CM_ "AUTOGENERATED FILE, DO NOT EDIT";

CM_ "hyundai_reversed_ccnc_canfd.dbc starts here";
VERSION ""

NS_ :

BS_:

BU_: XXX CAMERA FRONT_RADAR ADRV APRK

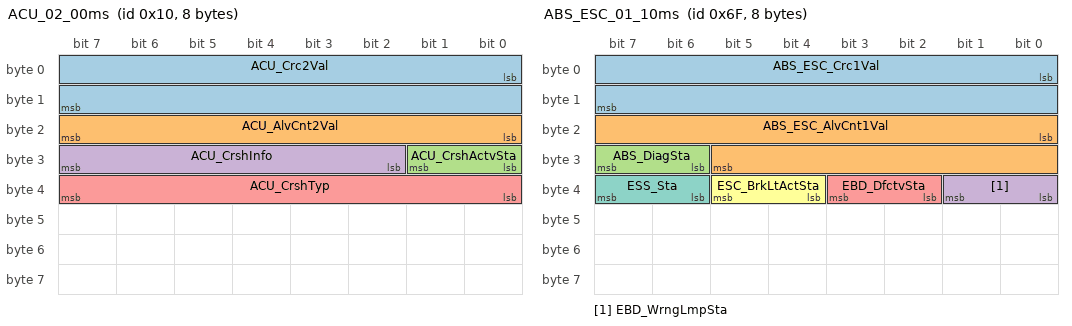
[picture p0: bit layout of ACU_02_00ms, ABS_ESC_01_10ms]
BO_ 16 ACU_02_00ms: 8 XXX
 SG_ ACU_Crc2Val : 0|16@1+ (1,0) [0|65535] "" XXX
 SG_ ACU_AlvCnt2Val : 16|8@1+ (1,0) [0|255] "" XXX
 SG_ ACU_CrshActvSta : 24|2@1+ (1,0) [0|3] "" XXX
 SG_ ACU_CrshInfo : 26|6@1+ (1,0) [0|63] "" XXX
 SG_ ACU_CrshTyp : 32|8@1+ (1,0) [0|255] "" XXX

BO_ 53 VCU_01_10ms: 32 XXX
 SG_ VCU_Crc1Val : 0|16@1+ (1,0) [0|65535] "" XXX
 SG_ VCU_AlvCnt1Val : 16|8@1+ (1,0) [0|255] "" XXX
 SG_ VCU_RdySta : 24|2@1+ (1,0) [0|3] "" XXX
 SG_ VCU_StartKeyHoldSta : 26|2@1+ (1,0) [0|3] "" XXX
 SG_ VCU_EvDrvRdySta : 28|2@1+ (1,0) [0|3] "" XXX
 SG_ VCU_MotPwrEnReq : 30|2@1+ (1,0) [0|3] "" XXX
 SG_ VCU_GearPosSta : 32|4@1+ (1,0) [0|15] "" XXX
 SG_ VCU_LdcInhReq : 36|2@1+ (1,0) [0|3] "" XXX
 SG_ VCU_MainRlyOffReq : 38|2@1+ (1,0) [0|3] "" XXX
 SG_ VCU_AccPedDepVal : 40|8@1+ (1,0) [0|255] "" XXX
 SG_ VCU_FatcOperPermSta : 48|2@1+ (1,0) [0|3] "" XXX
 SG_ VCU_DrvCycSta : 50|2@1+ (1,0) [0|3] "" XXX
 SG_ VCU_CltActOpSta : 52|4@1+ (1,0) [0|15] "" XXX
 SG_ VCU_WhlSpdSnsrAlvReq : 56|2@1+ (1,0) [0|3] "" XXX
 SG_ VCU_DrvModOpSta : 58|6@1+ (1,0) [0|63] "" XXX
 SG_ VCU_FatcPwrUseVal : 64|8@1+ (1,0) [0|255] "" XXX
 SG_ VCU_WhlDemTqVal : 72|16@1+ (1,0) [0|65535] "" XXX
 SG_ VCU_McuAntiJerkInhFrntSta : 88|2@1+ (1,0) [0|3] "" XXX
 SG_ VCU_McuAntiJerkInhRearSta : 90|2@1+ (1,0) [0|3] "" XXX
 SG_ VCU_McuPwrLatchHoldReq : 92|2@1+ (1,0) [0|3] "" XXX
 SG_ VCU_ScuParkReq : 94|2@1+ (1,0) [0|3] "" XXX
 SG_ VCU_MotTqCmdFrntVal : 96|14@1+ (1,0) [0|16383] "" XXX
 SG_ VCU_ScuKeepWakeReq : 110|2@1+ (1,0) [0|3] "" XXX
 SG_ VCU_MotTqCmdRearVal : 112|14@1+ (1,0) [0|16383] "" XXX
 SG_ VCU_FmcuZeroTqOfsReq : 126|2@1+ (1,0) [0|3] "" XXX
 SG_ VCU_EcmSeqSta : 128|8@1+ (1,0) [0|255] "" XXX
 SG_ VCU_EcmDiagSta : 136|8@1+ (1,0) [0|255] "" XXX
 SG_ VCU_CltActDiagSta : 144|8@1+ (1,0) [0|255] "" XXX
 SG_ VCU_CltActDrvCrntVal : 152|12@1+ (1,0) [0|4095] "" XXX
 SG_ VCU_CltActPosStrokeVal : 164|12@1+ (1,0) [0|4095] "" XXX
 SG_ VCU_MainBattTypeSta : 176|2@1+ (1,0) [0|3] "" XXX
 SG_ VCU_MainBattTypeLrnSta : 178|2@1+ (1,0) [0|3] "" XXX
 SG_ VCU_WarmupCycSta : 180|2@1+ (1,0) [0|3] "" XXX
 SG_ VCU_FatcPermPwrVal : 182|10@1+ (1,0) [0|1023] "" XXX
 SG_ VCU_GearPosStaDisp : 192|3@1+ (1,0) [0|7] "" XXX
 SG_ VCU_VgsVirSoundBackFireIndex : 218|6@1+ (1,0) [0|63] "" XXX
 SG_ VCU_VgsVirEngSpdRpmVal : 224|16@1+ (1,0) [0|65535] "" XXX
 SG_ VCU_VgsVirSoundVolume : 240|8@1+ (1,0) [0|255] "" XXX
 SG_ VCU_VgsVirGearStep : 248|8@1+ (1,0) [0|255] "" XXX

BO_ 64 TCU_01_10ms: 32 XXX
 SG_ TCU_Crc1Val : 0|16@1+ (1,0) [0|65535] "" XXX
 SG_ TCU_AlvCnt1Val : 16|8@1+ (1,0) [0|255] "" XXX
 SG_ TCU_GearSlctDis : 32|3@1+ (1,0) [0|7] "" XXX
 SG_ TCU_Typ : 36|4@1+ (1,0) [0|15] "" XXX
 SG_ TCU_TqRdctnVal : 40|16@1+ (1,0) [0|65535] "" XXX
 SG_ TCU_GearStepTyp : 56|4@1+ (1,0) [0|15] "" XXX
 SG_ TCU_GearShftSta : 60|2@1+ (1,0) [0|3] "" XXX
 SG_ TCU_TqCnvrtrSta : 62|2@1+ (1,0) [0|3] "" XXX
 SG_ TCU_CurrGearSta : 64|4@1+ (1,0) [0|15] "" XXX
 SG_ TCU_TrgtGearSta : 68|4@1+ (1,0) [0|15] "" XXX
 SG_ TCU_CluTrgtGearSta : 72|4@1+ (1,0) [0|15] "" XXX
 SG_ TCH_EngTrgtGearSta : 76|4@1+ (1,0) [0|15] "" XXX
 SG_ TCU_EngTqLimVal : 80|16@1+ (1,0) [0|65535] "" XXX
 SG_ TCU_VehSpdKphVal : 96|8@1+ (1,0) [0|255] "" XXX
 SG_ TCU_DcmlVehSpdKphVal : 104|8@1+ (1,0) [0|255] "" XXX
 SG_ TCU_SprkRtrdReq : 112|8@1+ (1,0) [0|255] "" XXX
 SG_ TCU_EngRpmDisSta : 120|2@1+ (1,0) [0|3] "" XXX
 SG_ TCU_GearLmpBlnkngReq : 122|2@1+ (1,0) [0|3] "" XXX
 SG_ TCU_FuelCutInhbtReq : 124|2@1+ (1,0) [0|3] "" XXX
 SG_ TCU_IdleUpReq : 126|2@1+ (1,0) [0|3] "" XXX
 SG_ TCU_EngRpmDis : 128|16@1+ (1,0) [0|65535] "" XXX
 SG_ TCU_SlpVal : 144|6@1+ (1,0) [0|63] "" XXX
 SG_ TCU_EngSpdIncReq : 150|2@1+ (1,0) [0|3] "" XXX
 SG_ TCU_ObdSta : 152|3@1+ (1,0) [0|7] "" XXX
 SG_ TCU_SprtyIndxSta : 155|5@1+ (1,0) [0|31] "" XXX
 SG_ TCU_DrvngModDis : 160|3@1+ (1,0) [0|7] "" XXX
 SG_ TCU_DrvngModReq : 163|3@1+ (1,0) [0|7] "" XXX
 SG_ TCU_SmrtShftSta : 166|2@1+ (1,0) [0|3] "" XXX
 SG_ TCU_LupTrgtEngSpdVal : 168|8@1+ (1,0) [0|255] "" XXX
 SG_ TCU_FrtStcShftSta : 176|2@1+ (1,0) [0|3] "" XXX
 SG_ TCU_IsgInhbtReq : 178|2@1+ (1,0) [0|3] "" XXX
 SG_ TCU_CdaInhbtReq : 180|2@1+ (1,0) [0|3] "" XXX
 SG_ TCU_BrkOnReq : 182|2@1+ (1,0) [0|3] "" XXX
 SG_ TCU_TqGrdntLimVal : 184|8@1+ (1,0) [0|255] "" XXX
 SG_ TCU_NetrlCtrlSta : 192|2@1+ (1,0) [0|3] "" XXX
 SG_ TCU_ShftPtrnSta : 194|4@1+ (1,0) [0|15] "" XXX
 SG_ TCU_VgisInhbtReq : 198|2@1+ (1,0) [0|3] "" XXX
 SG_ TCU_EngTqIncReqVal : 200|12@1+ (1,0) [0|4095] "" XXX
 SG_ TCU_EPBReq : 212|4@1+ (1,0) [0|15] "" XXX

BO_ 69 GEAR: 24 XXX
 SG_ CHECKSUM : 0|16@1+ (1,0) [0|65535] "" XXX
 SG_ COUNTER : 16|8@1+ (1,0) [0|255] "" XXX
 SG_ GEAR : 44|3@1+ (1,0) [0|7] "" XXX

BO_ 74 IMU_01_10ms: 8 XXX
 SG_ IMU_Crc1Val : 0|16@1+ (1,0) [0|65535] "" XXX
 SG_ IMU_AlvCnt1Val : 16|8@1+ (1,0) [0|255] "" XXX
 SG_ IMU_YawSigSta : 24|4@1+ (1,0) [0|15] "" XXX
 SG_ IMU_LatAccelSigSta : 28|4@1+ (1,0) [0|15] "" XXX
 SG_ IMU_LongAccelSigSta : 32|4@1+ (1,0) [0|15] "" XXX
 SG_ IMU_VerAccelSigSta : 36|4@1+ (1,0) [0|15] "" XXX
 SG_ IMU_McuVoltSta : 40|4@1+ (1,0) [0|15] "" XXX
 SG_ IMU_AcuRstSta : 44|4@1+ (1,0) [0|15] "" XXX
 SG_ IMU_SnsrTyp : 48|8@1+ (1,0) [0|255] "" XXX
 SG_ IMU_RollSigSta : 56|8@1+ (1,0) [0|255] "" XXX
 SG_ IMU_YawRtVal : 64|16@1+ (1,0) [0|65535] "" XXX
 SG_ IMU_LatAccelVal : 80|16@1+ (1,0) [0|65535] "" XXX
 SG_ IMU_LongAccelVal : 96|16@1+ (1,0) [0|65535] "" XXX
 SG_ IMU_SnsrTempVal : 112|16@1+ (1,0) [0|65535] "" XXX
 SG_ IMU_SeralNumVal : 128|64@1+ (1,0) [0|1.84467440737096e+19] "" XXX
 SG_ IMU_RollRtVal : 192|16@1+ (1,0) [0|65535] "" XXX
 SG_ IMU_VerAccelVal : 208|8@1+ (1,0) [0|255] "" XXX

BO_ 80 LKAS: 16 XXX
 SG_ CHECKSUM : 0|16@1+ (1,0) [0|65535] "" XXX
 SG_ COUNTER : 16|8@1+ (1,0) [0|255] "" XXX
 SG_ LKA_MODE : 24|3@1+ (1,0) [0|7] "" XXX
 SG_ NEW_SIGNAL_1 : 27|2@1+ (1,0) [0|255] "" XXX
 SG_ LKA_WARNING : 32|1@1+ (1,0) [0|1] "" XXX
 SG_ LKA_ICON : 38|2@1+ (1,0) [0|255] "" XXX
 SG_ FCA_SYSWARN : 40|1@0+ (1,0) [0|1] "" XXX
 SG_ TORQUE_REQUEST : 41|11@1+ (1,-1024) [0|4095] "" XXX
 SG_ STEER_REQ : 52|1@1+ (1,0) [0|1] "" XXX
 SG_ LFA_BUTTON : 56|1@1+ (1,0) [0|255] "" XXX
 SG_ LKA_ASSIST : 62|1@1+ (1,0) [0|1] "" XXX
 SG_ STEER_MODE : 65|3@1+ (1,0) [0|1] "" XXX
 SG_ NEW_SIGNAL_2 : 70|2@0+ (1,0) [0|3] "" XXX
 SG_ HAS_LANE_SAFETY : 80|1@0+ (1,0) [0|1] "" XXX
 SG_ NEW_SIGNAL_3 : 111|8@0+ (1,0) [0|255] "" XXX

BO_ 81 ADRV_0x51: 32 ADRV
 SG_ CHECKSUM : 0|16@1+ (1,0) [0|65535] "" XXX
 SG_ COUNTER : 16|8@1+ (1,0) [0|255] "" XXX

BO_ 96 ESC_01_10ms: 32 XXX
 SG_ ESC_Crc1Val : 0|16@1+ (1,0) [0|65535] "" XXX
 SG_ ESC_AlvCnt1Val : 16|8@1+ (1,0) [0|255] "" XXX
 SG_ TCS_OffLmpSta : 42|2@1+ (1,0) [0|3] "" XXX
 SG_ ESC_OffTempSta : 44|2@1+ (1,0) [0|3] "" XXX
 SG_ ESC_OffSwSta : 46|2@1+ (1,0) [0|3] "" XXX
 SG_ DBC_WrngLmpSta : 48|2@1+ (1,0) [0|3] "" XXX
 SG_ DBC_FuncLmpSta : 50|2@1+ (1,0) [0|3] "" XXX
 SG_ DBC_ClusterDis : 52|2@1+ (1,0) [0|3] "" XXX
 SG_ ESC_SprtLmpSta : 54|2@1+ (1,0) [0|3] "" XXX
 SG_ ESC_BrkCtrlSta : 56|22@1+ (1,0) [0|4194303] "" XXX
 SG_ TCS_PreActvSta : 78|2@1+ (1,0) [0|3] "" XXX
 SG_ DBC_Sta : 80|8@1+ (1,0) [0|255] "" XXX
 SG_ HAC_Sta : 88|6@1+ (1,0) [0|63] "" XXX
 SG_ BJD_Flag : 94|1@1+ (1,0) [0|1] "" XXX
 SG_ TCS_SlwTqFlag : 95|5@1+ (1,0) [0|31] "" XXX
 SG_ TCS_GearShftCharacteristicVal : 100|2@1+ (1,0) [0|3] "" XXX
 SG_ TCS_ManufacturerVal : 102|18@1+ (1,0) [0|262143] "" XXX
 SG_ TCS_SlwTqIntrvntnVal : 120|8@1+ (1,0) [0|255] "" XXX
 SG_ ESC_CylPrsrVal : 128|10@1+ (1,0) [0|65535] "" XXX
 SG_ ESC_CylPrsrSta : 144|2@1+ (1,0) [0|3] "" XXX
 SG_ ESC_CylPrsrDiagSta : 146|2@1+ (1,0) [0|3] "" XXX
 SG_ ESC_CylPrsrFlagSta : 148|1@1+ (1,0) [0|3] "" XXX
 SG_ ESC_VsmActvSta : 152|2@1+ (1,0) [0|3] "" XXX
 SG_ ESC_VsmDfctvSta : 154|2@1+ (1,0) [0|3] "" XXX
 SG_ ESC_VsmCtrlModSta : 156|4@1+ (1,0) [0|15] "" XXX
 SG_ ESC_StrTqReq : 160|16@1+ (1,0) [0|65535] "" XXX
 SG_ ESC_LongAccelOffstCalibPrmtr : 176|15@1+ (1,0) [0|32767] "" XXX
 SG_ ESC_IMURstStaAck : 191|1@1+ (1,0) [0|1] "" XXX
 SG_ AVH_Sta : 192|4@1+ (1,0) [0|15] "" XXX
 SG_ EPB_ActvReq : 196|2@1+ (1,0) [0|3] "" XXX
 SG_ EPB_StaReq : 198|10@1+ (1,0) [0|1023] "" XXX
 SG_ AVH_CluDis : 208|8@1+ (1,0) [0|255] "" XXX
 SG_ AVH_AlrmReq : 216|2@1+ (1,0) [0|3] "" XXX
 SG_ AVH_ActvStaLmpDis : 218|2@1+ (1,0) [0|3] "" XXX
 SG_ AVH_LmpDis : 220|4@1+ (1,0) [0|15] "" XXX
 SG_ AWD_CrdnShftTqLimVal : 224|16@1+ (1,0) [0|65535] "" XXX
 SG_ AWD_CltchDtyLimVal : 240|8@1+ (1,0) [0|255] "" XXX
 SG_ AWD_TransmsnTqLimModSta : 248|2@1+ (1,0) [0|3] "" XXX
 SG_ AWD_RrWhlDtyLimReq : 250|6@1+ (1,0) [0|63] "" XXX

BO_ 101 IEB_01_10ms: 32 XXX
 SG_ IEB_Crc1Val : 0|16@1+ (1,0) [0|65535] "" XXX
 SG_ IEB_AlvCnt1Val : 16|8@1+ (1,0) [0|255] "" XXX
 SG_ IEB_SrvLmpDis : 24|2@1+ (1,0) [0|3] "" XXX
 SG_ IEB_DfctvSta : 26|2@1+ (1,0) [0|3] "" XXX
 SG_ IEB_ActvSta : 28|2@1+ (1,0) [0|3] "" XXX
 SG_ IEB_DiagSta : 30|2@1+ (1,0) [0|3] "" XXX
 SG_ IEB_WrngLmpDis : 32|2@1+ (1,0) [0|3] "" XXX
 SG_ IEB_MILReq : 34|6@1+ (1,0) [0|63] "" XXX
 SG_ IEB_StrkDpthmmVal : 40|16@1- (1,0) [0|65535] "" XXX
 SG_ IEB_BrkActvSta : 56|1@1+ (1,0) [0|1] "" XXX
 SG_ BRAKE_PRESSED : 57|1@1+ (1,0) [0|3] "" XXX
 SG_ IEB_PdlTrvlSnsrFailSta : 58|2@1+ (1,0) [0|3] "" XXX
 SG_ IEB_PdlCalibSta : 60|2@1+ (1,0) [0|3] "" XXX
 SG_ IEB_BzrSta : 62|2@1+ (1,0) [0|3] "" XXX
 SG_ IEB_Sta : 64|2@1+ (1,0) [0|3] "" XXX
 SG_ IEB_SnsrFailSta : 66|2@1+ (1,0) [0|3] "" XXX
 SG_ IEB_RbsWrngLmpSta : 68|2@1+ (1,0) [0|3] "" XXX
 SG_ IEB_VacSysDfctvSta : 70|2@1+ (1,0) [0|3] "" XXX
 SG_ IEB_RegenTqLimitNmVal_Frnt : 72|16@1+ (1,0) [0|65535] "" XXX
 SG_ IEB_EstTtlBrkFrcNmVal : 88|16@1+ (1,0) [0|65535] "" XXX
 SG_ IEB_StrkDpthPcVal : 104|8@1+ (1,0) [0|255] "" XXX
 SG_ IEB_EstDpthPcVal : 112|8@1+ (1,0) [0|255] "" XXX
 SG_ IEB_AbsNGearReq : 120|2@1+ (1,0) [0|3] "" XXX
 SG_ IEB_EstBrkPdlValVldSta : 122|2@1+ (1,0) [0|3] "" XXX
 SG_ IEB_InhbtTrnstnTo4wd_Req : 124|4@1+ (1,0) [0|15] "" XXX
 SG_ IEB_RegenTqLimitNmVal_Rear : 128|24@1+ (1,0) [0|16777215] "" XXX
 SG_ IEB_TCS_Req : 152|2@1+ (1,0) [0|3] "" XXX
 SG_ IEB_RSC_Req : 154|3@1+ (1,0) [0|7] "" XXX
 SG_ TCS_TqFlag_Rear : 157|1@1+ (1,0) [0|1] "" XXX
 SG_ RSC_TqFlag_Frnt : 158|1@1+ (1,0) [0|1] "" XXX
 SG_ RSC_TqFlag_Rear : 159|9@1+ (1,0) [0|511] "" XXX
 SG_ TCS_TqIntrvntnVal_Rear : 168|8@1+ (1,0) [0|255] "" XXX
 SG_ RSC_TqIntrvntnVal_Frnt : 176|8@1+ (1,0) [0|255] "" XXX
 SG_ RSC_TqIntrvntnVal_Rear : 184|40@1+ (1,0) [0|1099511627775] "" XXX
 SG_ IEB_DriftModeSta : 224|2@1+ (1,0) [0|3] "" XXX
 SG_ IEB_DriftModeActSta : 226|6@1+ (1,0) [0|63] "" XXX

BO_ 106 TCU_02_10ms: 8 XXX
 SG_ TCU_Crc3Val : 0|16@1+ (1,0) [0|65535] "" XXX
 SG_ VI_VehImmoReq : 2|24@1+ (1,0) [0|16777215] "" XXX
 SG_ TCU_AlvCnt3Val : 16|8@1+ (1,0) [0|255] "" XXX
 SG_ TCU_WrngMsgSta : 24|13@1+ (1,0) [0|8191] "" XXX
 SG_ VSVI_AlvCntVal : 26|14@1+ (1,0) [0|16383] "" XXX
 SG_ TCU_NCCSetChk : 37|3@1+ (1,0) [0|7] "" XXX
 SG_ TCU_SmartshiftSPTIndex_Long : 40|8@1+ (1,0) [0|255] "" XXX
 SG_ SBW_WrngSndSta : 44|4@1+ (1,0) [0|15] "" XXX
 SG_ TCU_TqCnvrtrSpdVal : 48|16@1+ (1,0) [0|65535] "" XXX
 SG_ ECO_Ig3RlyDrvSta : 52|4@1+ (1,0) [0|15] "" XXX
 SG_ TCU_PrkReleaseReq : 64|2@1+ (1,0) [0|3] "" XXX
 SG_ TCU_InertiaPhaseSta : 66|2@1+ (1,0) [0|3] "" XXX
 SG_ TCU_ActvEcoRdySta : 68|2@1+ (1,0) [0|3] "" XXX
 SG_ TCU_SprtDrvRdySta : 70|4@1+ (1,0) [0|15] "" XXX
 SG_ TCU_RspaSta : 72|4@1+ (1,0) [0|15] "" XXX
 SG_ TCU_CltchDrvngTqVal : 74|10@1+ (1,0) [0|1023] "" XXX
 SG_ TCU_RspaCtrlSta : 76|8@1+ (1,0) [0|255] "" XXX
 SG_ TCU_SbwPrkSta : 84|2@1+ (1,0) [0|3] "" XXX
 SG_ TCU_StallLaunchStat : 86|2@1+ (1,0) [0|3] "" XXX
 SG_ TCU_OilPmpTrgtSpdVal : 88|8@1+ (1,0) [0|255] "" XXX
 SG_ TCU_NPosWshModSta : 91|10@1+ (1,0) [0|1023] "" XXX
 SG_ TCU_GrRatioChngProg : 96|8@1+ (1,0) [0|255] "" XXX
 SG_ TCU_PS_CurveSta : 101|1@1+ (1,0) [0|1] "" XXX
 SG_ TCU_PS_MergeSta : 102|1@1+ (1,0) [0|1] "" XXX
 SG_ TCU_PS_SLimitSta : 103|1@1+ (1,0) [0|1] "" XXX
 SG_ TCU_TgtTurSpd : 104|13@1+ (1,0) [0|8191] "" XXX
 SG_ TCU_PS_DownhillSta : 105|1@1+ (1,0) [0|1] "" XXX
 SG_ TCU_PS_StopsignSta : 106|1@1+ (1,0) [0|1] "" XXX
 SG_ TCU_PS_RoundaboutSta : 107|1@1+ (1,0) [0|1] "" XXX
 SG_ TCU_PS_OthersSta : 108|1@1+ (1,0) [0|1] "" XXX
 SG_ TCU_PS_TestDisplay : 109|4@1+ (1,0) [0|15] "" XXX
 SG_ TCU_PS_Sta : 113|2@1+ (1,0) [0|3] "" XXX
 SG_ TCU_PS_VarIcon : 115|2@1+ (1,0) [0|3] "" XXX
 SG_ TCU_PS_CoastingGuide : 117|3@1+ (1,0) [0|7] "" XXX
 SG_ TCU_NCExitBrk : 119|2@1+ (1,0) [0|3] "" XXX
 SG_ TCU_RevMatchFlag : 121|2@1+ (1,0) [0|3] "" XXX
 SG_ TCU_NCCStat : 123|5@1+ (1,0) [0|31] "" XXX
 SG_ TCU_CVTPumpLoad : 128|8@1+ (1,0) [0|255] "" XXX
 SG_ TCU_EngSpdIncRev : 136|13@1+ (1,0) [0|8191] "" XXX
 SG_ TCU_ShiftTarCls : 149|3@1+ (1,0) [0|7] "" XXX

BO_ 111 ABS_ESC_01_10ms: 8 XXX
 SG_ ABS_ESC_Crc1Val : 0|16@1+ (1,0) [0|65535] "" XXX
 SG_ ABS_ESC_AlvCnt1Val : 16|14@1+ (1,0) [0|16383] "" XXX
 SG_ ABS_DiagSta : 30|2@1+ (1,0) [0|3] "" XXX
 SG_ EBD_WrngLmpSta : 32|2@1+ (1,0) [0|3] "" XXX
 SG_ EBD_DfctvSta : 34|2@1+ (1,0) [0|3] "" XXX
 SG_ ESC_BrkLtActSta : 36|2@1+ (1,0) [0|3] "" XXX
 SG_ ESS_Sta : 38|2@1+ (1,0) [0|3] "" XXX

BO_ 112 GEAR_ALT_2: 32 XXX
 SG_ CHECKSUM : 0|16@1+ (1,0) [0|65535] "" XXX
 SG_ COUNTER : 16|8@1+ (1,0) [0|255] "" XXX
 SG_ GEAR : 60|3@1+ (1,0) [0|7] "" XXX

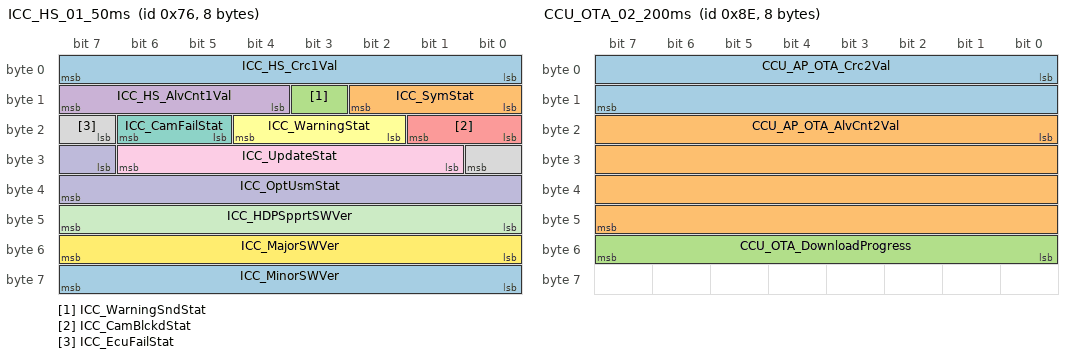
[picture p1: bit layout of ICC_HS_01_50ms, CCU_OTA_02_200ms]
BO_ 118 ICC_HS_01_50ms: 8 XXX
 SG_ ICC_HS_Crc1Val : 0|8@1+ (1,0) [0|255] "" XXX
 SG_ ICC_SymStat : 8|3@1+ (1,0) [0|7] "" XXX
 SG_ ICC_WarningSndStat : 11|1@1+ (1,0) [0|1] "" XXX
 SG_ ICC_HS_AlvCnt1Val : 12|4@1+ (1,0) [0|15] "" XXX
 SG_ ICC_CamBlckdStat : 16|2@1+ (1,0) [0|3] "" XXX
 SG_ ICC_WarningStat : 18|3@1+ (1,0) [0|7] "" XXX
 SG_ ICC_CamFailStat : 21|2@1+ (1,0) [0|3] "" XXX
 SG_ ICC_EcuFailStat : 23|2@1+ (1,0) [0|3] "" XXX
 SG_ ICC_UpdateStat : 25|6@1+ (1,0) [0|63] "" XXX
 SG_ ICC_OptUsmStat : 31|9@1+ (1,0) [0|511] "" XXX
 SG_ ICC_HDPSpprtSWVer : 40|8@1+ (1,0) [0|255] "" XXX
 SG_ ICC_MajorSWVer : 48|8@1+ (1,0) [0|255] "" XXX
 SG_ ICC_MinorSWVer : 56|8@1+ (1,0) [0|255] "" XXX

BO_ 138 CDM_HS_2_01_200ms_CDM_HS: 8 XXX
 SG_ ccIC_HU_Crc1Val : 0|0@1+ (1,0) [0|0] "" XXX
 SG_ RRPSS_Local_AlvCnt1Val : 12|0@1+ (1,0) [0|0] "" XXX
 SG_ ccIC_HU_AlvCnt1Val : 16|0@1+ (1,0) [0|0] "" XXX

BO_ 142 CCU_OTA_02_200ms: 8 XXX
 SG_ CCU_AP_OTA_Crc2Val : 0|16@1+ (1,0) [0|65535] "" XXX
 SG_ CCU_AP_OTA_AlvCnt2Val : 16|32@1+ (1,0) [0|4294967295] "" XXX
 SG_ CCU_OTA_DownloadProgress : 48|8@1+ (1,0) [0|255] "" XXX

BO_ 143 DSAU_04_200ms_DSAU: 8 XXX
 SG_ RRSAU_L_AirSptModeRValueSet : 4|0@1+ (1,0) [0|0] "" XXX
 SG_ RRSAU_L_AirSptStrRValueSet_DASU : 8|0@1+ (1,0) [0|0] "" XXX
 SG_ RRSAU_L_AirSptTimeRValueSet : 12|0@1+ (1,0) [0|0] "" XXX
 SG_ RRSAU_L_BackSoftRValueSet : 32|0@1+ (1,0) [0|0] "" XXX
 SG_ RRSAU_L_ActiveSw_PSS_RR : 35|0@1+ (1,0) [0|0] "" XXX
 SG_ RRSAU_L_MoodTrpyRValueSet : 48|0@1+ (1,0) [0|0] "" XXX
 SG_ RRSAU_L_MoodTrpyCareSta : 50|0@1+ (1,0) [0|0] "" XXX
 SG_ RRSAU_L_MoodTrpyComfSta : 52|0@1+ (1,0) [0|0] "" XXX

BO_ 144 DATC_19_100ms: 8 XXX
 SG_ DATC_Crc19Val : 0|16@1+ (1,0) [0|65535] "" XXX
 SG_ DATC_AlvCnt19Val : 16|8@1+ (1,0) [0|255] "" XXX
 SG_ DATC_ClmtPwrSum_Wh : 24|16@1+ (1,0) [0|65535] "" XXX
 SG_ DATC_BattPwrSum_Wh2 : 40|24@1+ (1,0) [0|16777215] "" XXX
 SG_ DATC_AcnECompCnsmptPwrVal_W : 64|12@1+ (1,0) [0|4095] "" XXX
 SG_ DATC_PtcPwrCnsmptnVal_W : 76|12@1+ (1,0) [0|4095] "" XXX
 SG_ DATC_BattCompPwrCnsmptn_W2 : 88|12@1+ (1,0) [0|4095] "" XXX
 SG_ DATC_ClmtPwrCnsmptn_W : 100|4@1+ (1,0) [0|15] "" XXX

BO_ 154 HU_FPM_E_00_AVN: 8 XXX
 SG_ C_FRU_Random : 0|8@1+ (1,0) [0|255] "" XXX

BO_ 156 HU_FPM_PE_00_AVN: 8 XXX
 SG_ C_FRU_ISKLearnState : 12|2@1+ (1,0) [0|3] "" XXX
 SG_ IAU_ISKLearnState : 14|0@1+ (1,0) [0|0] "" XXX
 SG_ FRU2IAU_H2PV_FPM2IAU : 24|8@1+ (1,0) [0|255] "" XXX

BO_ 160 WHL_01_10ms: 24 XXX
 SG_ WHL_Crc1Val : 0|16@1+ (1,0) [0|65535] "" XXX
 SG_ WHL_AlvCnt1Val : 16|8@1+ (1,0) [0|255] "" XXX
 SG_ WHL_PlsFLVal : 24|8@1+ (1,0) [0|255] "" XXX
 SG_ WHL_PlsFRVal : 32|8@1+ (1,0) [0|255] "" XXX
 SG_ WHL_PlsRLVal : 40|8@1+ (1,0) [0|255] "" XXX
 SG_ WHL_PlsRRVal : 48|8@1+ (1,0) [0|255] "" XXX
 SG_ WHL_DirFLVal : 56|1@0+ (1,0) [0|1] "" XXX
 SG_ MOVING_BACKWARD : 57|1@0+ (1,0) [0|1] "" XXX
 SG_ WHL_DirFRVal : 58|1@0+ (1,0) [0|1] "" XXX
 SG_ MOVING_BACKWARD2 : 59|1@0+ (1,0) [0|1] "" XXX
 SG_ WHL_DirRLVal : 60|2@1+ (1,0) [0|3] "" XXX
 SG_ WHL_DirRRVal : 62|2@1+ (1,0) [0|3] "" XXX
 SG_ WHL_SpdFLVal : 64|16@1+ (0.03125,0) [0|65535] "kph" XXX
 SG_ WHL_SpdFRVal : 80|16@1+ (0.03125,0) [0|65535] "kph" XXX
 SG_ WHL_SpdRLVal : 96|16@1+ (0.03125,0) [0|65535] "kph" XXX
 SG_ WHL_SpdRRVal : 112|16@1+ (0.03125,0) [0|65535] "kph" XXX
 SG_ WHL_SpdCalParmtr : 136|8@1+ (1,0) [0|255] "" XXX

BO_ 165 CC_04_200ms_CC: 8 XXX
 SG_ ccIC_HU_Crc4Val : 0|0@1+ (1,0) [0|0] "" XXX
 SG_ BCM_AlvCnt4Val : 12|4@1+ (1,0) [0|15] "" XXX
 SG_ ccIC_HU_AlvCnt4Val : 16|0@1+ (1,0) [0|0] "" XXX

BO_ 181 EMS_01_10ms: 8 XXX
 SG_ EMS_Crc1Val : 0|16@1+ (1,0) [0|65535] "" XXX
 SG_ EMS_AlvCnt1Val : 16|8@1+ (1,0) [0|255] "" XXX
 SG_ ENG_CrctEngTqVal : 24|16@1+ (1,0) [0|65535] "" XXX
 SG_ ENG_StndTqRatioVal : 40|8@1+ (1,0) [0|255] "" XXX
 SG_ ENG_FrctTqVal : 48|16@1+ (1,0) [0|65535] "" XXX
 SG_ ENG_IndTqVal : 64|16@1+ (1,0) [0|65535] "" XXX
 SG_ ENG_IndTqBVal : 80|16@1+ (1,0) [0|65535] "" XXX
 SG_ ENG_EngSpdErrSta : 96|2@1+ (1,0) [0|3] "" XXX
 SG_ ENG_MafErrSta : 98|2@1+ (1,0) [0|3] "" XXX
 SG_ ENG_EtcLmphModSta : 100|4@1+ (1,0) [0|15] "" XXX
 SG_ ENG_MaxAirconTqVal : 104|8@1+ (1,0) [0|255] "" XXX
 SG_ ENG_AirconPrsrSnsrVal : 112|11@1+ (1,0) [0|2047] "" XXX
 SG_ ENG_IsgSta : 123|3@1+ (1,0) [0|7] "" XXX
 SG_ ENG_OilLvlSta : 126|2@1+ (1,0) [0|3] "" XXX
 SG_ ENG_TrgtIdleRpmVal : 128|8@1+ (1,0) [0|255] "" XXX
 SG_ ENG_GearShftUpDis : 136|2@1+ (1,0) [0|3] "" XXX
 SG_ ENG_GearShftDnDis : 138|2@1+ (1,0) [0|3] "" XXX
 SG_ ENG_DsrGearPosDis : 140|4@1+ (1,0) [0|15] "" XXX
 SG_ ENG_SldFuncSta : 144|2@1+ (1,0) [0|3] "" XXX
 SG_ ENG_SldActnSta : 146|2@1+ (1,0) [0|3] "" XXX
 SG_ ENG_FuelTnkPrsrSta : 148|2@1+ (1,0) [0|3] "" XXX
 SG_ ENG_IsgBzrReq : 150|2@1+ (1,0) [0|3] "" XXX
 SG_ ENG_IsgFuelCnsmptDis : 152|2@1+ (1,0) [0|3] "" XXX
 SG_ ENG_FuelCapOpnSta : 154|2@1+ (1,0) [0|3] "" XXX
 SG_ ENG_EcoDrvActvSta : 156|2@1+ (1,0) [0|3] "" XXX
 SG_ ENG_EngRunSta : 158|2@1+ (1,0) [0|3] "" XXX
 SG_ ENG_Isg2Sta : 160|2@1+ (1,0) [0|3] "" XXX
 SG_ ENG_IgnOnSta : 162|2@1+ (1,0) [0|3] "" XXX
 SG_ ENG_Ack4TcsSta : 164|2@1+ (1,0) [0|3] "" XXX
 SG_ ENG_FuelCutOffSta : 166|2@1+ (1,0) [0|3] "" XXX
 SG_ ENG_CrctTqSta : 168|2@1+ (1,0) [0|3] "" XXX
 SG_ ENG_AirCompRlySta : 170|3@1+ (1,0) [0|7] "" XXX
 SG_ ENG_LnchCntrlSta : 173|3@1+ (1,0) [0|7] "" XXX
 SG_ ENG_EngSpdVal : 176|24@1+ (1,0) [0|16777215] "" XXX
 SG_ ENG_FuelCnsmptVal : 200|16@1+ (1,0) [0|65535] "" XXX
 SG_ ENG_TrgtFuelPmpPrsrVal : 216|8@1+ (1,0) [0|255] "" XXX
 SG_ ENG_VehSpdHiVal : 224|11@1+ (1,0) [0|2047] "" XXX
 SG_ ENG_SldSwSta : 235|2@1+ (1,0) [0|3] "" XXX
 SG_ ENG_SldDrvAlertDisp : 237|10@1+ (1,0) [0|1023] "" XXX
 SG_ ENG_VehSpdLimVal : 247|1@1+ (1,0) [0|1] "" XXX

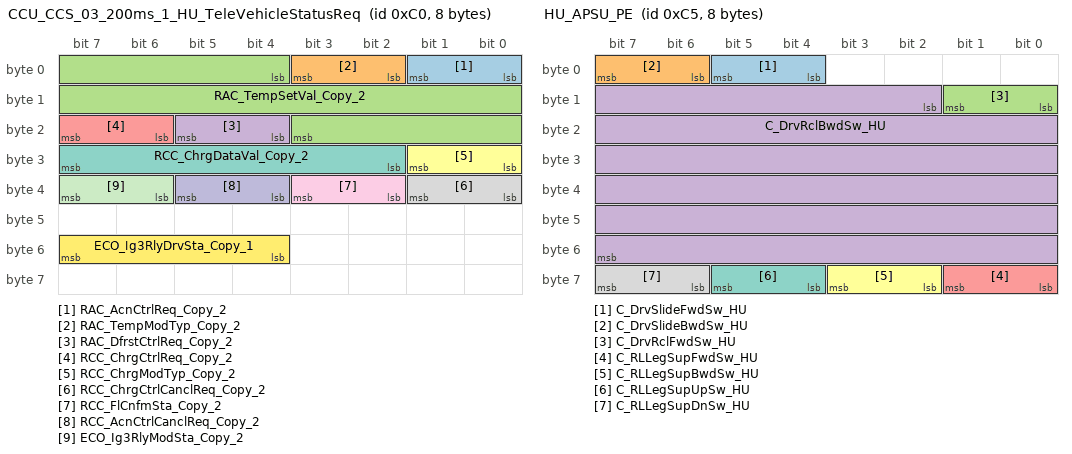
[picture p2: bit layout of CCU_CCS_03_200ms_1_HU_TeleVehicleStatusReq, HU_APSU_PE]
BO_ 192 CCU_CCS_03_200ms_1_HU_TeleVehicleStatusReq: 8 XXX
 SG_ RAC_AcnCtrlReq_Copy_2 : 0|2@1+ (1,0) [0|3] "" XXX
 SG_ RAC_TempModTyp_Copy_2 : 2|2@1+ (1,0) [0|3] "" XXX
 SG_ RAC_TempSetVal_Copy_2 : 4|16@1+ (1,0) [0|65535] "" XXX
 SG_ RAC_DfrstCtrlReq_Copy_2 : 20|2@1+ (1,0) [0|3] "" XXX
 SG_ RCC_ChrgCtrlReq_Copy_2 : 22|2@1+ (1,0) [0|3] "" XXX
 SG_ RCC_ChrgModTyp_Copy_2 : 24|2@1+ (1,0) [0|3] "" XXX
 SG_ RCC_ChrgDataVal_Copy_2 : 26|6@1+ (1,0) [0|63] "" XXX
 SG_ RCC_ChrgCtrlCanclReq_Copy_2 : 32|2@1+ (1,0) [0|3] "" XXX
 SG_ RCC_FlCnfmSta_Copy_2 : 34|2@1+ (1,0) [0|3] "" XXX
 SG_ RCC_AcnCtrlCanclReq_Copy_2 : 36|2@1+ (1,0) [0|3] "" XXX
 SG_ ECO_Ig3RlyModSta_Copy_2 : 38|2@1+ (1,0) [0|3] "" XXX
 SG_ ECO_Ig3RlyDrvSta_Copy_1 : 52|4@1+ (1,0) [0|15] "" XXX

BO_ 197 HU_APSU_PE: 8 XXX
 SG_ C_DrvSlideFwdSw_HU : 4|2@1+ (1,0) [0|3] "" XXX
 SG_ C_DrvSlideBwdSw_HU : 6|2@1+ (1,0) [0|3] "" XXX
 SG_ C_DrvRclFwdSw_HU : 8|2@1+ (1,0) [0|3] "" XXX
 SG_ C_DrvRclBwdSw_HU : 10|46@1+ (1,0) [0|70368744177663] "" XXX
 SG_ C_RLLegSupFwdSw_HU : 56|2@1+ (1,0) [0|3] "" XXX
 SG_ C_RLLegSupBwdSw_HU : 58|2@1+ (1,0) [0|3] "" XXX
 SG_ C_RLLegSupUpSw_HU : 60|2@1+ (1,0) [0|3] "" XXX
 SG_ C_RLLegSupDnSw_HU : 62|2@1+ (1,0) [0|3] "" XXX

BO_ 198 HU_GW_E: 8 XXX
 SG_ HU_StrgWhlHeatingSet_VR : 3|5@1+ (1,0) [0|31] "" XXX
 SG_ AVN_VGS_SET : 8|8@1+ (1,0) [0|255] "" XXX

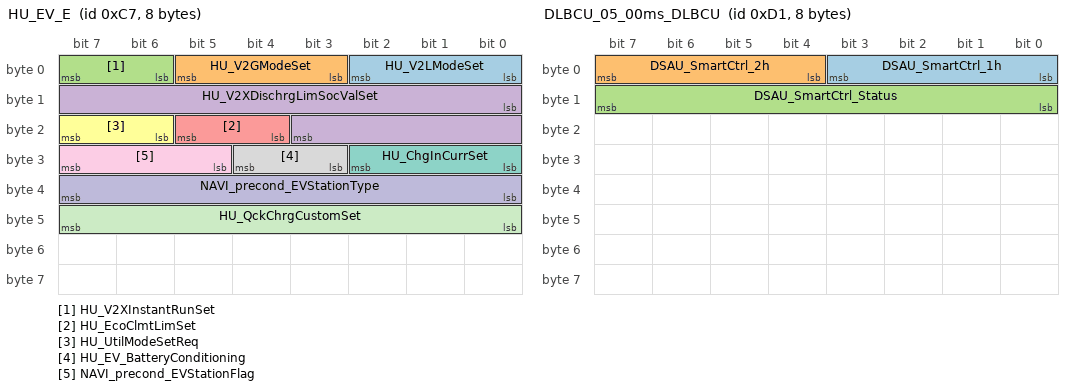
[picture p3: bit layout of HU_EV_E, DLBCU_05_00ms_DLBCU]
BO_ 199 HU_EV_E: 8 XXX
 SG_ HU_V2LModeSet : 0|3@1+ (1,0) [0|7] "" XXX
 SG_ HU_V2GModeSet : 3|3@1+ (1,0) [0|7] "" XXX
 SG_ HU_V2XInstantRunSet : 6|2@1+ (1,0) [0|3] "" XXX
 SG_ HU_V2XDischrgLimSocValSet : 8|12@1+ (1,0) [0|4095] "" XXX
 SG_ HU_EcoClmtLimSet : 20|2@1+ (1,0) [0|3] "" XXX
 SG_ HU_UtilModeSetReq : 22|2@1+ (1,0) [0|3] "" XXX
 SG_ HU_ChgInCurrSet : 24|3@1+ (1,0) [0|7] "" XXX
 SG_ HU_EV_BatteryConditioning : 27|2@1+ (1,0) [0|3] "" XXX
 SG_ NAVI_precond_EVStationFlag : 29|3@1+ (1,0) [0|7] "" XXX
 SG_ NAVI_precond_EVStationType : 32|8@1+ (1,0) [0|255] "" XXX
 SG_ HU_QckChrgCustomSet : 40|8@1+ (1,0) [0|255] "" XXX

BO_ 200 HU_USM_E1: 8 XXX
 SG_ CF_AVN_ADrLNValueSet_2 : 0|3@1+ (1,0) [0|7] "" XXX
 SG_ USM_PwrDrBuzzerNValueSet : 3|4@1+ (1,0) [0|15] "" XXX
 SG_ CF_AVN_FCA_FrOnOffEquipNvalueSet : 7|2@1+ (1,0) [0|3] "" XXX
 SG_ CF_AVN_FCA_WarnTimeNvalueSet : 9|3@1+ (1,0) [0|7] "" XXX
 SG_ CF_AVN_FCA_JC_OnOffEquipNvalueSet : 12|2@1+ (1,0) [0|3] "" XXX
 SG_ CF_AVN_FCA_FrSdOnOffEquipNvalueSet : 14|2@1+ (1,0) [0|3] "" XXX
 SG_ CF_AVN_LKA_OnOffEquip2NvalueSet : 16|2@1+ (1,0) [0|3] "" XXX
 SG_ CF_AVN_BCA_OnOffEquip2NvalueSet : 18|2@1+ (1,0) [0|3] "" XXX
 SG_ CF_AVN_BVM_OnOffEquipNvalueSet : 20|2@1+ (1,0) [0|3] "" XXX
 SG_ CF_AVN_SEA_OnOffEquip3NvalueSet : 22|2@1+ (1,0) [0|3] "" XXX
 SG_ CF_AVN_BodySpprtSet_AST : 24|2@1+ (1,0) [0|3] "" XXX
 SG_ CF_AVN_SEW_OnOffEquip3NvalueSet : 26|2@1+ (1,0) [0|3] "" XXX
 SG_ CF_AVN_HudImsAutoSave : 28|2@1+ (1,0) [0|3] "" XXX
 SG_ CF_AVN_DWLNValueSet : 30|3@1+ (1,0) [0|7] "" XXX
 SG_ CF_AVN_AirSptTimeNValueSet_AST : 33|3@1+ (1,0) [0|7] "" XXX
 SG_ CF_AVN_AirSptStrNValue_AST : 36|2@1+ (1,0) [0|3] "" XXX
 SG_ CF_AVN_SeatDrvModNvalueSet_AST : 38|2@1+ (1,0) [0|3] "" XXX
 SG_ CF_AVN_TPMS_TireReplaceNValueSet : 40|3@1+ (1,0) [0|7] "" XXX
 SG_ CF_AVN_TowModeSet : 43|3@1+ (1,0) [0|7] "" XXX
 SG_ USM_PwrDrCloseByBraekNValueSet : 46|4@1+ (1,0) [0|15] "" XXX
 SG_ CF_AVN_ISLANAOffstNvalueSet : 50|6@1+ (1,0) [0|63] "" XXX
 SG_ USM_DrvGhostDoorReq : 56|2@1+ (1,0) [0|3] "" XXX
 SG_ USM_AstGhostDoorReq : 58|2@1+ (1,0) [0|3] "" XXX
 SG_ USM_RLGhostDoorReq : 60|2@1+ (1,0) [0|3] "" XXX
 SG_ USM_RRGhostDoorReq : 62|2@1+ (1,0) [0|3] "" XXX

BO_ 203 ADAS_CMD_35_10ms: 24 CGW_CCU
 SG_ ADAS_CMD_Crc35Val : 0|16@1+ (1,0) [0|0] "0" FCU_C,GW_RGW,MDPS,SFA
 SG_ ADAS_CMD_AlvCnt35Val : 16|8@1+ (1,0) [0|0] "0" FCU_C,GW_RGW,MDPS,SFA
 SG_ ADAS_ActvACISta : 24|4@1+ (1,0) [0|0] "" GW_RGW,MDPS,SFA
 SG_ ADAS_ActvACILvl2Sta : 28|4@1+ (1,0) [0|0] "" ESC,FCU_C,GW_RGW,MDPS,SFA,VPC_C
 SG_ ADAS_StrAnglReqVal : 32|14@1- (0.1,0) [0|0] "Deg" GW_RGW,MDPS,SFA
 SG_ ADAS_ACIAnglTqRedcGainVal : 48|8@1+ (0.004,0) [0|0] "" GW_RGW,MDPS,SFA
 SG_ FCA_ESA_ActvSta : 56|2@1+ (1,0) [0|0] "" GW_RGW,MDPS,SFA
 SG_ FCA_ESA_TqBstGainVal : 64|8@1+ (0.004,0) [0|0] "" GW_RGW,MDPS,SFA

BO_ 209 DLBCU_05_00ms_DLBCU: 8 XXX
 SG_ DSAU_SmartCtrl_1h : 0|4@1+ (1,0) [0|15] "" XXX
 SG_ DSAU_SmartCtrl_2h : 4|4@1+ (1,0) [0|15] "" XXX
 SG_ DSAU_SmartCtrl_Status : 8|8@1+ (1,0) [0|255] "" XXX

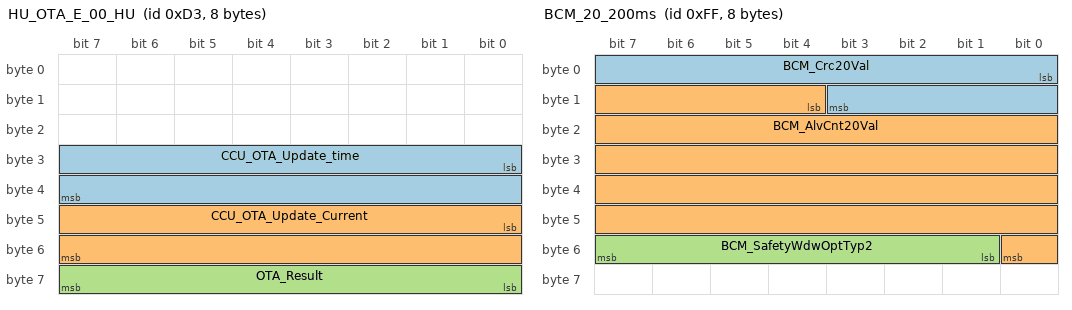
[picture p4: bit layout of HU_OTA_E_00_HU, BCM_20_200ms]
BO_ 211 HU_OTA_E_00_HU: 8 XXX
 SG_ CCU_OTA_Update_time : 24|16@1+ (1,0) [0|65535] "" XXX
 SG_ CCU_OTA_Update_Current : 40|16@1+ (1,0) [0|65535] "" XXX
 SG_ OTA_Result : 56|8@1+ (1,0) [0|255] "" XXX

BO_ 234 MDPS_01_10ms: 24 XXX
 SG_ MDPS_Crc1Val : 0|16@1+ (1,0) [0|65535] "" XXX
 SG_ MDPS_AlvCnt1Val : 16|8@1+ (1,0) [0|255] "" XXX
 SG_ MDPS_WrngLmpSta : 24|3@1+ (1,0) [0|7] "" XXX
 SG_ MDPS_Typ : 27|3@1+ (1,0) [0|7] "" XXX
 SG_ MDPS_EngIdleRpmReq : 30|2@1+ (1,0) [0|3] "" XXX
 SG_ MDPS_VsmPlgInSta : 32|2@1+ (1,0) [0|3] "" XXX
 SG_ MDPS_VsmDfctvSta : 34|2@1+ (1,0) [0|3] "" XXX
 SG_ MDPS_VsmSigErrSta : 36|2@1+ (1,0) [0|3] "" XXX
 SG_ MDPS_PaPlugInSta : 38|2@1+ (1,0) [0|3] "" XXX
 SG_ MDPS_PaModeSta : 40|4@1+ (1,0) [0|15] "" XXX
 SG_ MDPS_PaCanfltSta : 44|2@1+ (1,0) [0|3] "" XXX
 SG_ MDPS_LkaPlgInSta : 46|2@1+ (1,0) [0|3] "" XXX
 SG_ MDPS_LkaToiActvSta : 48|1@0+ (1,0) [0|16777215] "" XXX
 SG_ MDPS_LkaToiUnblSta : 50|2@1+ (1,0) [0|3] "" XXX
 SG_ MDPS_LkaToiFltSta : 52|2@1+ (1,0) [0|3] "" XXX
 SG_ MDPS_LkaFailSta : 54|1@0+ (1,0) [0|1] "" XXX
 SG_ MDPS_CurrModVal : 61|3@1+ (1,0) [0|7] "" XXX
 SG_ MDPS_OutTqVal : 64|12@1+ (0.1,-204.8) [0|65535] "" XXX
 SG_ MDPS_VsmActResp : 76|4@1+ (1,0) [0|15] "" XXX
 SG_ MDPS_StrTqSnsrVal : 80|13@1+ (1,-4095) [0|4095] "" XXX
 SG_ MDPS_PaStrAnglVal : 96|16@1- (-0.1,0) [0|255] "deg" XXX
 SG_ MDPS_LoamModSta : 112|2@1+ (1,0) [0|3] "" XXX
 SG_ MDPS_HDPSpprtSWVer : 114|6@1+ (1,0) [0|63] "" XXX
 SG_ MDPS_ADASAciActvSta : 120|6@1+ (1,0) [0|63] "" XXX
 SG_ MDPS_ADAS_AciFltSig : 126|2@1+ (1,0) [0|3] "" XXX
 SG_ MDPS_EstStrAnglVal : 128|16@1- (-0.1,0) [0|65535] "deg" XXX
 SG_ MDPS_ADASAciActvSta_Lv2 : 144|4@1+ (1,0) [0|15] "" XXX
 SG_ MDPS_ADAS_AciFltSig_Lv2 : 148|4@1+ (1,0) [0|15] "" XXX

BO_ 240 ICC_HS_01_50ms_ICC: 8 XXX
 SG_ HU_DSW_LeftEyeOpenStat : 8|8@1+ (1,0) [0|255] "" XXX
 SG_ HU_DSW_RightEyeOpenStat : 16|28@1+ (1,0) [0|268435455] "" XXX
 SG_ HU_DSW_TalkStat : 44|9@1+ (1,0) [0|511] "" XXX
 SG_ HU_DSW_EyeStat : 53|3@1+ (1,0) [0|7] "" XXX
 SG_ RWS_HDPSpprtSWVer : 91|30@1+ (1,0) [0|1073741823] "" XXX
 SG_ TCU_HDPSpprtSWVer : 121|7@1+ (1,0) [0|127] "" XXX

BO_ 255 BCM_20_200ms: 8 XXX
 SG_ BCM_Crc20Val : 0|12@1+ (1,0) [0|4095] "" XXX
 SG_ BCM_AlvCnt20Val : 12|37@1+ (1,0) [0|137438953471] "" XXX
 SG_ BCM_SafetyWdwOptTyp2 : 49|7@1+ (1,0) [0|127] "" XXX

BO_ 256 EMS_02_10ms: 32 XXX
 SG_ EMS_Crc2Val : 0|16@1+ (1,0) [0|65535] "" XXX
 SG_ EMS_AlvCnt2Val : 16|8@1+ (1,0) [0|255] "" XXX
 SG_ ENG_BrkSwSta : 32|1@1+ (1,0) [0|1] "" XXX
 SG_ ENG_ObdFrzFrmSta : 34|6@1+ (1,0) [0|63] "" XXX
 SG_ ENG_EngClntTempVal : 40|8@1+ (1,0) [0|255] "" XXX
 SG_ ENG_MafCrctVal : 48|8@1+ (1,0) [0|255] "" XXX
 SG_ ENG_BattDscnctSta : 56|2@1+ (1,0) [0|3] "" XXX
 SG_ OBD_MilConfgVal : 58|3@1+ (1,0) [0|7] "" XXX
 SG_ ENG_EngSta : 61|3@1+ (1,0) [0|7] "" XXX
 SG_ ENG_Ack4EngStpSta : 64|2@1+ (1,0) [0|3] "" XXX
 SG_ ENG_OverDrvOffReq : 66|2@1+ (1,0) [0|3] "" XXX
 SG_ ENG_AccActSta : 68|2@1+ (1,0) [0|3] "" XXX
 SG_ ENG_CltchOpSta : 70|2@1+ (1,0) [0|3] "" XXX
 SG_ EMS_BrkReq_Slope : 72|2@1+ (1,0) [0|3] "" XXX
 SG_ ENG_AccDrvAlertDisp : 74|6@1+ (1,0) [0|63] "" XXX
 SG_ ENG_ThrPosVal : 80|8@1+ (1,0) [0|255] "" XXX
 SG_ ENG_AccelPdlVal : 88|16@1+ (1,0) [0|65535] "" XXX
 SG_ ACC_CrsMainSwLmpSta : 104|2@1+ (1,0) [0|3] "" XXX
 SG_ ACC_CrsSetSwLmpSta : 106|4@1+ (1,0) [0|15] "" XXX
 SG_ ENG_SoakTimeErrSta : 110|2@1+ (1,0) [0|3] "" XXX
 SG_ ENG_SoakTimeVal : 112|8@1+ (1,0) [0|255] "" XXX
 SG_ ENG_SprkTimeVal : 120|8@1+ (1,0) [0|255] "" XXX
 SG_ ENG_MinIndTqVal : 128|16@1+ (1,0) [0|65535] "" XXX
 SG_ ENG_TrgtTqVal : 144|16@1+ (1,0) [0|65535] "" XXX
 SG_ ENG_MaxIndTqVal : 160|16@1+ (1,0) [0|65535] "" XXX
 SG_ ENG_AppAccelPdlSta : 176|1@1+ (1,0) [0|1] "" XXX
 SG_ ENG_BrkCtrlReq : 178|2@1+ (1,0) [0|3] "" XXX
 SG_ ACC_DnShftCtrlReq : 180|12@1+ (1,0) [0|4095] "" XXX
 SG_ ENG_DclBrkCntrlReq : 192|12@1+ (1,0) [0|4095] "" XXX
 SG_ ENG_BstPrsrVal : 204|12@1+ (1,0) [0|4095] "" XXX
 SG_ ENG_EngOilTempVal : 216|8@1+ (1,0) [0|255] "" XXX
 SG_ ENG_AmbtTempModelVal : 224|8@1+ (1,0) [0|255] "" XXX
 SG_ ENG_DpfWrngSta : 232|2@1+ (1,0) [0|3] "" XXX
 SG_ ENG_BattWrngLmpSta : 234|2@1+ (1,0) [0|3] "" XXX
 SG_ ENG_OilPrsrWrngLmpSta : 236|2@1+ (1,0) [0|3] "" XXX
 SG_ ENG_IsgInhbtLmpSta : 238|2@1+ (1,0) [0|3] "" XXX

BO_ 261 ACCELERATOR_ALT: 32 XXX
 SG_ CHECKSUM : 0|16@1+ (1,0) [0|65535] "" XXX
 SG_ COUNTER : 16|8@1+ (1,0) [0|255] "" XXX
 SG_ ACCELERATOR_PEDAL : 103|10@1+ (0.25,0) [0|1022] "" XXX

BO_ 266 MCU_01_10ms: 8 XXX
 SG_ MCU_Crc1Val : 0|16@1+ (1,0) [0|65535] "" XXX
 SG_ MCU_AlvCnt1Val : 16|8@1+ (1,0) [0|255] "" XXX
 SG_ MCU_Mg1ActlRotatSpdRpmVal : 24|16@1+ (1,0) [0|65535] "" XXX
 SG_ MCU_Mg1EstTqPcVal : 40|16@1+ (1,0) [0|65535] "" XXX
 SG_ MCU_Mg1InvtCtrlRdySta : 56|2@1+ (1,0) [0|3] "" XXX
 SG_ MCU_Mg1CtrlablSta : 58|2@1+ (1,0) [0|3] "" XXX
 SG_ MCU_Mg1WrngSta : 60|2@1+ (1,0) [0|3] "" XXX
 SG_ MCU_Mg1FltSta : 62|2@1+ (1,0) [0|3] "" XXX
 SG_ MCU_Mg1DeratingFctrPcVal : 64|10@1+ (1,0) [0|1023] "" XXX
 SG_ MCU_Mg1TqUppLimMtrngPcVal : 74|10@1+ (1,0) [0|1023] "" XXX
 SG_ MCU_Mg1TqUppLimGenPcVal : 84|12@1+ (1,0) [0|4095] "" XXX
 SG_ MCU_Mg1InvtTempVal : 96|8@1+ (1,0) [0|255] "" XXX
 SG_ MCU_Mg1TempVal : 104|8@1+ (1,0) [0|255] "" XXX
 SG_ MCU_Mg1IgbtJnctnTempVal : 112|8@1+ (1,0) [0|255] "" XXX
 SG_ MCU_Mg1HtsnkTempVal : 120|8@1+ (1,0) [0|255] "" XXX
 SG_ MCU_Mg1InvtInVoltVal : 128|16@1+ (1,0) [0|65535] "" XXX
 SG_ MCU_Mg1EstTqBfrAjPcVal : 144|16@1+ (1,0) [0|65535] "" XXX
 SG_ MCU_Mg1MainRlyCutOffReq : 160|2@1+ (1,0) [0|3] "" XXX
 SG_ MCU_Mg1MainRlyCutOffDelayReq : 162|2@1+ (1,0) [0|3] "" XXX
 SG_ MCU_Mg1PwmOnSta : 164|2@1+ (1,0) [0|3] "" XXX
 SG_ MCU_Mg1HiVoltIntlkReq : 166|2@1+ (1,0) [0|3] "" XXX
 SG_ MCU_Mg1MilOnReq : 168|2@1+ (1,0) [0|3] "" XXX
 SG_ MCU_Mg1SrvLmpOnReq : 170|2@1+ (1,0) [0|3] "" XXX
 SG_ MCU_Mg1SpdLimSta : 172|2@1+ (1,0) [0|3] "" XXX
 SG_ MCU_Mg1EngSpdLimReq : 174|2@1+ (1,0) [0|3] "" XXX
 SG_ MCU_Mg1AnkJrkActvSta : 176|2@1+ (1,0) [0|3] "" XXX
 SG_ MCU_Mg1ActnTestModSta : 178|2@1+ (1,0) [0|3] "" XXX
 SG_ MCU_Mg1PwmRetryStatus : 180|2@1+ (1,0) [0|3] "" XXX
 SG_ MCU_Mg1TrqCmdStat : 182|2@1+ (1,0) [0|3] "" XXX
 SG_ MCU_Mg1RsvrCalibReq : 184|2@1+ (1,0) [0|3] "" XXX
 SG_ MCU_Mg1RsvrCalibProcSta : 186|2@1+ (1,0) [0|3] "" XXX
 SG_ MCU_Mg1RsvrCalibSta : 188|4@1+ (1,0) [0|15] "" XXX
 SG_ MCU_Mg1EstTqVal : 192|16@1+ (1,0) [0|65535] "" XXX
 SG_ MCU_Mg1RadPwmDtyReq : 208|16@1+ (1,0) [0|65535] "" XXX
 SG_ MCU_Mg1EstTqBfrAjVal : 224|14@1+ (1,0) [0|16383] "" XXX
 SG_ MCU_Mg1TqUppLimMtrngVal : 238|9@1+ (1,0) [0|511] "" XXX
 SG_ MCU_Mg1TqUppLimGenVal : 247|1@1+ (1,0) [0|1] "" XXX

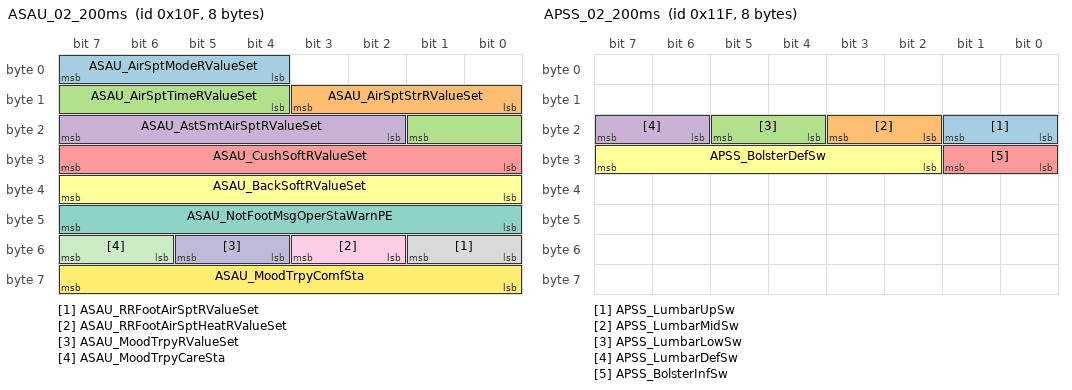
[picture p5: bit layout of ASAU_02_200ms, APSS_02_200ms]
BO_ 271 ASAU_02_200ms: 8 XXX
 SG_ ASAU_AirSptModeRValueSet : 4|4@1+ (1,0) [0|15] "" XXX
 SG_ ASAU_AirSptStrRValueSet : 8|4@1+ (1,0) [0|15] "" XXX
 SG_ ASAU_AirSptTimeRValueSet : 12|6@1+ (1,0) [0|63] "" XXX
 SG_ ASAU_AstSmtAirSptRValueSet : 18|6@1+ (1,0) [0|63] "" XXX
 SG_ ASAU_CushSoftRValueSet : 24|8@1+ (1,0) [0|255] "" XXX
 SG_ ASAU_BackSoftRValueSet : 32|8@1+ (1,0) [0|255] "" XXX
 SG_ ASAU_NotFootMsgOperStaWarnPE : 40|8@1+ (1,0) [0|255] "" XXX
 SG_ ASAU_RRFootAirSptRValueSet : 48|2@1+ (1,0) [0|3] "" XXX
 SG_ ASAU_RRFootAirSptHeatRValueSet : 50|2@1+ (1,0) [0|3] "" XXX
 SG_ ASAU_MoodTrpyRValueSet : 52|2@1+ (1,0) [0|3] "" XXX
 SG_ ASAU_MoodTrpyCareSta : 54|2@1+ (1,0) [0|3] "" XXX
 SG_ ASAU_MoodTrpyComfSta : 56|8@1+ (1,0) [0|255] "" XXX

BO_ 272 ESC_06_200ms: 32 XXX
 SG_ ESC_Crc6Val : 0|16@1+ (1,0) [0|65535] "" XXX
 SG_ ESC_AlvCnt6Val : 16|8@1+ (1,0) [0|255] "" XXX
 SG_ IEB_BrkMod_Sta : 24|3@1+ (1,0) [0|7] "" XXX
 SG_ IEB_BrkMod_Type : 27|2@1+ (1,0) [0|255] "" XXX
 SG_ LKA_WARNING : 32|1@1+ (1,0) [0|1] "" XXX
 SG_ LKA_ICON : 38|2@1+ (1,0) [0|255] "" XXX
 SG_ FCA_SYSWARN : 40|1@0+ (1,0) [0|1] "" XXX
 SG_ TORQUE_REQUEST : 41|11@1+ (1,-1024) [0|4095] "" XXX
 SG_ STEER_REQ : 52|1@1+ (1,0) [0|1] "" XXX
 SG_ LFA_BUTTON : 56|1@1+ (1,0) [0|255] "" XXX
 SG_ LKA_ASSIST : 62|1@1+ (1,0) [0|1] "" XXX
 SG_ STEER_MODE : 65|3@1+ (1,0) [0|1] "" XXX
 SG_ NEW_SIGNAL_2 : 70|2@0+ (1,0) [0|3] "" XXX
 SG_ HAS_LANE_SAFETY : 80|1@0+ (1,0) [0|1] "" XXX
 SG_ NEW_SIGNAL_3 : 111|8@0+ (1,0) [0|255] "" XXX

BO_ 282 FR_CMR_01_10ms: 8 XXX
 SG_ FR_CMR_Crc1Val : 0|16@1+ (1,0) [0|65535] "" XXX
 SG_ FR_CMR_AlvCnt1Val : 16|8@1+ (1,0) [0|255] "" XXX
 SG_ HBA_SysOptSta : 24|2@1+ (1,0) [0|3] "" XXX
 SG_ HBA_SysSta : 26|3@1+ (1,0) [0|7] "" XXX
 SG_ HBA_IndLmpReq : 29|3@1+ (1,0) [0|7] "" XXX
 SG_ FR_CMR_FCA_Plus_Sta : 32|3@1+ (1,0) [0|7] "" XXX
 SG_ FR_CMR_EMTrgtVldSta : 35|4@1+ (1,0) [0|15] "" XXX
 SG_ FCA_Equip_FR_CMR : 39|3@1+ (1,0) [0|7] "" XXX
 SG_ HBA_OptUsmSta : 42|2@1+ (1,0) [0|3] "" XXX
 SG_ FR_CMR_WndshldHtngReqSta : 44|4@1+ (1,0) [0|15] "" XXX
 SG_ DAW_LVDA_PUDis : 48|2@1+ (1,0) [0|3] "" XXX
 SG_ DAW_LVDA_OptUsmSta : 50|2@1+ (1,0) [0|3] "" XXX
 SG_ DAW_OptUsmSta : 52|3@1+ (1,0) [0|7] "" XXX
 SG_ DAW_SysSta : 55|4@1+ (1,0) [0|15] "" XXX
 SG_ DAW_WrnMsgSta : 59|13@1+ (1,0) [0|8191] "" XXX
 SG_ FR_CMR_FCAEquipSta : 72|2@1+ (1,0) [0|3] "" XXX
 SG_ FR_CMR_MDPSCtrlSta : 74|9@1+ (1,0) [0|511] "" XXX
 SG_ PRVECS_CodedSta : 83|2@1+ (1,0) [0|3] "" XXX
 SG_ FR_CMR_SCCEquipSta : 85|11@1+ (1,0) [0|2047] "" XXX
 SG_ FR_CMR_ReqADASMapMsgVal : 96|16@1+ (1,0) [0|65535] "" XXX
 SG_ FR_CMR_SwVer1Val : 112|8@1+ (1,0) [0|255] "" XXX
 SG_ FR_CMR_SwVer2Val : 120|8@1+ (1,0) [0|255] "" XXX

BO_ 287 APSS_02_200ms: 8 XXX
 SG_ APSS_LumbarUpSw : 16|2@1+ (1,0) [0|3] "" XXX
 SG_ APSS_LumbarMidSw : 18|2@1+ (1,0) [0|3] "" XXX
 SG_ APSS_LumbarLowSw : 20|2@1+ (1,0) [0|3] "" XXX
 SG_ APSS_LumbarDefSw : 22|2@1+ (1,0) [0|3] "" XXX
 SG_ APSS_BolsterInfSw : 24|2@1+ (1,0) [0|3] "" XXX
 SG_ APSS_BolsterDefSw : 26|6@1+ (1,0) [0|63] "" XXX

BO_ 288 MCU_02_10ms: 8 XXX
 SG_ MCU_Mg2ActlRotatSpdRpmVal : 24|16@1+ (1,0) [0|65535] "" XXX
 SG_ MCU_Mg2EstTqPcVal : 40|10@1+ (1,0) [0|1023] "" XXX
 SG_ MCU_Mg2FricTqVal : 50|6@1+ (1,0) [0|63] "" XXX
 SG_ MCU_Mg2InvtRdySta : 56|2@1+ (1,0) [0|3] "" XXX
 SG_ MCU_Mg2CtrlablSta : 58|2@1+ (1,0) [0|3] "" XXX
 SG_ MCU_Mg2WrngSta : 60|2@1+ (1,0) [0|3] "" XXX
 SG_ MCU_Mg2FltSta : 62|2@1+ (1,0) [0|3] "" XXX
 SG_ MCU_Mg2DeratingFctrPcVal : 64|10@1+ (1,0) [0|1023] "" XXX
 SG_ MCU_Mg2TqUpLimMPcVal : 74|10@1+ (1,0) [0|1023] "" XXX
 SG_ MCU_Mg2TqUpLimGPcVal : 84|12@1+ (1,0) [0|4095] "" XXX
 SG_ MCU_Mg2InvtTempVal : 96|8@1+ (1,0) [0|255] "" XXX
 SG_ MCU_Mg2TempVal : 104|8@1+ (1,0) [0|255] "" XXX
 SG_ MCU_Mg2IgbtJnctnTempVal : 112|8@1+ (1,0) [0|255] "" XXX
 SG_ MCU_Mg2HtsnkTempVal : 120|8@1+ (1,0) [0|255] "" XXX
 SG_ MCU_Mg2InvtInVoltVal : 128|16@1+ (1,0) [0|65535] "" XXX
 SG_ MCU_Mg2EstTqBfrAjPcVal : 144|16@1+ (1,0) [0|65535] "" XXX
 SG_ MCU_Mg2MainRlyCutOffReq : 160|2@1+ (1,0) [0|3] "" XXX
 SG_ MCU_Mg2MainRlyCutOffDelayReq : 162|2@1+ (1,0) [0|3] "" XXX
 SG_ MCU_Mg2PwmOnSta : 164|2@1+ (1,0) [0|3] "" XXX
 SG_ MCU_Mg2HiVoltIntlkReq : 166|2@1+ (1,0) [0|3] "" XXX
 SG_ MCU_Mg2MilOnReq : 168|2@1+ (1,0) [0|3] "" XXX
 SG_ MCU_Mg2SrvLmpOnReq : 170|2@1+ (1,0) [0|3] "" XXX
 SG_ MCU_Mg2SpdLimSta : 172|2@1+ (1,0) [0|3] "" XXX
 SG_ MCU_Mg2EngSpdLim : 174|2@1+ (1,0) [0|3] "" XXX
 SG_ MCU_Mg2AnkJrkActvSta : 176|2@1+ (1,0) [0|3] "" XXX
 SG_ MCU_Mg2ActnTestModSta : 178|2@1+ (1,0) [0|3] "" XXX
 SG_ MCU_Mg2PwmRetryStatus : 180|2@1+ (1,0) [0|3] "" XXX
 SG_ MCU_Mg2TrqCmdStat : 182|2@1+ (1,0) [0|3] "" XXX
 SG_ MCU_Mg2RsvrCalibReq : 184|2@1+ (1,0) [0|3] "" XXX
 SG_ MCU_Mg2RsvrCalibProcSta : 186|2@1+ (1,0) [0|3] "" XXX
 SG_ MCU_Mg2RsvrCalibSta : 188|4@1+ (1,0) [0|15] "" XXX
 SG_ MCU_Mg2EstTqVal : 192|14@1+ (1,0) [0|16383] "" XXX
 SG_ MCU_Mg2EngOnReq : 206|2@1+ (1,0) [0|3] "" XXX
 SG_ MCU_Mg2RadPwmDtyReq : 208|16@1+ (1,0) [0|65535] "" XXX
 SG_ MCU_Mg2EstBfrAjVal : 224|14@1+ (1,0) [0|16383] "" XXX
 SG_ MCU_Mg2TqUppLimMtrngVal : 238|9@1+ (1,0) [0|511] "" XXX
 SG_ MCU_Mg2TqUppLimGenVal : 247|1@1+ (1,0) [0|1] "" XXX

BO_ 293 SAS_01_10ms: 16 XXX
 SG_ SAS_Crc1Val : 0|16@1+ (1,0) [0|65535] "" XXX
 SG_ SAS_AlvCnt1Val : 16|8@1+ (1,0) [0|255] "" XXX
 SG_ SAS_AnglVal : 24|16@1- (-0.1,0) [0|255] "deg" XXX
 SG_ SAS_SpdVal : 40|8@1+ (4,0) [0|1016] "deg/s" XXX
 SG_ SAS_IntSta : 48|8@1+ (1,0) [0|255] "" XXX

BO_ 298 ADAS_CMD_30_10ms: 16 ADRV
 SG_ ADAS_CMD_Crc30Val : 0|16@1+ (1,0) [0|65535] "" ADRV
 SG_ ADAS_CMD_AlvCnt30Val : 16|8@1+ (1,0) [0|255] "" ADRV
 SG_ LKA_OptUsmSta : 24|3@1+ (1,0) [0|7] "" ADRV
 SG_ LKA_RcgSta : 27|2@1+ (1,0) [0|255] "" ADRV
 SG_ LKA_LHLnWrnSta : 30|2@1+ (1,0) [0|3] "" ADRV
 SG_ LKA_RHLnWrnSta : 32|1@1+ (1,0) [0|1] "" ADRV
 SG_ LKA_HndsoffSnd : 34|4@1+ (1,0) [0|15] "" ADRV
 SG_ LKA_SysIndReq : 38|2@1+ (1,0) [0|255] "" ADRV
 SG_ ADAS_StrTqReqVal : 41|11@1+ (1,-1024) [0|4095] "" ADRV
 SG_ ADAS_ActToiSta : 52|1@1+ (1,0) [0|1] "" ADRV
 SG_ ADAS_ToiFltSta : 54|2@1+ (1,0) [0|3] "" ADRV
 SG_ LFA_BUTTON : 56|1@1+ (1,0) [0|255] "" ADRV
 SG_ LKA_SysWrn : 60|2@1+ (1,0) [0|3] "" ADRV
 SG_ LKA_ASSIST : 62|1@1+ (1,0) [0|1] "" ADRV
 SG_ FCA_LO_WrnSta : 64|1@1+ (1,0) [0|1] "" ADRV
 SG_ STEER_MODE : 65|3@1+ (1,0) [0|1] "" ADRV
 SG_ FCA_LS_WrnSta : 68|2@1+ (1,0) [0|3] "" ADRV
 SG_ NEW_SIGNAL_2 : 70|2@0+ (1,0) [0|3] "" ADRV
 SG_ SCC_TakeoverReq_CLU_AMP_PE_02_Warn_Sound : 72|8@1+ (1,0) [0|255] "" ADRV
 SG_ LKA_UsmMod : 80|1@0+ (1,0) [0|1] "" ADRV
 SG_ ELK_SysFlrSta : 85|5@1+ (1,0) [0|31] "" ADRV
 SG_ ELK_SymbDisp : 90|3@1+ (1,0) [0|7] "" ADRV
 SG_ FCA_ESA_WrnSta : 93|8@1+ (1,0) [0|255] "" ADRV
 SG_ FCA_ESA_CtrlSta : 101|3@1+ (1,0) [0|7] "" ADRV
 SG_ ADAS_Damping_Gain : 104|7@1+ (1,0) [0|127] "" ADRV
 SG_ NEW_SIGNAL_3 : 111|8@0+ (1,0) [0|255] "" ADRV

BO_ 304 SMK_05_200ms_SMK: 16 XXX
 SG_ CHECKSUM : 0|16@1+ (1,0) [0|65535] "" XXX
 SG_ COUNTER : 16|8@1+ (1,0) [0|255] "" XXX
 SG_ SBW_BrkSwSta : 30|2@1+ (1,0) [0|3] "" XXX
 SG_ PARK_BUTTON : 32|2@1+ (1,0) [0|3] "" XXX
 SG_ KNOB_POSITION : 40|3@1+ (1,0) [0|3] "" XXX
 SG_ GEAR : 64|3@1+ (1,0) [0|7] "" XXX

BO_ 319 FPM_01_00ms: 8 XXX
 SG_ FPM_Random : 16|8@1+ (1,0) [0|255] "" XXX

BO_ 325 DATC_01_20ms: 8 XXX
 SG_ DATC_Crc1Val : 0|16@1+ (1,0) [0|65535] "" XXX
 SG_ DATC_AlvCnt1Val : 16|11@1+ (1,0) [0|2047] "" XXX
 SG_ DATC_ManufacturerTyp : 27|5@1+ (1,0) [0|31] "" XXX
 SG_ DATC_AcnCompTyp : 32|8@1+ (1,0) [0|255] "" XXX
 SG_ DATC_AcnReq : 40|2@1+ (1,0) [0|3] "" XXX
 SG_ DATC_BlwSta : 42|2@1+ (1,0) [0|3] "" XXX
 SG_ DATC_BlwMaxSta : 44|8@1+ (1,0) [0|255] "" XXX
 SG_ DATC_SrvLmpReq : 52|12@1+ (1,0) [0|4095] "" XXX
 SG_ DATC_AcnECompOpSta : 64|2@1+ (1,0) [0|3] "" XXX
 SG_ DATC_AcnCompFltSta : 66|8@1+ (1,0) [0|255] "" XXX
 SG_ DATC_HVCompIntlkSta : 74|2@1+ (1,0) [0|3] "" XXX
 SG_ DATC_HVIntDischrgLkReq : 76|2@1+ (1,0) [0|3] "" XXX
 SG_ DATC_AcnECompMaxReqPwrVal : 78|24@1+ (1,0) [0|16777215] "" XXX
 SG_ DATC_BattChlrVlvSta : 102|2@1+ (1,0) [0|3] "" XXX
 SG_ DATC_AcnECompSpdVal : 104|16@1+ (1,0) [0|65535] "" XXX
 SG_ DATC_AcnCompSlpModCodVal : 120|8@1+ (1,0) [0|255] "" XXX
 SG_ DATC_AcnCompWaitCodVal : 128|16@1+ (1,0) [0|65535] "" XXX
 SG_ DATC_PeEwpRPMReq : 144|16@1+ (1,0) [0|65535] "" XXX
 SG_ DATC_RadFanReq_Duty : 160|8@1+ (1,0) [0|255] "" XXX
 SG_ DATC_OutTempSnsrVal : 168|14@1+ (1,0) [0|16383] "" XXX
 SG_ DATC_BattChlrVlv_FltCode : 182|2@1+ (1,0) [0|3] "" XXX
 SG_ DATC_BattEvapVlvSta : 184|2@1+ (1,0) [0|3] "" XXX
 SG_ DATC_BattEvapVlv_FltCode : 186|14@1+ (1,0) [0|16383] "" XXX
 SG_ DATC_BattEwpOpReq : 200|18@1+ (1,0) [0|262143] "" XXX
 SG_ DATC_BlwrLvl : 218|4@1+ (1,0) [0|15] "" XXX
 SG_ DATC_AAFOpenReq : 222|2@1+ (1,0) [0|3] "" XXX

BO_ 335 FPM_02_00ms: 8 XXX
 SG_ FPM_Encrypted_Result1 : 0|8@1+ (1,0) [0|255] "" XXX

BO_ 336 BMS_10_100ms: 8 XXX
 SG_ BMS_Crc10Val : 0|16@1+ (1,0) [0|65535] "" XXX
 SG_ BMS_AlvCnt10Val : 16|8@1+ (1,0) [0|255] "" XXX
 SG_ CHRG_StndChrgTrgtSocVal_SYNC : 24|8@1+ (1,0) [0|255] "" XXX
 SG_ CHRG_QuickTrgtSocVal_SYNC : 32|8@1+ (1,0) [0|255] "" XXX
 SG_ CHRG_GPSChrgTrgtSocVal_SYNC : 40|8@1+ (1,0) [0|255] "" XXX
 SG_ CHRG_V2XDischrgLimSocVal_SYNC : 48|8@1+ (1,0) [0|255] "" XXX
 SG_ xEV_BattTempMainMaxVal : 56|8@1+ (1,0) [0|255] "" XXX
 SG_ xEV_BattTempMainMinVal : 64|8@1+ (1,0) [0|255] "" XXX
 SG_ xEV_BattTempSubMaxVal : 72|8@1+ (1,0) [0|255] "" XXX
 SG_ xEV_BattTempSubMinVal : 80|16@1+ (1,0) [0|65535] "" XXX
 SG_ VCRM_QchChrgRmnTimeValCustom : 96|8@1+ (1,0) [0|255] "" XXX

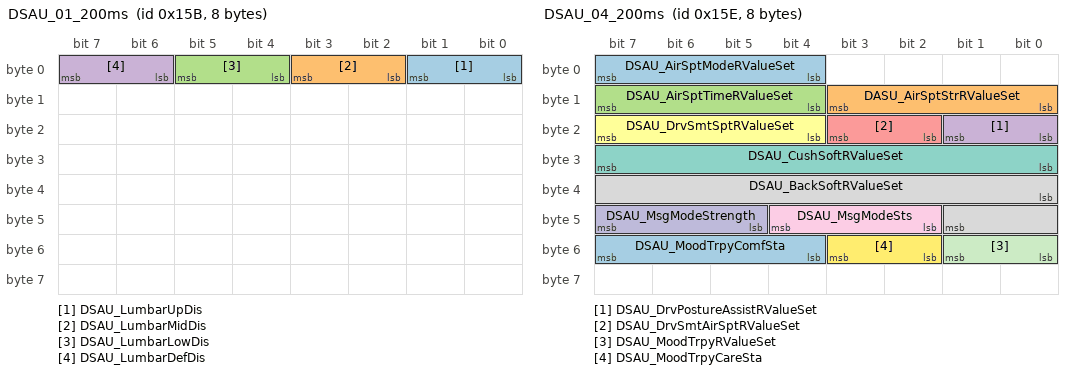
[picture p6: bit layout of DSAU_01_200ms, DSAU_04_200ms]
BO_ 347 DSAU_01_200ms: 8 XXX
 SG_ DSAU_LumbarUpDis : 0|2@1+ (1,0) [0|3] "" XXX
 SG_ DSAU_LumbarMidDis : 2|2@1+ (1,0) [0|3] "" XXX
 SG_ DSAU_LumbarLowDis : 4|2@1+ (1,0) [0|3] "" XXX
 SG_ DSAU_LumbarDefDis : 6|2@1+ (1,0) [0|3] "" XXX

BO_ 348 DSAU_02_200ms: 8 XXX
 SG_ DSAU_BolsterInfDis : 0|2@1+ (1,0) [0|3] "" XXX
 SG_ DSAU_BolsterDefDis : 2|6@1+ (1,0) [0|63] "" XXX

BO_ 349 DSAU_03_200ms: 8 XXX
 SG_ DSAU_CushInfDis : 0|2@1+ (1,0) [0|3] "" XXX
 SG_ DSAU_CushDefDis : 2|6@1+ (1,0) [0|63] "" XXX

BO_ 350 DSAU_04_200ms: 8 XXX
 SG_ DSAU_AirSptModeRValueSet : 4|4@1+ (1,0) [0|15] "" XXX
 SG_ DASU_AirSptStrRValueSet : 8|4@1+ (1,0) [0|15] "" XXX
 SG_ DSAU_AirSptTimeRValueSet : 12|4@1+ (1,0) [0|15] "" XXX
 SG_ DSAU_DrvPostureAssistRValueSet : 16|2@1+ (1,0) [0|3] "" XXX
 SG_ DSAU_DrvSmtAirSptRValueSet : 18|2@1+ (1,0) [0|3] "" XXX
 SG_ DSAU_DrvSmtSptRValueSet : 20|4@1+ (1,0) [0|15] "" XXX
 SG_ DSAU_CushSoftRValueSet : 24|8@1+ (1,0) [0|255] "" XXX
 SG_ DSAU_BackSoftRValueSet : 32|10@1+ (1,0) [0|1023] "" XXX
 SG_ DSAU_MsgModeSts : 42|3@1+ (1,0) [0|7] "" XXX
 SG_ DSAU_MsgModeStrength : 45|3@1+ (1,0) [0|7] "" XXX
 SG_ DSAU_MoodTrpyRValueSet : 48|2@1+ (1,0) [0|3] "" XXX
 SG_ DSAU_MoodTrpyCareSta : 50|2@1+ (1,0) [0|3] "" XXX
 SG_ DSAU_MoodTrpyComfSta : 52|4@1+ (1,0) [0|15] "" XXX

BO_ 351 FPM_03_00ms: 8 XXX
 SG_ FPM_Encrypted_Result2 : 0|8@1+ (1,0) [0|255] "" XXX

BO_ 352 ADAS_CMD_10_20ms: 16 XXX
 SG_ ADAS_CMD_Crc10Val : 0|16@1+ (1,0) [0|65535] "" XXX
 SG_ ADAS_CMD_AlvCnt10Val : 16|8@1+ (1,0) [0|255] "" XXX
 SG_ FCA_OnOffEquipSta : 24|2@1+ (1,0) [0|255] "" XXX
 SG_ FCA_SysFlrSta : 27|3@1+ (1,0) [0|7] "" XXX
 SG_ FCA_WrngLvlSta : 30|2@1+ (1,0) [0|3] "" XXX
 SG_ FCA_VehStpReq : 32|2@1+ (1,0) [0|3] "" XXX
 SG_ FCA_StbltActvReq : 34|3@1+ (1,0) [0|7] "" XXX
 SG_ FCA_HydrlcBstAsstReq : 37|3@1+ (1,0) [0|7] "" XXX
 SG_ FCA_DclReqVal : 40|8@1+ (1,0) [0|255] "" XXX
 SG_ FCA_PrefillActvReq : 48|2@1+ (1,0) [0|3] "" XXX
 SG_ FCA_PartialActvReq : 50|2@1+ (1,0) [0|3] "" XXX
 SG_ FCA_FullActvReq : 52|2@1+ (1,0) [0|3] "" XXX
 SG_ FCA_Regulation : 54|2@1+ (1,0) [0|3] "" XXX
 SG_ FCA_SnstvtyModRetVal : 56|5@1+ (1,0) [0|1] "" XXX
 SG_ FCA_WrngSndSta : 61|3@1+ (1,0) [0|7] "" XXX
 SG_ FCA_RelVel : 64|8@1+ (1,0) [0|255] "" XXX
 SG_ SET_ME_FC : 72|1@1+ (1,0) [0|1] "" XXX
 SG_ FCA_TimetoCllsn : 73|7@1+ (1,0) [0|127] "" XXX
 SG_ SET_ME_9 : 80|3@1+ (1,0) [0|7] "" XXX
 SG_ FCA_Jnctn_OnOffEquipSta : 83|2@1+ (1,0) [0|3] "" XXX
 SG_ HDP_EMOpSta : 85|3@1+ (1,0) [0|7] "" XXX
 SG_ FCA_WrngTrgtDis : 88|5@1+ (1,0) [0|31] "" XXX
 SG_ ADAS_DRV_FCA_Plus_Sta : 93|5@1+ (1,0) [0|31] "" XXX
 SG_ FCA_FrOnOffEquipSta : 98|2@1+ (1,0) [0|3] "" XXX
 SG_ FCA_JC_OnOffEquipSta : 100|2@1+ (1,0) [0|3] "" XXX
 SG_ FCA_FrSdOnOffEquipSta : 102|2@1+ (1,0) [0|3] "" XXX
 SG_ EM_WrngLvlSta : 104|3@1+ (1,0) [0|7] "" XXX
 SG_ BrkDelVLimReq : 107|5@1+ (1,0) [0|31] "" XXX
 SG_ ADAS_InhbtOffDispSta : 112|3@1+ (1,0) [0|7] "" XXX
 SG_ FCA_WarnTimeSta : 115|5@1+ (1,0) [0|31] "" XXX

BO_ 357 ADAS_PRK_20_20ms: 24 XXX
 SG_ ADAS_PRK_Crc2Val : 0|16@1+ (1,0) [0|65535] "" XXX
 SG_ ADAS_PRK_AlvCnt2Val : 16|8@1+ (1,0) [0|0] "" XXX
 SG_ PA_ModDis : 24|3@1+ (1,0) [0|7] "" XXX
 SG_ PA_ModSelSeqDis : 27|3@1+ (1,0) [0|7] "" XXX
 SG_ PA_RSPA_Opt : 30|2@1+ (1,0) [0|3] "" XXX
 SG_ PA_HmiStaDis : 32|8@1+ (1,0) [0|255] "" XXX
 SG_ PA_FrLtWrngDis : 40|3@1+ (1,0) [0|7] "" XXX
 SG_ PA_FrCtWrngDis : 43|5@1+ (1,0) [0|31] "" XXX
 SG_ PA_FrRtWrngDis : 48|3@1+ (1,0) [0|7] "" XXX
 SG_ PA_RrLtWrngDis : 51|5@1+ (1,0) [0|31] "" XXX
 SG_ PA_RrCtWrngDis : 56|3@1+ (1,0) [0|7] "" XXX
 SG_ PA_RrRtWrngDis : 59|5@1+ (1,0) [0|31] "" XXX
 SG_ PA_BpAlrmReq : 64|5@1+ (1,0) [0|31] "" XXX
 SG_ PA_AlrmVlmLvlReq : 69|3@1+ (1,0) [0|7] "" XXX
 SG_ PA_AlrmVlmDeratingReq : 72|2@1+ (1,0) [0|3] "" XXX
 SG_ PA_FrWrngAlrmReq : 74|6@1+ (1,0) [0|63] "" XXX
 SG_ PA_FrCtWrngAlrmReq : 80|8@1+ (1,0) [0|255] "" XXX
 SG_ PCA_LtWrngDis_PDW : 88|2@1+ (1,0) [0|3] "" XXX
 SG_ PCA_RtWrngDis_PDW : 90|2@1+ (1,0) [0|0] "" XXX
 SG_ PCA_LtRrWrngDis_PA : 92|2@1+ (1,0) [0|3] "" XXX
 SG_ PCA_RtRrWrngDis_PA : 94|2@1+ (1,0) [0|3] "" XXX
 SG_ PA_StrAnglReq : 96|16@1- (0.1,0) [0|0] "" XXX
 SG_ PA_LtFrWrngDis : 120|3@1+ (1,0) [0|7] "" XXX
 SG_ PA_RtFrWrngDis : 123|5@1+ (1,0) [0|31] "" XXX
 SG_ PA_LtWrngDis : 128|3@1+ (1,0) [0|7] "" XXX
 SG_ PA_RtWrngDis : 131|5@1+ (1,0) [0|31] "" XXX
 SG_ PA_LtRrWrngDis : 136|3@1+ (1,0) [0|7] "" XXX
 SG_ PA_RtRrWrngDis : 139|5@1+ (1,0) [0|31] "" XXX

BO_ 362 ADAS_PRK_21_20ms: 32 XXX
 SG_ ADAS_PRK_Crc3Val : 0|16@1+ (1,0) [0|65535] "" XXX
 SG_ ADAS_PRK_AlvCnt3Val : 16|8@1+ (1,0) [0|0] "" XXX
 SG_ RSPA_AvnDis : 24|2@1+ (1,0) [0|3] "" XXX
 SG_ RSPA_AvnModDis : 26|6@1+ (1,0) [0|63] "" XXX
 SG_ RSPA_AvnSubViewDis : 32|24@1+ (1,0) [0|16777215] "" XXX
 SG_ RSPA_AvnHmiDis : 56|56@1+ (1,0) [0|7.20575940379279e+16] "" XXX
 SG_ RSPA_Var : 112|12@1+ (1,0) [0|4095] "" XXX
 SG_ RSPA_Actv : 124|2@1+ (1,0) [0|3] "" XXX
 SG_ RSPA_EvasiveStrBtnDis : 126|2@1+ (1,0) [0|3] "" XXX
 SG_ RSPA_TrgtGearSta : 128|3@1+ (1,0) [0|7] "" XXX
 SG_ RSPA_EpbReq : 131|2@1+ (1,0) [0|3] "" XXX
 SG_ RSPA_ExtLampReq : 133|3@1+ (1,0) [0|0] "" XXX
 SG_ RSPA_CrankingReq : 136|2@1+ (1,0) [0|3] "" XXX
 SG_ RSPA_IdOutWarnReq : 138|2@1+ (1,0) [0|3] "" XXX
 SG_ RSPA_IndBlnkReq : 140|3@1+ (1,0) [0|7] "" XXX
 SG_ RSPA_SysOff : 143|1@1+ (1,0) [0|1] "" XXX
 SG_ RSPA_DccCmd : 144|2@1+ (1,0) [0|3] "" XXX
 SG_ RSPA_StopReq : 146|2@1+ (1,0) [0|3] "" XXX
 SG_ RSPA_SelDevInfo : 148|2@1+ (1,0) [0|3] "" XXX
 SG_ RSPA_SelFuncInfo : 150|2@1+ (1,0) [0|3] "" XXX
 SG_ RSPA_TrgtVehSpdVal : 152|10@1+ (1,0) [0|1023] "" XXX
 SG_ RSPA_AddtnlAccelActv : 162|2@1+ (1,0) [0|3] "" XXX
 SG_ RSPA_Opt : 164|2@1+ (1,0) [0|3] "" XXX
 SG_ RSPA_RmtPrlExitDis : 166|2@1+ (1,0) [0|3] "" XXX
 SG_ RSPA_TrgtTqVal : 168|12@1+ (1,0) [0|4095] "" XXX
 SG_ RSPA_UppLtTypDis : 180|3@1+ (1,0) [0|7] "" XXX
 SG_ RSPA_LwrLtTypDis : 183|3@1+ (1,0) [0|7] "" XXX
 SG_ RSPA_UppRtTypDis : 186|3@1+ (1,0) [0|7] "" XXX
 SG_ RSPA_LwrRtTypDis : 189|3@1+ (1,0) [0|7] "" XXX
 SG_ RSPA_DCTTrgtTqVal : 192|48@1+ (1,0) [0|281474976710655] "" XXX
 SG_ RSPA_HdLmpReq : 240|8@1+ (1,0) [0|255] "" XXX
 SG_ RSPA_OSMirFoldReq : 248|8@1+ (1,0) [0|255] "" XXX

BO_ 368 ADAS_PRK_10_20ms: 8 XXX
 SG_ ADAS_PRK_Crc1Val : 0|16@1+ (1,0) [0|65535] "" XXX
 SG_ ADAS_PRK_AlvCnt1Val : 16|8@1+ (1,0) [0|255] "" XXX
 SG_ PCA_RrEquipSta : 24|4@1+ (1,0) [0|15] "" XXX
 SG_ PCA_SysFlrSta : 28|4@1+ (1,0) [0|15] "" XXX
 SG_ PCA_RrWrngLvlSta : 32|4@1+ (1,0) [0|15] "" XXX
 SG_ PCA_ModDis : 36|10@1+ (1,0) [0|1023] "" XXX
 SG_ PCA_HptReq : 46|2@1+ (1,0) [0|3] "" XXX
 SG_ PCA_BrkReq : 48|2@1+ (1,0) [0|3] "" XXX
 SG_ PCA_EpbReq : 50|2@1+ (1,0) [0|3] "" XXX
 SG_ PCA_DclTrgtVal : 52|10@1+ (1,0) [0|1023] "" XXX
 SG_ ADAS_PRK_PDW_SysFlrSta : 62|2@1+ (1,0) [0|3] "" XXX
 SG_ ADAS_PRK_PDW_SwIndOnReq : 64|2@1+ (1,0) [0|3] "" XXX
 SG_ ADAS_PRK_PDW_OptTyp : 66|3@1+ (1,0) [0|7] "" XXX
 SG_ ADAS_PRK_PDW_AutoOn_USM : 69|3@1+ (1,0) [0|7] "" XXX
 SG_ PCA_FrSdEquipChkSta : 72|2@1+ (1,0) [0|3] "" XXX
 SG_ PCA_RrEquipChkSta : 74|6@1+ (1,0) [0|63] "" XXX

BO_ 373 ESC_03_20ms: 24 XXX
 SG_ ESC_Crc3Val : 0|16@1+ (1,0) [0|65535] "" XXX
 SG_ ESC_AlvCnt3Val : 16|8@1+ (1,0) [0|255] "" XXX
 SG_ NEW_SIGNAL_4 : 24|7@1+ (1,0) [0|127] "" XXX
 SG_ ESC_VehAccelVal : 32|11@1+ (0.01,-10.23) [0|7] "m/s^2" XXX
 SG_ ESC_AccelBasisVal : 48|11@1- (1,0) [0|1023] "" XXX
 SG_ EQUIP_MAYBE : 64|1@0+ (1,0) [0|1] "" XXX
 SG_ ACCEnable : 67|1@0+ (1,0) [0|1] "" XXX
 SG_ ACC_REQ : 68|1@0+ (1,0) [0|1] "" XXX
 SG_ ESC_StdStillVal : 72|1@0+ (1,0) [0|1] "" XXX
 SG_ ESC_BrkLtReq : 74|1@0+ (1,0) [0|1] "" XXX
 SG_ ESC_DclEnblReq : 76|1@0+ (1,0) [0|1] "" XXX
 SG_ ESC_DrvOvrdSta : 80|1@0+ (1,0) [0|1] "" XXX
 SG_ DriverBraking : 81|1@0+ (1,0) [0|1] "" XXX
 SG_ ESC_DrvBrkSta : 82|2@1+ (1,0) [0|3] "" XXX
 SG_ ESC_DrvBrkActvSta : 84|1@1+ (1,0) [0|1] "" XXX
 SG_ ESC_PrkBrkActvSta : 86|2@1+ (1,0) [0|3] "" XXX
 SG_ ESC_HDP_FltMonSta : 88|3@1+ (1,0) [0|7] "" XXX
 SG_ ESC_HDPSpprtSWVer : 91|5@1+ (1,0) [0|31] "" XXX
 SG_ AEB_EQUIP_MAYBE : 96|1@0+ (1,0) [0|1] "" XXX
 SG_ ESC_FCA_ActvSta : 100|2@1+ (1,0) [0|3] "" XXX
 SG_ ESC_DBS_ActvSta : 102|2@1+ (1,0) [0|3] "" XXX
 SG_ ESC_HDP_EgSta : 104|3@1+ (1,0) [0|7] "" XXX
 SG_ ESC_HDP_EnblReq : 107|21@1+ (1,0) [0|2097151] "" XXX
 SG_ ESC_RccaSta : 128|2@1+ (1,0) [0|3] "" XXX
 SG_ ESC_PcaSta : 130|2@1+ (1,0) [0|3] "" XXX
 SG_ ESC_DiffBrkFuncSta : 132|2@1+ (1,0) [0|3] "" XXX
 SG_ ESC_BcaRPlusSta : 134|1@1+ (1,0) [0|1] "" XXX
 SG_ NEW_SIGNAL_7 : 135|1@0+ (1,0) [0|1] "" XXX
 SG_ ESC_RspaSta : 136|2@1+ (1,0) [0|3] "" XXX
 SG_ ESC_RspaCanFlFlag : 140|4@1+ (1,0) [0|15] "" XXX
 SG_ ESC_RspaDclActv : 144|2@1+ (1,0) [0|3] "" XXX
 SG_ ESC_RspaStandStill : 146|14@1+ (1,0) [0|16383] "" XXX
 SG_ MCB_ReqBrkAck : 160|2@1+ (1,0) [0|3] "" XXX
 SG_ MCB_CtlSta : 162|1@1+ (1,0) [0|1] "" XXX
 SG_ MCB_DefSta : 163|5@1+ (1,0) [0|31] "" XXX

BO_ 378 ECS_02_20ms: 8 XXX
 SG_ ECS_Crc2Val : 0|16@1+ (1,0) [0|65535] "" XXX
 SG_ ECS_AlvCnt2Val : 16|8@1+ (1,0) [0|255] "" XXX
 SG_ ECS_ALS_FLHghtVal : 24|8@1+ (1,0) [0|255] "" XXX
 SG_ ECS_ALS_FRHghtVal : 32|8@1+ (1,0) [0|255] "" XXX
 SG_ ECS_ALS_RLHghtVal : 40|8@1+ (1,0) [0|255] "" XXX
 SG_ ECS_ALS_RRHghtVal : 48|8@1+ (1,0) [0|255] "" XXX
 SG_ ECS_ALS_HghtLvlChgUnblSta : 56|4@1+ (1,0) [0|15] "" XXX
 SG_ ECS_ALS_LvlCtrlUnblOvhtSta : 60|2@1+ (1,0) [0|3] "" XXX
 SG_ ECS_ALS_LftngSta : 62|2@1+ (1,0) [0|3] "" XXX
 SG_ ECS_ALS_LwrngSta : 64|16@1+ (1,0) [0|65535] "" XXX
 SG_ ECS_ALS_SysUnblSta : 80|2@1+ (1,0) [0|3] "" XXX
 SG_ ECS_ALS_DfctvSta : 82|3@1+ (1,0) [0|7] "" XXX
 SG_ ECS_MTCB_DfctvSta : 85|3@1+ (1,0) [0|7] "" XXX
 SG_ ECS_ALS_LvlDisMain : 88|4@1+ (1,0) [0|15] "" XXX
 SG_ ECS_ALS_LvlDisSub : 92|4@1+ (1,0) [0|15] "" XXX
 SG_ ECS_ALS_LvlchgDisMain : 96|2@1+ (1,0) [0|3] "" XXX
 SG_ ECS_ALS_LvlchgDisSub : 98|6@1+ (1,0) [0|63] "" XXX
 SG_ ECS_MTCB_FLSta : 104|3@1+ (1,0) [0|7] "" XXX
 SG_ ECS_MTCB_FRSta : 107|5@1+ (1,0) [0|31] "" XXX
 SG_ ECS_MTCB_RLSta : 112|3@1+ (1,0) [0|7] "" XXX
 SG_ ECS_MTCB_RRSta : 115|5@1+ (1,0) [0|31] "" XXX

BO_ 384 CAM_0x180: 32 CAMERA
 SG_ CHECKSUM : 0|16@1+ (1,0) [0|65535] "" XXX
 SG_ COUNTER : 16|8@1+ (1,0) [0|255] "" XXX

BO_ 385 CAM_0x181: 32 CAMERA
 SG_ CHECKSUM : 0|16@1+ (1,0) [0|65535] "" XXX
 SG_ COUNTER : 16|8@1+ (1,0) [0|255] "" XXX

BO_ 386 CAM_0x182: 32 CAMERA
 SG_ CHECKSUM : 0|16@1+ (1,0) [0|65535] "" XXX
 SG_ COUNTER : 16|8@1+ (1,0) [0|255] "" XXX

BO_ 387 CAM_0x183: 32 CAMERA
 SG_ CHECKSUM : 0|16@1+ (1,0) [0|65535] "" XXX
 SG_ COUNTER : 16|8@1+ (1,0) [0|255] "" XXX

BO_ 388 CAM_0x184: 32 CAMERA
 SG_ CHECKSUM : 0|16@1+ (1,0) [0|65535] "" XXX
 SG_ COUNTER : 16|8@1+ (1,0) [0|255] "" XXX

BO_ 389 CAM_0x185: 8 CAMERA
 SG_ CHECKSUM : 0|16@1+ (1,0) [0|65535] "" XXX
 SG_ COUNTER : 16|8@1+ (1,0) [0|255] "" XXX

BO_ 399 FPM_06_00ms: 8 XXX
 SG_ FPM_ISKLearnFB : 2|6@1+ (1,0) [0|63] "" XXX
 SG_ FPM_USMDispPopup : 8|8@1+ (1,0) [0|255] "" XXX

BO_ 400 FR_CMR_06_00ms: 8 XXX
 SG_ FR_CMR_Crc6Val : 0|16@1+ (1,0) [0|65535] "" XXX
 SG_ FR_CMR_AlvCnt6Val : 16|64@1+ (1,0) [0|1.84467440737096e+19] "" XXX
 SG_ RP_LftHeight_01 : 24|8@1+ (1,0) [0|255] "" XXX
 SG_ RP_LftHeight_02 : 32|8@1+ (1,0) [0|255] "" XXX
 SG_ RP_LftHeight_03 : 40|8@1+ (1,0) [0|255] "" XXX
 SG_ RP_LftHeight_04 : 48|8@1+ (1,0) [0|255] "" XXX
 SG_ RP_LftHeight_05 : 56|8@1+ (1,0) [0|255] "" XXX
 SG_ RP_LftHeight_06 : 64|8@1+ (1,0) [0|255] "" XXX
 SG_ RP_LftHeight_07 : 72|8@1+ (1,0) [0|255] "" XXX
 SG_ RP_LftHeight_08 : 80|8@1+ (1,0) [0|255] "" XXX
 SG_ RP_LftHeight_09 : 88|8@1+ (1,0) [0|255] "" XXX
 SG_ RP_LftHeight_10 : 96|64@1+ (1,0) [0|1.84467440737096e+19] "" XXX
 SG_ RP_RtHeight_01 : 104|8@1+ (1,0) [0|255] "" XXX
 SG_ RP_RtHeight_02 : 112|8@1+ (1,0) [0|255] "" XXX
 SG_ RP_RtHeight_03 : 120|8@1+ (1,0) [0|255] "" XXX
 SG_ RP_RtHeight_04 : 128|8@1+ (1,0) [0|255] "" XXX
 SG_ RP_RtHeight_05 : 136|8@1+ (1,0) [0|255] "" XXX
 SG_ RP_RtHeight_06 : 144|8@1+ (1,0) [0|255] "" XXX
 SG_ RP_RtHeight_07 : 152|8@1+ (1,0) [0|255] "" XXX
 SG_ RP_RtHeight_08 : 160|8@1+ (1,0) [0|255] "" XXX
 SG_ RP_RtHeight_09 : 168|8@1+ (1,0) [0|255] "" XXX
 SG_ RP_RtHeight_10 : 176|40@1+ (1,0) [0|1099511627775] "" XXX
 SG_ RP_LftConf_01 : 184|3@1+ (1,0) [0|7] "" XXX
 SG_ RP_LftConf_02 : 187|5@1+ (1,0) [0|31] "" XXX
 SG_ RP_LftConf_03 : 192|3@1+ (1,0) [0|7] "" XXX
 SG_ RP_LftConf_04 : 195|3@1+ (1,0) [0|7] "" XXX
 SG_ RP_LftConf_05 : 198|3@1+ (1,0) [0|7] "" XXX
 SG_ RP_LftConf_06 : 201|3@1+ (1,0) [0|7] "" XXX
 SG_ RP_LftConf_07 : 204|3@1+ (1,0) [0|7] "" XXX
 SG_ RP_LftConf_08 : 207|3@1+ (1,0) [0|7] "" XXX
 SG_ RP_LftConf_09 : 210|3@1+ (1,0) [0|7] "" XXX
 SG_ RP_LftConf_10 : 213|3@1+ (1,0) [0|7] "" XXX
 SG_ RP_RtConf_01 : 216|3@1+ (1,0) [0|7] "" XXX
 SG_ RP_RtConf_02 : 219|3@1+ (1,0) [0|7] "" XXX
 SG_ RP_RtConf_03 : 222|3@1+ (1,0) [0|7] "" XXX
 SG_ RP_RtConf_04 : 225|3@1+ (1,0) [0|7] "" XXX
 SG_ RP_RtConf_05 : 228|3@1+ (1,0) [0|7] "" XXX
 SG_ RP_RtConf_06 : 231|3@1+ (1,0) [0|7] "" XXX
 SG_ RP_RtConf_07 : 234|3@1+ (1,0) [0|7] "" XXX
 SG_ RP_RtConf_08 : 237|3@1+ (1,0) [0|7] "" XXX
 SG_ RP_RtConf_09 : 240|3@1+ (1,0) [0|7] "" XXX
 SG_ RP_RtConf_10 : 243|3@1+ (1,0) [0|7] "" XXX
 SG_ RP_UpdateCounterVal : 246|2@1+ (1,0) [0|3] "" XXX
 SG_ RP_ProfSts : 248|2@1+ (1,0) [0|3] "" XXX
 SG_ RP_DayNightIndicator : 250|6@1+ (1,0) [0|63] "" XXX

BO_ 410 VCMS_01_10ms: 8 XXX
 SG_ VCMS_CyclicRedundancyCheck1Value : 0|16@1+ (1,0) [0|65535] "" XXX
 SG_ VCMS_AliveCounter1Value : 16|8@1+ (1,0) [0|255] "" XXX
 SG_ VCMS_MainRlyOnReq : 24|2@1+ (1,0) [0|3] "" XXX
 SG_ VCMS_QcNRlyOnReq : 26|2@1+ (1,0) [0|3] "" XXX
 SG_ VCMS_QcPRlyOnReq : 28|2@1+ (1,0) [0|3] "" XXX
 SG_ VCMS_400VRlyOnReq : 30|2@1+ (1,0) [0|3] "" XXX
 SG_ VCMS_MainRlyOffReq : 32|2@1+ (1,0) [0|3] "" XXX
 SG_ VCMS_McuMultiChgStartReq : 34|2@1+ (1,0) [0|3] "" XXX
 SG_ VCMS_McuPreChgStartReq : 36|2@1+ (1,0) [0|3] "" XXX
 SG_ VCMS_DCChargeMode : 38|2@1+ (1,0) [0|3] "" XXX
 SG_ VCMS_ObcChgStart : 40|2@1+ (1,0) [0|3] "" XXX
 SG_ VCMS_CpPwmStat : 42|2@1+ (1,0) [0|3] "" XXX
 SG_ VCMS_Ig3Stat : 44|2@1+ (1,0) [0|3] "" XXX
 SG_ VCMS_V2lSocketState : 46|2@1+ (1,0) [0|3] "" XXX
 SG_ VCMS_McuPreChgTarVolt : 48|16@1+ (1,0) [0|65535] "" XXX
 SG_ VCMS_ObcChgDcVolt : 64|16@1+ (1,0) [0|65535] "" XXX
 SG_ VCMS_ObcChgDcCur : 80|16@1+ (1,0) [0|65535] "" XXX
 SG_ VCMS_ObcChgAcCur : 96|16@1+ (1,0) [0|65535] "" XXX
 SG_ VCMS_InletAutoLockMode : 112|3@1+ (1,0) [0|7] "" XXX
 SG_ VCMS_InletLockStatus : 115|3@1+ (1,0) [0|7] "" XXX
 SG_ VCMS_InletDrUnlockFlag : 118|2@1+ (1,0) [0|3] "" XXX
 SG_ VCMS_InletActStatus : 120|3@1+ (1,0) [0|7] "" XXX
 SG_ VCMS_InletPosition : 123|3@1+ (1,0) [0|7] "" XXX
 SG_ VCMS_InletChargeFlag : 126|2@1+ (1,0) [0|3] "" XXX
 SG_ VCMS_WccuChgStart : 128|2@1+ (1,0) [0|3] "" XXX
 SG_ VCMS_ChgInvSwFlg : 130|2@1+ (1,0) [0|3] "" XXX
 SG_ VCMS_ObcDisChgAcFreq : 132|2@1+ (1,0) [0|3] "" XXX
 SG_ VCMS_V2lStartMode : 134|2@1+ (1,0) [0|3] "" XXX
 SG_ VCMS_ChgTransferType : 136|4@1+ (1,0) [0|15] "" XXX
 SG_ VCMS_ChgDirType : 140|4@1+ (1,0) [0|15] "" XXX
 SG_ VCMS_ChgCommType : 144|8@1+ (1,0) [0|255] "" XXX
 SG_ VCMS_SeqMainStat : 152|4@1+ (1,0) [0|15] "" XXX
 SG_ VCMS_SeqPlcChgStat : 156|4@1+ (1,0) [0|15] "" XXX
 SG_ VCMS_SeqBcChgStat : 160|4@1+ (1,0) [0|15] "" XXX
 SG_ VCMS_SeqWcChgStat : 164|4@1+ (1,0) [0|15] "" XXX
 SG_ VCMS_SeqGbtChgStat : 168|4@1+ (1,0) [0|15] "" XXX
 SG_ VCMS_SeqChadeChgStat : 172|4@1+ (1,0) [0|15] "" XXX
 SG_ VCMS_SeqV2lChgStat : 176|8@1+ (1,0) [0|255] "" XXX
 SG_ VCMS_ChgRlyOnMode : 184|4@1+ (1,0) [0|15] "" XXX
 SG_ VCMS_ChgRlyOffMode : 188|4@1+ (1,0) [0|15] "" XXX
 SG_ VCMS_WakeupStat : 192|4@1+ (1,0) [0|15] "" XXX
 SG_ VCMS_IcuWkpStat : 196|2@1+ (1,0) [0|3] "" XXX
 SG_ VCMS_GbtWkpStat : 198|2@1+ (1,0) [0|3] "" XXX
 SG_ VCMS_FltCode : 200|5@1+ (1,0) [0|31] "" XXX
 SG_ VCMS_FltType : 205|3@1+ (1,0) [0|7] "" XXX
 SG_ VCMS_SleepMode : 208|24@1+ (1,0) [0|16777215] "" XXX
 SG_ VCMS_ObcDisChgDcCur : 232|8@1+ (1,0) [0|255] "" XXX
 SG_ VCMS_ObcDisChgAcCur : 240|8@1+ (1,0) [0|255] "" XXX
 SG_ VCMS_ObcDisChgAcVolt : 248|8@1+ (1,0) [0|255] "" XXX

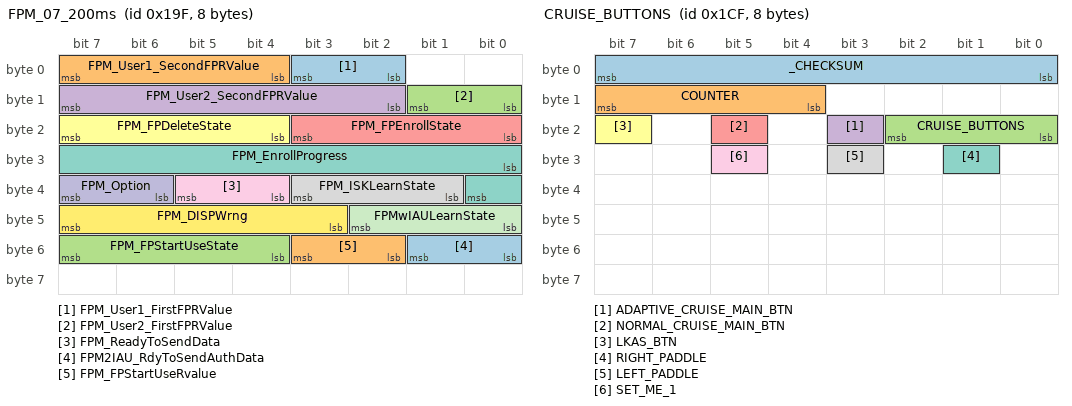
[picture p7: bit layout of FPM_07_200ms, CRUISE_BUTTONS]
BO_ 415 FPM_07_200ms: 8 XXX
 SG_ FPM_User1_FirstFPRValue : 2|2@1+ (1,0) [0|3] "" XXX
 SG_ FPM_User1_SecondFPRValue : 4|4@1+ (1,0) [0|15] "" XXX
 SG_ FPM_User2_FirstFPRValue : 8|2@1+ (1,0) [0|3] "" XXX
 SG_ FPM_User2_SecondFPRValue : 10|6@1+ (1,0) [0|63] "" XXX
 SG_ FPM_FPEnrollState : 16|4@1+ (1,0) [0|15] "" XXX
 SG_ FPM_FPDeleteState : 20|4@1+ (1,0) [0|15] "" XXX
 SG_ FPM_EnrollProgress : 24|9@1+ (1,0) [0|511] "" XXX
 SG_ FPM_ISKLearnState : 33|3@1+ (1,0) [0|7] "" XXX
 SG_ FPM_ReadyToSendData : 36|2@1+ (1,0) [0|3] "" XXX
 SG_ FPM_Option : 38|2@1+ (1,0) [0|3] "" XXX
 SG_ FPMwIAULearnState : 40|3@1+ (1,0) [0|7] "" XXX
 SG_ FPM_DISPWrng : 43|5@1+ (1,0) [0|31] "" XXX
 SG_ FPM2IAU_RdyToSendAuthData : 48|2@1+ (1,0) [0|3] "" XXX
 SG_ FPM_FPStartUseRvalue : 50|2@1+ (1,0) [0|3] "" XXX
 SG_ FPM_FPStartUseState : 52|4@1+ (1,0) [0|15] "" XXX

BO_ 416 ADAS_CMD_20_20ms: 32 XXX
 SG_ ADAS_CMD_Crc20Val : 0|16@1+ (1,0) [0|65535] "" XXX
 SG_ ADAS_CMD_AlvCnt20Val : 16|8@1+ (1,0) [0|0] "" XXX
 SG_ SCC_ObjDstVal : 24|11@1+ (0.1,0) [0|204.7] "m" XXX
 SG_ SCC_ObjRelSpdVal : 35|12@1+ (0.1,-170) [-170|239.5] "m/s" XXX
 SG_ SCC_ObjLatPosVal : 47|9@1+ (0.1,-20) [-20|31.1] "m" XXX
 SG_ SCC_SysFlrSta : 64|2@1+ (1,0) [0|3] "" XXX
 SG_ SCC_MainOnOffSta : 66|2@1+ (1,0) [0|3] "" XXX
 SG_ SCC_OpSta : 68|6@1+ (1,0) [0|63] "" XXX
 SG_ SCC_InfoDis : 74|3@1+ (1,0) [0|7] "" XXX
 SG_ SCC_DrvAlrtDis : 77|3@1+ (1,0) [0|7] "" XXX
 SG_ NSCC_Op2Sta : 80|8@1+ (1,0) [0|255] "" XXX
 SG_ SCC_HeadwayDstSetVal : 88|8@1+ (1,0) [0|255] "" XXX
 SG_ SCC_TrgtSpdSetVal : 96|8@1+ (1,0) [0|255] "" XXX
 SG_ SCC_NSCCOpSta : 104|2@1+ (1,0) [0|0] "" XXX
 SG_ SCC_NSCCOnOffSta : 106|2@1+ (1,0) [0|0] "" XXX
 SG_ SCC_ObjSta : 108|3@1+ (1,0) [0|0] "" XXX
 SG_ SCC_NSCCInfoPUDis : 117|3@1+ (1,0) [0|0] "" XXX
 SG_ SCC_AccelReqVal : 128|11@1+ (0.01,-10.23) [0|0] "m/s^2" XXX
 SG_ SCC_AccelReqRawVal : 140|11@1+ (0.01,-10.23) [0|0] "m/s^2" XXX
 SG_ SCC_JrkUppLimVal : 152|7@1+ (0.1,0) [0|0] "m/s^3" XXX
 SG_ SCC_JrkLwrLimVal : 160|7@1+ (0.1,0) [0|0] "m/s^3" XXX
 SG_ SCC_AccelLimBandUppVal : 168|6@1+ (0.02,0) [0|0] "m/s^2" XXX
 SG_ SCC_AccelLimBandLwrVal : 176|6@1+ (0.02,0) [0|0] "m/s^2" XXX
 SG_ SCC_VehStpReq : 184|2@1+ (1,0) [0|0] "" XXX
 SG_ SCC_EngStateReq : 188|4@1+ (1,0) [0|15] "" XXX
 SG_ SCC_TrgtDstVal : 192|12@1+ (1,0) [0|4095] "" XXX
 SG_ ADAS_HzrdLmpReqVal : 204|2@1+ (1,0) [0|3] "" XXX
 SG_ ADAS_DrUnlckReqSta : 206|2@1+ (1,0) [0|3] "" XXX
 SG_ HDP_LongActvSta : 208|2@1+ (1,0) [0|3] "" XXX
 SG_ HDP_MRMCtrlSta : 210|2@1+ (1,0) [0|3] "" XXX
 SG_ HDP_ESCOnReq : 212|2@1+ (1,0) [0|3] "" XXX
 SG_ HDP_AccelOvrdLmt : 214|2@1+ (1,0) [0|3] "" XXX

BO_ 421 AWD_01_20ms: 8 XXX
 SG_ AWD_Crc1Val : 0|16@1+ (1,0) [0|65535] "" XXX
 SG_ AWD_AlvCnt1Val : 16|8@1+ (1,0) [0|255] "" XXX
 SG_ AWD_Typ : 24|2@1+ (1,0) [0|3] "" XXX
 SG_ AWD_SigSpprtSta : 26|2@1+ (1,0) [0|3] "" XXX
 SG_ AWD_IcscErrSta : 28|4@1+ (1,0) [0|15] "" XXX
 SG_ AWD_ErrCodeVal : 32|8@1+ (1,0) [0|255] "" XXX
 SG_ AWD_CltchDtVal : 40|8@1+ (1,0) [0|255] "" XXX
 SG_ AWD_TireRdsVal : 48|8@1+ (1,0) [0|255] "" XXX
 SG_ AWD_SwVerVal : 56|8@1+ (1,0) [0|255] "" XXX
 SG_ AWD_OpMod2HSta : 64|2@1+ (1,0) [0|3] "" XXX
 SG_ AWD_OpMod4HSta : 66|2@1+ (1,0) [0|3] "" XXX
 SG_ AWD_OpModLowSta : 68|2@1+ (1,0) [0|3] "" XXX
 SG_ AWD_OpModAutoSta : 70|2@1+ (1,0) [0|3] "" XXX
 SG_ AWD_OpModLkSta : 72|2@1+ (1,0) [0|3] "" XXX
 SG_ AWD_TireSizeWrng : 74|6@1+ (1,0) [0|63] "" XXX
 SG_ AWD_ShaftTqVal : 80|16@1+ (1,0) [0|65535] "" XXX
 SG_ AWD_StrWhlPosVal : 96|16@1+ (1,0) [0|65535] "" XXX
 SG_ AWD_FRWhlSpdSnsrVal : 112|8@1+ (1,0) [0|255] "" XXX
 SG_ AWD_FLWhlSpdSnsrVal : 120|8@1+ (1,0) [0|255] "" XXX
 SG_ AWD_RRWhlSpdSnsrVal : 128|8@1+ (1,0) [0|255] "" XXX
 SG_ AWD_RLWhlSpdSnsrVal : 136|8@1+ (1,0) [0|255] "" XXX
 SG_ AWD_CltchPrsrVal : 144|16@1+ (1,0) [0|65535] "" XXX
 SG_ AWD_ActrCurrVal : 160|8@1+ (1,0) [0|255] "" XXX
 SG_ AWD_ActrPosVal : 168|16@1+ (1,0) [0|65535] "" XXX
 SG_ AWD_CltchThrmlStrssVal : 184|12@1+ (1,0) [0|4095] "" XXX
 SG_ AWD_SysOpSta : 196|8@1+ (1,0) [0|255] "" XXX
 SG_ AWD_ShaftTqVal_Calc : 204|20@1+ (1,0) [0|1048575] "" XXX
 SG_ AWD_FrTqDistRto : 224|8@1+ (1,0) [0|255] "" XXX
 SG_ AWD_RrTqDistRto : 232|8@1+ (1,0) [0|255] "" XXX

BO_ 426 CLU_01_20ms: 16 XXX
 SG_ CLU_Crc1Val : 0|16@1+ (1,0) [0|65535] "" XXX
 SG_ CLU_AlvCnt1Val : 16|8@1+ (1,0) [0|255] "" XXX
 SG_ NEW_SIGNAL_1 : 24|4@1+ (1,0) [0|15] "" XXX
 SG_ CLU_DtntOutSta : 28|2@1+ (1,0) [0|3] "" XXX
 SG_ CLU_SpdUnitTyp : 30|1@1+ (1,0) [0|1] "" XXX
 SG_ NEW_SIGNAL_2 : 31|1@1+ (1,0) [0|1] "" XXX
 SG_ CLU_DisSpdDcmlVal : 32|2@1+ (1,0) [0|3] "" XXX
 SG_ ADAPTIVE_CRUISE_MAIN_BTN : 34|1@1+ (1,0) [0|1] "" XXX
 SG_ NEW_SIGNAL_3 : 35|1@1+ (1,0) [0|1] "" XXX
 SG_ CRUISE_BUTTONS : 36|3@1+ (1,0) [0|4] "" XXX
 SG_ LFA_BTN : 39|1@1+ (1,0) [0|1] "" XXX
 SG_ NEW_SIGNAL_4 : 40|1@1+ (1,0) [0|1] "" XXX
 SG_ NORMAL_CRUISE_MAIN_BTN : 41|1@1+ (1,0) [0|1] "" XXX
 SG_ NEW_SIGNAL_5 : 42|1@1+ (1,0) [0|1] "" XXX
 SG_ CLU_RhstaLvlSta : 43|1@1+ (1,0) [0|1] "" XXX
 SG_ SET_ME_2 : 44|3@1+ (1,0) [0|7] "" XXX
 SG_ NEW_SIGNAL_6 : 47|1@1+ (1,0) [0|1] "" XXX
 SG_ CLU_DisSpdVal : 48|8@1+ (1,0) [0|255] "" XXX
 SG_ BYTE7 : 56|8@1+ (1,0) [0|255] "" XXX
 SG_ CLU_DisSpdVal_KPH : 64|8@1+ (1,0) [0|255] "" XXX
 SG_ BYTE9 : 72|1@1+ (1,0) [0|1] "" XXX
 SG_ CLU_PwrAutoOffResetReq_HCU : 73|2@1+ (1,0) [0|3] "" XXX
 SG_ CLU_CUSTOMSta_NEW : 75|4@1+ (1,0) [0|15] "" XXX
 SG_ CLU_AutoBrightSta : 79|1@1+ (1,0) [0|1] "" XXX
 SG_ BYTE10 : 80|8@1+ (1,0) [0|255] "" XXX
 SG_ BYTE11 : 88|8@1+ (1,0) [0|255] "" XXX
 SG_ BYTE12 : 96|8@1+ (1,0) [0|255] "" XXX
 SG_ BYTE13 : 104|8@1+ (1,0) [0|255] "" XXX
 SG_ BYTE14 : 112|8@1+ (1,0) [0|255] "" XXX
 SG_ BYTE15 : 120|8@1+ (1,0) [0|255] "" XXX

BO_ 432 DATC_02_20ms: 8 XXX
 SG_ DATC_Crc2Val : 0|16@1+ (1,0) [0|65535] "" XXX
 SG_ DATC_AlvCnt2Val : 16|8@1+ (1,0) [0|255] "" XXX
 SG_ DATC_AcnCompFltCodVal : 24|4@1+ (1,0) [0|15] "" XXX
 SG_ DATC_AcnCompLmtOperCodeVal : 28|4@1+ (1,0) [0|15] "" XXX
 SG_ DATC_AcnCompMaxReqPwrVal : 32|6@1+ (1,0) [0|63] "" XXX
 SG_ DATC_HVPtcIntLkSta : 38|2@1+ (1,0) [0|3] "" XXX
 SG_ DATC_PtcSnsrFlrCodVal : 40|8@1+ (1,0) [0|255] "" XXX
 SG_ DATC_PtcFltCodVal : 48|8@1+ (1,0) [0|255] "" XXX
 SG_ DATC_PtcTyp : 56|2@1+ (1,0) [0|3] "" XXX
 SG_ DATC_PtcFltSta : 58|2@1+ (1,0) [0|3] "" XXX
 SG_ DATC_PtcOnReq : 60|4@1+ (1,0) [0|15] "" XXX
 SG_ DATC_PtcMaxPwrWReq : 64|18@1+ (1,0) [0|262143] "" XXX
 SG_ DATC_CtrlablSta : 82|6@1+ (1,0) [0|63] "" XXX
 SG_ DATC_IntakeActrTestVal : 88|8@1+ (1,0) [0|255] "" XXX
 SG_ DATC_PassModActrTestVal : 96|8@1+ (1,0) [0|255] "" XXX
 SG_ DATC_PhotoSnsrFdbckVoltTestVal : 104|8@1+ (1,0) [0|255] "" XXX
 SG_ DATC_AdsActrTestVal : 112|8@1+ (1,0) [0|255] "" XXX
 SG_ DATC_TempActrTestVal : 120|8@1+ (1,0) [0|255] "" XXX
 SG_ DATC_DrvrModActrTestVal : 128|8@1+ (1,0) [0|255] "" XXX
 SG_ DATC_AptPrsrPsiVal : 136|8@1+ (1,0) [0|255] "" XXX
 SG_ DATC_BlwTrgtVoltTestVal : 144|8@1+ (1,0) [0|255] "" XXX
 SG_ DATC_ClntVlvFltCodVal : 152|8@1+ (1,0) [0|255] "" XXX
 SG_ DATC_EvapTempSnsrCTestVal : 160|8@1+ (1,0) [0|255] "" XXX
 SG_ DATC_IncarSnsrTempCTestVal : 168|8@1+ (1,0) [0|255] "" XXX
 SG_ DATC_DrvVentTempCTestVal : 176|8@1+ (1,0) [0|255] "" XXX
 SG_ DATC_DrFlrTempCTestVal : 184|8@1+ (1,0) [0|255] "" XXX
 SG_ DATC_PsVentTempCTestVal : 192|8@1+ (1,0) [0|255] "" XXX
 SG_ DATC_PsFlrTempCTestVal : 200|8@1+ (1,0) [0|255] "" XXX
 SG_ DATC_HtrPmpModSta : 208|4@1+ (1,0) [0|15] "" XXX
 SG_ DATC_HtrPmpTyp : 212|12@1+ (1,0) [0|4095] "" XXX
 SG_ DATC_RefrigVlvFltCodVal : 224|8@1+ (1,0) [0|255] "" XXX
 SG_ DATC_BlwModSta : 232|6@1+ (1,0) [0|63] "" XXX
 SG_ DATC_EcoClmtLimSta : 238|2@1+ (1,0) [0|3] "" XXX
 SG_ DATC_ClmtLimOpSta : 240|8@1+ (1,0) [0|255] "" XXX

BO_ 437 FR_CMR_03_50ms: 32 XXX
 SG_ FR_CMR_Crc3Val : 0|16@1+ (1,0) [0|65535] "" XXX
 SG_ FR_CMR_AlvCnt3Val : 16|8@1+ (1,0) [0|255] "" XXX
 SG_ Info_LtLnQualSta : 24|3@1+ (1,0) [0|7] "" XXX
 SG_ Info_LtLnDptSta : 27|2@1+ (1,0) [0|3] "" XXX
 SG_ Info_LtLnPosVal : 29|14@1+ (1,0) [0|16383] "" XXX
 SG_ Info_LtLnHdingAnglVal : 43|21@1+ (1,0) [0|2097151] "" XXX
 SG_ Info_LtLnCvtrVal : 64|16@1+ (1,0) [0|65535] "" XXX
 SG_ Info_LtLnCrvtrDrvtvVal : 80|16@1+ (1,0) [0|65535] "" XXX
 SG_ Info_RtLnQualSta : 96|3@1+ (1,0) [0|7] "" XXX
 SG_ Info_RtLnDptSta : 99|2@1+ (1,0) [0|3] "" XXX
 SG_ Info_RtLnPosVal : 101|14@1+ (1,0) [0|16383] "" XXX
 SG_ Info_RtLnHdingAnglVal : 115|13@1+ (1,0) [0|8191] "" XXX
 SG_ Info_RtLnCvtrVal : 128|16@1+ (1,0) [0|65535] "" XXX
 SG_ Info_RtLnCrvtrDrvtvVal : 144|48@1+ (1,0) [0|281474976710655] "" XXX
 SG_ ID_CIPV : 192|8@1+ (1,0) [0|255] "" XXX
 SG_ Relative_Velocity : 200|12@1+ (1,0) [0|4095] "" XXX
 SG_ Longitudinal_Distance : 212|12@1+ (1,0) [0|15] "" XXX

BO_ 438 CAM_0x1b6: 32 CAMERA
 SG_ CHECKSUM : 0|16@1+ (1,0) [0|65535] "" XXX
 SG_ COUNTER : 16|8@1+ (1,0) [0|255] "" XXX

BO_ 439 CAM_0x1b7: 32 CAMERA
 SG_ CHECKSUM : 0|16@1+ (1,0) [0|65535] "" XXX
 SG_ COUNTER : 16|8@1+ (1,0) [0|255] "" XXX

BO_ 440 CAM_0x1b8: 32 CAMERA
 SG_ CHECKSUM : 0|16@1+ (1,0) [0|65535] "" XXX
 SG_ COUNTER : 16|8@1+ (1,0) [0|255] "" XXX

BO_ 441 CAM_0x1b9: 32 CAMERA
 SG_ CHECKSUM : 0|16@1+ (1,0) [0|65535] "" XXX
 SG_ COUNTER : 16|8@1+ (1,0) [0|255] "" XXX

BO_ 442 ADAS_CMD_50_50ms: 24 XXX
 SG_ ADAS_CMD_Crc50Val : 0|16@1+ (1,0) [0|65535] "" XXX
 SG_ ADAS_CMD_AlvCnt50Val : 16|8@1+ (1,0) [0|255] "" XXX
 SG_ BCW_Sta : 24|1@0+ (1,0) [0|1] "" XXX
 SG_ BCW_OnOffEquipSta : 28|2@1+ (1,0) [0|3] "" XXX
 SG_ BCW_LtIndSta : 30|1@0+ (1,0) [0|3] "" XXX
 SG_ BCW_RtIndSta : 32|1@1+ (1,0) [0|3] "" XXX
 SG_ BCW_LtSndWrngSta : 34|2@1+ (1,0) [0|3] "" XXX
 SG_ BCW_RtSndWrngSta : 36|10@1+ (1,0) [0|1023] "" XXX
 SG_ FL_INDICATOR : 46|6@0+ (1,0) [0|1] "" XXX
 SG_ FR_INDICATOR : 54|2@0+ (1,0) [0|3] "" XXX
 SG_ BCW_SnstvtyModRetVal : 56|3@1+ (1,0) [0|7] "" XXX
 SG_ BCW_IndSta : 59|3@1+ (1,0) [0|7] "" XXX
 SG_ BCA_OnOffEquip2Sta : 62|2@1+ (1,0) [0|3] "" XXX
 SG_ BCA_Sta : 64|1@0+ (1,0) [0|1] "" XXX
 SG_ BCA_OnOffEquipSta : 68|1@0+ (1,0) [0|1] "" XXX
 SG_ BCA_DRV_WarnSta : 76|4@1+ (1,0) [0|15] "" XXX
 SG_ BCA_Plus_Deccel_Req : 80|4@1+ (1,0) [0|15] "" XXX
 SG_ BCA_Plus_BrkCmdSta : 84|2@1+ (1,0) [0|3] "" XXX
 SG_ BCA_Plus_LtWrngSta : 86|2@1+ (1,0) [0|3] "" XXX
 SG_ BCA_Plus_RtWrngSta : 88|5@1+ (1,0) [0|31] "" XXX
 SG_ BCA_Plus_FuncStat : 93|3@1+ (1,0) [0|7] "" XXX
 SG_ BCA_Plus_Sta : 96|1@0+ (1,0) [0|1] "" XXX
 SG_ Brake_Control_RL : 110|2@1+ (1,0) [0|3] "" XXX
 SG_ Brake_Control_RR : 118|2@1+ (1,0) [0|3] "" XXX
 SG_ OSMrrLamp_LtIndSta : 128|2@1+ (1,0) [0|3] "" XXX
 SG_ OSMrrLamp_RtIndSta : 130|6@1+ (1,0) [0|63] "" XXX

BO_ 463 CRUISE_BUTTONS: 8 XXX
 SG_ _CHECKSUM : 0|8@1+ (1,0) [0|65535] "" XXX
 SG_ COUNTER : 12|4@1+ (1,0) [0|255] "" XXX
 SG_ CRUISE_BUTTONS : 16|3@1+ (1,0) [0|3] "" XXX
 SG_ ADAPTIVE_CRUISE_MAIN_BTN : 19|1@1+ (1,0) [0|1] "" XXX
 SG_ NORMAL_CRUISE_MAIN_BTN : 21|1@1+ (1,0) [0|1] "" XXX
 SG_ LKAS_BTN : 23|1@1+ (1,0) [0|1] "" XXX
 SG_ RIGHT_PADDLE : 25|1@1+ (1,0) [0|1] "" XXX
 SG_ LEFT_PADDLE : 27|1@1+ (1,0) [0|1] "" XXX
 SG_ SET_ME_1 : 29|1@1+ (1,0) [0|1] "" XXX

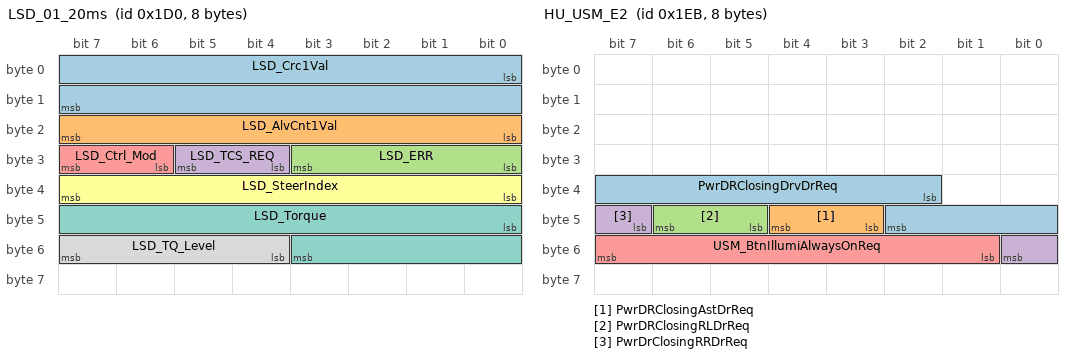
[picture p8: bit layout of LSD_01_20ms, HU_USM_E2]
BO_ 464 LSD_01_20ms: 8 XXX
 SG_ LSD_Crc1Val : 0|16@1+ (1,0) [0|65535] "" XXX
 SG_ LSD_AlvCnt1Val : 16|8@1+ (1,0) [0|255] "" XXX
 SG_ LSD_ERR : 24|4@1+ (1,0) [0|15] "" XXX
 SG_ LSD_TCS_REQ : 28|2@1+ (1,0) [0|3] "" XXX
 SG_ LSD_Ctrl_Mod : 30|2@1+ (1,0) [0|3] "" XXX
 SG_ LSD_SteerIndex : 32|8@1+ (1,0) [0|255] "" XXX
 SG_ LSD_Torque : 40|12@1+ (1,0) [0|4095] "" XXX
 SG_ LSD_TQ_Level : 52|4@1+ (1,0) [0|15] "" XXX

BO_ 474 ADAS_DRV_02_1000ms: 32 XXX
 SG_ ADAS_DRV_Crc2Val : 0|16@1+ (1,0) [0|65535] "" XXX
 SG_ ADAS_DRV_AlvCnt2Val : 16|8@1+ (1,0) [0|255] "" XXX
 SG_ ADAS_DRV_Required_ADASMapMsg : 24|7@1+ (1,0) [0|127] "" XXX
 SG_ SET_ME_22 : 31|8@0+ (1,0) [0|255] "" XXX
 SG_ ADAS_DRV_SwVer1 : 40|4@1+ (1,0) [0|15] "" XXX
 SG_ ADAS_DRV_SwVer2 : 44|3@1+ (1,0) [0|7] "" XXX
 SG_ SET_ME_41 : 47|8@0+ (1,0) [0|255] "" XXX

BO_ 480 ADAS_CMD_31_50ms: 16 XXX
 SG_ ADAS_CMD_Crc31Val : 0|16@1+ (1,0) [0|65535] "" XXX
 SG_ ADAS_CMD_AlvCnt31Val : 16|8@1+ (1,0) [0|255] "" XXX
 SG_ HDA_OptUsmSta : 24|1@0+ (1,0) [0|1] "" XXX
 SG_ HDP_WarnSndSta_HTCU : 27|3@1+ (1,0) [0|7] "" XXX
 SG_ HDA_CntrlModSta : 30|1@0+ (1,0) [0|1] "" XXX
 SG_ HDA_ICON : 31|1@1+ (1,0) [0|1] "" XXX
 SG_ HDA_InfoPUDis : 32|3@1+ (1,0) [0|7] "" XXX
 SG_ HDP_AutoCallReqSta : 35|5@1+ (1,0) [0|31] "" XXX
 SG_ HDP_DispBarSta : 40|4@1+ (1,0) [0|15] "" XXX
 SG_ HDP_OptInfoSta : 44|3@1+ (1,0) [0|7] "" XXX
 SG_ HDA_LFA_SymSta : 47|2@1+ (1,0) [0|3] "" XXX
 SG_ HDA_LFA_WrnSnd : 49|1@0+ (1,0) [0|1] "" XXX
 SG_ HDA_InfoPUDis1 : 51|5@1+ (1,0) [0|31] "" XXX
 SG_ HDP_ActvSta : 56|2@1+ (1,0) [0|3] "" XXX
 SG_ HDP_SysSta : 58|4@1+ (1,0) [0|15] "" XXX
 SG_ HDP_FailureMode : 62|2@1+ (1,0) [0|3] "" XXX
 SG_ HDP_ObstacleDstVal : 64|11@1+ (1,0) [0|2047] "" XXX
 SG_ HDP_ObstacleLatPosVal : 75|9@1+ (1,0) [0|511] "" XXX
 SG_ HDP_InfoPUDis : 84|4@1+ (1,0) [0|15] "" XXX
 SG_ HDP_WrngTypPUDis : 88|8@1+ (1,0) [0|255] "" XXX
 SG_ HDP_HapticWarnReq : 96|3@1+ (1,0) [0|7] "" XXX
 SG_ HDP_ActvStaDis : 99|3@1+ (1,0) [0|7] "" XXX
 SG_ HDP_OpStaDisp : 102|4@1+ (1,0) [0|15] "" XXX
 SG_ HDP_ObstSta : 106|3@1+ (1,0) [0|7] "" XXX
 SG_ HDP_SysFlrDisp : 109|3@1+ (1,0) [0|7] "" XXX
 SG_ HDP_InhbtOffDispSta : 112|3@1+ (1,0) [0|7] "" XXX
 SG_ HDP_CtRoadSrfcDistVal : 115|5@1+ (1,0) [0|31] "" XXX

BO_ 485 ADAS_CMD_40_50ms: 16 XXX
 SG_ ADAS_CMD_Crc40Val : 0|16@1+ (1,0) [0|65535] "" XXX
 SG_ ADAS_CMD_AlvCnt40Val : 16|8@1+ (1,0) [0|255] "" XXX
 SG_ RCCW_Sta : 24|1@0+ (1,0) [0|1] "" XXX
 SG_ RCCW_OnOffEquipSt_RCAA : 28|2@1+ (1,0) [0|3] "" XXX
 SG_ RCCW_LtIndSta : 30|1@1+ (1,0) [0|1] "" XXX
 SG_ NEW_SIGNAL_5 : 31|1@0+ (1,0) [0|1] "" XXX
 SG_ RCCW_RtIndSta : 32|2@1+ (1,0) [0|3] "" XXX
 SG_ RCCW_LtSndWrngSta : 34|2@1+ (1,0) [0|3] "" XXX
 SG_ RCCW_RtSndWrngSta : 36|11@1+ (1,0) [0|2047] "" XXX
 SG_ NEW_SIGNAL_8 : 47|8@0+ (1,0) [0|255] "" XXX
 SG_ NEW_SIGNAL_9 : 55|8@0+ (1,0) [0|255] "" XXX
 SG_ RCCA_Deccel_Req : 64|4@1+ (1,0) [0|15] "" XXX
 SG_ RCCA_BrkCmdSta : 68|2@1+ (1,0) [0|3] "" XXX
 SG_ RCCA_LtWrngSta : 70|2@1+ (1,0) [0|3] "" XXX
 SG_ RCCA_RtWrngSta : 72|8@1+ (1,0) [0|255] "" XXX
 SG_ RCCA_Sta : 80|1@0+ (1,0) [0|1] "" XXX
 SG_ RCCA_OnOffEquipSt : 84|4@1+ (1,0) [0|15] "" XXX
 SG_ SEA_Sta : 88|1@0+ (1,0) [0|1] "" XXX
 SG_ SEA_LtTrgtSta : 94|2@1+ (1,0) [0|3] "" XXX
 SG_ SEA_RtTrgtSta : 96|1@0+ (1,0) [0|1] "" XXX
 SG_ SEW_OnOffEquipSta_New : 98|2@1+ (1,0) [0|3] "" XXX
 SG_ SEA_OnOffEquipSta_New : 100|8@1+ (1,0) [0|255] "" XXX
 SG_ NEW_SIGNAL_1 : 108|2@0+ (1,0) [0|3] "" XXX
 SG_ SEA_OnOffEquip3Sta : 126|2@1+ (1,0) [0|3] "" XXX

BO_ 490 ADAS_CMD_32_50ms: 32 XXX
 SG_ ADAS_CMD_Crc32Val : 0|16@1+ (1,0) [0|65535] "" XXX
 SG_ ADAS_CMD_AlvCnt32Val : 16|8@1+ (1,0) [0|255] "" XXX
 SG_ HDA_LCFuncOptUsmSta : 26|3@1+ (1,0) [0|7] "" XXX
 SG_ HDA_LCTurnSigReq : 29|2@1+ (1,0) [0|3] "" XXX
 SG_ SET_ME_1C : 31|1@0+ (1,0) [0|1] "" XXX
 SG_ HDA_LCFuncSta : 32|2@1+ (1,0) [0|3] "" XXX
 SG_ HDA_LtLCAvailSta : 35|5@1+ (1,0) [0|31] "" XXX
 SG_ HDA_RtLCAvailSta : 40|3@1+ (1,0) [0|7] "" XXX
 SG_ HDA_PathSta : 43|3@1+ (1,0) [0|7] "" XXX
 SG_ HDA_FrntLtVehLongPos : 46|1@1+ (1,0) [0|1] "" XXX
 SG_ NEW_SIGNAL_2 : 47|2@0+ (1,0) [0|3] "" XXX
 SG_ NEW_SIGNAL_3 : 55|8@0+ (1,0) [0|255] "" XXX
 SG_ HDA_FrntLtVehLatPos : 64|6@1+ (1,0) [0|31] "" XXX
 SG_ HDA_FrntLtVehSta : 72|2@1+ (1,0) [0|3] "" XXX
 SG_ HDA_FrntRtVehLongPos : 75|5@1+ (1,0) [0|31] "" XXX
 SG_ NEW_SIGNAL_7 : 80|5@1+ (1,0) [0|31] "" XXX
 SG_ HDA_FrntRtVehLatPos : 88|7@1+ (1,0) [0|127] "" XXX
 SG_ HDA_FrntRtVehSta : 96|1@0+ (1,0) [0|1] "" XXX
 SG_ HDP_HzrdLmpReq : 104|2@1+ (1,0) [0|3] "" XXX
 SG_ HDP_HeadLmpReq : 106|3@1+ (1,0) [0|7] "" XXX
 SG_ HDP_WiperReq : 109|5@1+ (1,0) [0|31] "" XXX
 SG_ HDP_DfgReqSta : 114|2@1+ (1,0) [0|3] "" XXX
 SG_ HDP_DrUnlckReqSta : 116|4@1+ (1,0) [0|15] "" XXX
 SG_ HDA_TtlLnNumVal : 120|4@1+ (1,0) [0|15] "" XXX
 SG_ HDA_DrvLnNumVal : 124|15@1+ (1,0) [0|32767] "" XXX
 SG_ HDA_LtVehLongPos : 139|4@1+ (1,0) [0|15] "" XXX
 SG_ NEW_SIGNAL_10 : 143|1@0+ (1,0) [0|1] "" XXX
 SG_ NEW_SIGNAL_11 : 144|3@1+ (1,0) [0|7] "" XXX
 SG_ HDA_LtVehLatPos : 152|6@1+ (1,0) [0|63] "" XXX
 SG_ HDA_LtVehSta : 160|1@0+ (1,0) [0|1] "" XXX
 SG_ HDA_RtVehLongPos : 163|5@1+ (1,0) [0|31] "" XXX
 SG_ NEW_SIGNAL_16 : 168|3@1+ (1,0) [0|7] "" XXX
 SG_ HDA_RtVehLatPos : 172|3@1+ (1,0) [0|7] "" XXX
 SG_ NEW_SIGNAL_15 : 175|1@0+ (1,0) [0|1] "" XXX
 SG_ NEW_SIGNAL_17 : 176|2@1+ (1,0) [0|3] "" XXX
 SG_ HDA_RtVehSta : 184|1@0+ (1,0) [0|1] "" XXX
 SG_ HDA_InfoPUDis2 : 204|4@1+ (1,0) [0|15] "" XXX
 SG_ HDA_LaneCvrtLvlVal : 208|3@1+ (1,0) [0|7] "" XXX
 SG_ NEW_SIGNAL_20 : 212|1@0+ (1,0) [0|1] "" XXX
 SG_ HDA_LtLineLatPos : 232|5@1+ (1,0) [0|31] "" XXX
 SG_ HDA_RtLineLatPos : 240|5@1+ (1,0) [0|31] "" XXX
 SG_ HDA_LCFuncWrnSnd : 248|8@1+ (1,0) [0|255] "" XXX

BO_ 491 HU_USM_E2: 8 XXX
 SG_ PwrDRClosingDrvDrReq : 34|9@1+ (1,0) [0|511] "" XXX
 SG_ PwrDRClosingAstDrReq : 43|2@1+ (1,0) [0|3] "" XXX
 SG_ PwrDRClosingRLDrReq : 45|2@1+ (1,0) [0|3] "" XXX
 SG_ PwrDrClosingRRDrReq : 47|2@1+ (1,0) [0|3] "" XXX
 SG_ USM_BtnIllumiAlwaysOnReq : 49|7@1+ (1,0) [0|127] "" XXX

BO_ 492 HU_USM_E3: 8 XXX
 SG_ USM_AdasISLAEUCntry1Set : 0|8@1+ (1,0) [0|255] "" XXX
 SG_ USM_AdasISLAEUCntryTglSet : 8|8@1+ (1,0) [0|255] "" XXX

BO_ 496 EPB_01_50ms: 8 XXX
 SG_ EPB_Crc1Val : 0|16@1+ (1,0) [0|65535] "" XXX
 SG_ EPB_AlvCnt1Val : 16|8@1+ (1,0) [0|255] "" XXX
 SG_ EPB_LmpStaDis : 24|4@1+ (1,0) [0|15] "" XXX
 SG_ EPB_FlrLmpStaDis : 28|4@1+ (1,0) [0|15] "" XXX
 SG_ EPB_OutDataDis : 32|8@1+ (1,0) [0|255] "" XXX
 SG_ EPB_AlrmReq : 40|2@1+ (1,0) [0|3] "" XXX
 SG_ EPB_SwPosSta : 42|2@1+ (1,0) [0|3] "" XXX
 SG_ EPB_RrBrkLtActvReq : 44|2@1+ (1,0) [0|3] "" XXX
 SG_ EPB_FrcErrSta : 46|2@1+ (1,0) [0|3] "" XXX
 SG_ EPB_DynmBrkFrcReqSigSta : 48|2@1+ (1,0) [0|3] "" XXX
 SG_ EPB_FrcSta : 50|3@1+ (1,0) [0|7] "" XXX
 SG_ EPB_FlSta : 53|3@1+ (1,0) [0|7] "" XXX
 SG_ EPB_EscReqAckSta : 56|2@1+ (1,0) [0|3] "" XXX
 SG_ EPB_DynmBrkFrcReq : 58|6@1+ (1,0) [0|63] "" XXX
 SG_ EPB_ActlFrcVal : 64|16@1+ (1,0) [0|65535] "" XXX
 SG_ EPB_DynmBrkFrcDclReq : 80|8@1+ (1,0) [0|255] "" XXX

BO_ 501 BMS_08_100ms: 8 XXX
 SG_ BMS_Crc8Val : 0|16@1+ (1,0) [0|65535] "" XXX
 SG_ BMS_AlvCnt8Val : 16|8@1+ (1,0) [0|255] "" XXX
 SG_ VCRM_PwmDtyCmdVal : 24|8@1+ (1,0) [0|255] "" XXX
 SG_ VCRM_FanFdbckFreqCVal : 32|8@1+ (1,0) [0|255] "" XXX
 SG_ VCRM_FanFdbckFreqWVal : 40|8@1+ (1,0) [0|255] "" XXX
 SG_ VCRM_FstChrgSta : 48|2@1+ (1,0) [0|3] "" XXX
 SG_ VCRM_NorChgFnshSta : 50|2@1+ (1,0) [0|3] "" XXX
 SG_ VCRM_FanSpdStpSta : 52|4@1+ (1,0) [0|15] "" XXX
 SG_ VCRM_DiagMonVal : 56|8@1+ (1,0) [0|255] "" XXX
 SG_ VCRM_QckChrgRmnTimeVal : 64|16@1+ (1,0) [0|65535] "" XXX
 SG_ VCRM_StndChrgRmnTime120Val : 80|16@1+ (1,0) [0|65535] "" XXX
 SG_ VCRM_QckTrgtCurrReq : 96|16@1+ (1,0) [0|65535] "" XXX
 SG_ VCRM_ChrgFltSubCodVal : 112|16@1+ (1,0) [0|65535] "" XXX
 SG_ VCRM_VcrmReq : 128|2@1+ (1,0) [0|3] "" XXX
 SG_ VCRM_QckMainRlyOnSta : 130|2@1+ (1,0) [0|3] "" XXX
 SG_ VCRM_QckChrgFnshSta : 132|4@1+ (1,0) [0|15] "" XXX
 SG_ VCRM_DomStndChrgRmnTimeVal : 136|16@1+ (1,0) [0|65535] "" XXX
 SG_ VCRM_EuroStndChrgRmnTimeVal : 152|16@1+ (1,0) [0|65535] "" XXX
 SG_ VCRM_RealStndChrgRmnTimeVal : 168|24@1+ (1,0) [0|16777215] "" XXX
 SG_ VCRM_StndChrgRmnTime240Val : 192|16@1+ (1,0) [0|65535] "" XXX
 SG_ VCRM_ScChgTargetSOCSync : 208|8@1+ (1,0) [0|255] "" XXX
 SG_ VCRM_QcChgTargetSOCSync : 216|8@1+ (1,0) [0|255] "" XXX
 SG_ VCRM_EvseFltAlrmSta : 224|2@1+ (1,0) [0|3] "" XXX
 SG_ VCRM_QckChrgPwrCustom : 226|14@1+ (1,0) [0|16383] "" XXX
 SG_ VCRM_WirelessChrgRmnTimeVal : 240|8@1+ (1,0) [0|255] "" XXX

BO_ 506 FR_CMR_02_100ms: 32 XXX
 SG_ FR_CMR_Crc2Val : 0|16@1+ (1,0) [0|65535] "" XXX
 SG_ FR_CMR_AlvCnt2Val : 16|10@1+ (1,0) [0|1023] "" XXX
 SG_ ISLW_SysSta : 26|7@1+ (1,0) [0|127] "" XXX
 SG_ ISLW_SpdCluMainDis : 33|6@1+ (1,0) [0|63] "" XXX
 SG_ SPEED_LIMIT_1 : 39|2@0+ (1,0) [0|3] "" XXX
 SG_ ISLW_SpdNaviMainDis : 41|6@1+ (1,0) [0|63] "" XXX
 SG_ SPEED_LIMIT_2 : 47|7@0+ (1,0) [0|255] "" XXX
 SG_ SECONDARY_LIMIT_1 : 79|8@0+ (1,0) [0|127] "" XXX
 SG_ SECONDARY_LIMIT_2 : 103|8@0+ (1,0) [0|127] "" XXX
 SG_ ISLA_SpdwOffst : 112|7@1+ (1,0) [0|127] "" XXX
 SG_ SPEED_LIMIT_3 : 119|1@0+ (1,0) [0|1] "" XXX
 SG_ ISLA_SwIgnoreReq : 120|1@0+ (1,0) [0|1] "" XXX
 SG_ ARROW_UP : 121|1@0+ (1,0) [0|1] "" XXX
 SG_ ISLA_SpdChgReq : 122|2@1+ (1,0) [0|7] "" XXX
 SG_ ISLA_SpdWrn : 124|4@1+ (1,0) [0|15] "" XXX
 SG_ ISLA_SymFlashMod : 128|1@1+ (1,0) [0|1] "" XXX
 SG_ SPEED_CHANGE_BLINKING : 129|1@1+ (1,0) [0|3] "" XXX
 SG_ ISLA_Popup : 131|2@1+ (1,0) [0|3] "" XXX
 SG_ CHIME_1 : 133|1@0+ (1,0) [0|1] "" XXX
 SG_ ISLA_OptUsmSta : 136|3@1+ (1,0) [0|7] "" XXX
 SG_ ISLA_OffstUsmSta : 139|5@1+ (1,0) [0|31] "" XXX
 SG_ ISLA_Cntry : 144|5@1+ (1,0) [0|31] "" XXX
 SG_ ISLA_AddtnlSign : 149|5@1+ (1,0) [0|31] "" XXX
 SG_ ISLA_SchoolZone : 154|1@1+ (1,0) [0|1] "" XXX
 SG_ SCHOOL_ZONE : 155|1@0+ (1,0) [0|1] "" XXX
 SG_ ISLA_AutoSetSpdSta : 156|8@1+ (1,0) [0|255] "" XXX
 SG_ ISLA_CondInfoDisp : 164|4@1+ (1,0) [0|15] "" XXX
 SG_ ISLA_SndReqSta : 168|3@1+ (1,0) [0|7] "" XXX
 SG_ ISLA_NAOffstUSMSta : 171|5@1+ (1,0) [0|31] "" XXX
 SG_ ISLA_EUCntry1USMSta : 176|8@1+ (1,0) [0|255] "" XXX
 SG_ ISLA_EUCntry2USMSta : 184|8@1+ (1,0) [0|255] "" XXX
 SG_ ISLA_EUCntryVerTyp : 192|4@1+ (1,0) [0|15] "" XXX
 SG_ ISLA_NACntry1USMSta : 196|4@1+ (1,0) [0|15] "" XXX
 SG_ ISLA_NACntry2USMSta : 200|4@1+ (1,0) [0|15] "" XXX
 SG_ ISLA_NACntryVerTyp : 204|4@1+ (1,0) [0|15] "" XXX

BO_ 507 CAM_0x1fb: 32 CAMERA
 SG_ CHECKSUM : 0|16@1+ (1,0) [0|65535] "" XXX
 SG_ COUNTER : 16|8@1+ (1,0) [0|255] "" XXX

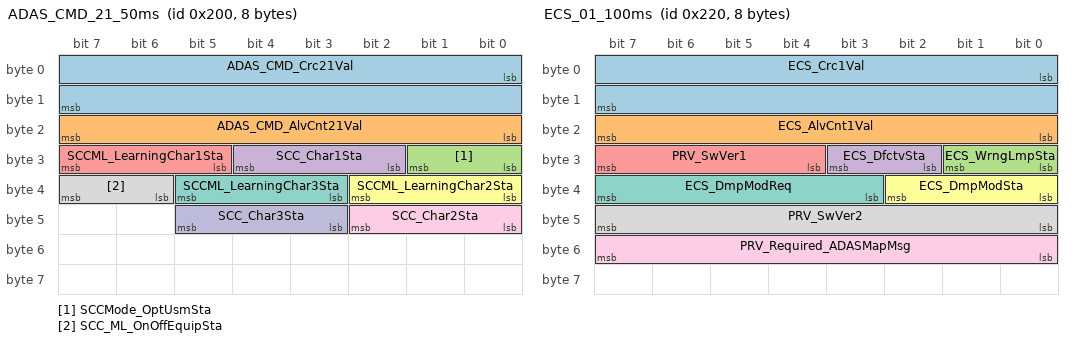
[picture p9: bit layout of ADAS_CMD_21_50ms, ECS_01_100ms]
BO_ 512 ADAS_CMD_21_50ms: 8 XXX
 SG_ ADAS_CMD_Crc21Val : 0|16@1+ (1,0) [0|65535] "" XXX
 SG_ ADAS_CMD_AlvCnt21Val : 16|8@1+ (1,0) [0|255] "" XXX
 SG_ SCCMode_OptUsmSta : 25|2@0+ (1,0) [0|3] "" XXX
 SG_ SCC_Char1Sta : 26|3@1+ (1,0) [0|63] "" XXX
 SG_ SCCML_LearningChar1Sta : 29|3@1+ (1,0) [0|3] "" XXX
 SG_ SCCML_LearningChar2Sta : 32|3@1+ (1,0) [0|63] "" XXX
 SG_ SCCML_LearningChar3Sta : 37|3@0+ (1,0) [0|7] "" XXX
 SG_ SCC_ML_OnOffEquipSta : 38|2@1+ (1,0) [0|3] "" XXX
 SG_ SCC_Char2Sta : 40|3@1+ (1,0) [0|7] "" XXX
 SG_ SCC_Char3Sta : 43|3@1+ (1,0) [0|31] "" XXX

BO_ 513 RADAR_0x201: 32 FRONT_RADAR
 SG_ CHECKSUM : 0|16@1+ (1,0) [0|65535] "" XXX
 SG_ COUNTER : 16|8@1+ (1,0) [0|255] "" XXX

BO_ 517 ICSC_02_100ms: 8 XXX
 SG_ ICU_Crc1Val : 0|12@1+ (1,0) [0|4095] "" XXX
 SG_ ICU_AlvCnt1Val : 12|11@1+ (1,0) [0|2047] "" XXX
 SG_ ICSC_AlvCnt2Val : 16|8@1+ (1,0) [0|255] "" XXX
 SG_ ICU_Update_Enable : 23|1@1+ (1,0) [0|1] "" XXX
 SG_ DMIC_DrvModSta : 24|4@1+ (1,0) [0|15] "" XXX
 SG_ DMIC_SmtShftModSta : 28|4@1+ (1,0) [0|15] "" XXX
 SG_ DMIC_EngModSta : 32|4@1+ (1,0) [0|15] "" XXX
 SG_ DMIC_IndEngModSta : 36|4@1+ (1,0) [0|15] "" XXX
 SG_ DMIC_TmModSta : 40|8@1+ (1,0) [0|255] "" XXX
 SG_ DMIC_EscModSta : 48|4@1+ (1,0) [0|15] "" XXX
 SG_ DMIC_IndEscModSta : 52|4@1+ (1,0) [0|15] "" XXX
 SG_ DMIC_MdpsModSta : 56|4@1+ (1,0) [0|15] "" XXX
 SG_ DMIC_IndMdpsModSta : 60|4@1+ (1,0) [0|15] "" XXX
 SG_ DMIC_EcsModSta : 64|4@1+ (1,0) [0|15] "" XXX
 SG_ DMIC_IndEcsModSta : 68|4@1+ (1,0) [0|15] "" XXX
 SG_ DMIC_AwdModSta : 72|4@1+ (1,0) [0|15] "" XXX
 SG_ DMIC_IndAwdModSta : 76|12@1+ (1,0) [0|4095] "" XXX
 SG_ DMIC_PrflModSta : 88|4@1+ (1,0) [0|15] "" XXX
 SG_ DMIC_IndPrflModSta : 92|4@1+ (1,0) [0|15] "" XXX
 SG_ DMIC_ElsdModSta : 96|4@1+ (1,0) [0|15] "" XXX
 SG_ DMIC_IndElsdModSta : 100|4@1+ (1,0) [0|15] "" XXX
 SG_ DMIC_EsndModSta : 104|4@1+ (1,0) [0|15] "" XXX
 SG_ DMIC_IndEsndModSta : 108|4@1+ (1,0) [0|15] "" XXX
 SG_ DMIC_RwsModSta : 112|4@1+ (1,0) [0|15] "" XXX
 SG_ DMIC_IndRwsModSta : 116|12@1+ (1,0) [0|4095] "" XXX
 SG_ DMIC_VcuModSta : 128|4@1+ (1,0) [0|15] "" XXX
 SG_ DMIC_IndVcuModSta : 132|4@1+ (1,0) [0|15] "" XXX
 SG_ DMIC_DrvModFltSta : 136|4@1+ (1,0) [0|15] "" XXX
 SG_ DMIC_DrvModTyp : 140|4@1+ (1,0) [0|15] "" XXX
 SG_ DMIC_EngFltSta : 144|2@1+ (1,0) [0|3] "" XXX
 SG_ DMIC_TmFltSta : 146|2@1+ (1,0) [0|3] "" XXX
 SG_ DMIC_EscFltSta : 148|2@1+ (1,0) [0|3] "" XXX
 SG_ DMIC_MdpsFltSta : 150|2@1+ (1,0) [0|3] "" XXX
 SG_ DMIC_EcsFltSta : 152|2@1+ (1,0) [0|3] "" XXX
 SG_ DMIC_AwdFltSta : 154|2@1+ (1,0) [0|3] "" XXX
 SG_ DMIC_RevFltSta : 156|2@1+ (1,0) [0|3] "" XXX
 SG_ DMIC_PrflFltSta : 158|2@1+ (1,0) [0|3] "" XXX
 SG_ DMIC_ElsdFltSta : 160|2@1+ (1,0) [0|3] "" XXX
 SG_ DMIC_EsndFltSta : 162|2@1+ (1,0) [0|3] "" XXX
 SG_ DMIC_RwsFltSta : 164|4@1+ (1,0) [0|15] "" XXX
 SG_ DMIC_VcuFltSta : 168|20@1+ (1,0) [0|1048575] "" XXX
 SG_ DMIC_DrvMod2Typ : 188|4@1+ (1,0) [0|15] "" XXX

BO_ 522 ACU_01_100ms: 8 XXX
 SG_ ACU_Crc1Val : 0|16@1+ (1,0) [0|65535] "" XXX
 SG_ ACU_AlvCnt1Val : 16|8@1+ (1,0) [0|255] "" XXX
 SG_ ACU_SysWrngLmpDis : 24|3@1+ (1,0) [0|7] "" XXX
 SG_ ACU_TlltlLmpDis : 27|3@1+ (1,0) [0|7] "" XXX
 SG_ ACU_OdsIDReq : 30|2@1+ (1,0) [0|3] "" XXX
 SG_ SeatBelt_PassBcklFltSta : 32|2@1+ (1,0) [0|3] "" XXX
 SG_ SeatBelt_DrvrBcklFltSta : 34|2@1+ (1,0) [0|3] "" XXX
 SG_ SeatBelt_PassBcklSta : 36|2@1+ (1,0) [0|3] "" XXX
 SG_ SeatBelt_DrvrBcklSta : 38|2@1+ (1,0) [0|3] "" XXX
 SG_ ACU_DiagTrblCodVal : 40|16@1+ (1,0) [0|65535] "" XXX
 SG_ ACU_FltNumVal : 56|8@1+ (1,0) [0|255] "" XXX
 SG_ ACU_ActvFltSta : 64|3@1+ (1,0) [0|7] "" XXX
 SG_ ACU_SdArbgExtTyp : 67|3@1+ (1,0) [0|7] "" XXX
 SG_ ACU_EmerModSta : 70|1@1+ (1,0) [0|1] "" XXX
 SG_ ACU_EvtTrigSta : 71|1@1+ (1,0) [0|1] "" XXX
 SG_ ACU_NumOfEmerModVal : 72|8@1+ (1,0) [0|255] "" XXX
 SG_ ACU_NumOfEvtTrigVal : 80|18@1+ (1,0) [0|262143] "" XXX
 SG_ ACU_HDPSpprtSWVer : 98|6@1+ (1,0) [0|63] "" XXX

BO_ 528 RADAR_0x210: 32 FRONT_RADAR
 SG_ CHECKSUM : 0|16@1+ (1,0) [0|65535] "" XXX
 SG_ COUNTER : 16|8@1+ (1,0) [0|255] "" XXX

BO_ 529 RADAR_0x211: 32 FRONT_RADAR
 SG_ CHECKSUM : 0|16@1+ (1,0) [0|65535] "" XXX
 SG_ COUNTER : 16|8@1+ (1,0) [0|255] "" XXX

BO_ 530 RADAR_0x212: 32 FRONT_RADAR
 SG_ CHECKSUM : 0|16@1+ (1,0) [0|65535] "" XXX
 SG_ COUNTER : 16|8@1+ (1,0) [0|255] "" XXX

BO_ 531 RADAR_0x213: 32 FRONT_RADAR
 SG_ CHECKSUM : 0|16@1+ (1,0) [0|65535] "" XXX
 SG_ COUNTER : 16|8@1+ (1,0) [0|255] "" XXX

BO_ 532 RADAR_0x214: 32 FRONT_RADAR
 SG_ CHECKSUM : 0|16@1+ (1,0) [0|65535] "" XXX
 SG_ COUNTER : 16|8@1+ (1,0) [0|255] "" XXX

BO_ 533 ADAS_CMD_31_50ms_1_ADAS_CMD: 32 XXX
 SG_ DATC_Crc31Val : 0|16@1+ (1,0) [0|65535] "" XXX
 SG_ DATC_AlvCnt31Val : 16|8@1+ (1,0) [0|255] "" XXX

BO_ 534 RADAR_0x216: 32 FRONT_RADAR
 SG_ CHECKSUM : 0|16@1+ (1,0) [0|65535] "" XXX
 SG_ COUNTER : 16|8@1+ (1,0) [0|255] "" XXX

BO_ 535 RADAR_0x217: 32 FRONT_RADAR
 SG_ CHECKSUM : 0|16@1+ (1,0) [0|65535] "" XXX
 SG_ COUNTER : 16|8@1+ (1,0) [0|255] "" XXX

BO_ 536 RADAR_0x218: 32 FRONT_RADAR
 SG_ CHECKSUM : 0|16@1+ (1,0) [0|65535] "" XXX
 SG_ COUNTER : 16|8@1+ (1,0) [0|255] "" XXX

BO_ 537 RADAR_0x219: 32 FRONT_RADAR
 SG_ CHECKSUM : 0|16@1+ (1,0) [0|65535] "" XXX
 SG_ COUNTER : 16|8@1+ (1,0) [0|255] "" XXX

BO_ 538 ADAS_CMD_32_50ms_1_ADAS_CMD: 32 XXX
 SG_ BMS_Crc32Val : 0|16@1+ (1,0) [0|65535] "" XXX
 SG_ BMS_AlvCnt32Val : 16|8@1+ (1,0) [0|255] "" XXX
 SG_ NEV_BMS_ChrgSta_1_VCRM : 32|8@1+ (1,0) [0|255] "" XXX
 SG_ NEV_BMS_BattCurrVal_2_VCRM : 40|16@1+ (1,0) [0|65535] "" XXX
 SG_ NEV_BMS_SocDis_xEV : 56|8@1+ (1,0) [0|255] "" XXX
 SG_ NEV_BMS_IsolResistVal_2_VCRM : 144|8@1+ (1,0) [0|255] "" XXX

BO_ 539 RADAR_0x21b: 32 FRONT_RADAR
 SG_ CHECKSUM : 0|16@1+ (1,0) [0|65535] "" XXX
 SG_ COUNTER : 16|8@1+ (1,0) [0|255] "" XXX

BO_ 540 RADAR_0x21c: 32 FRONT_RADAR
 SG_ CHECKSUM : 0|16@1+ (1,0) [0|65535] "" XXX
 SG_ COUNTER : 16|8@1+ (1,0) [0|255] "" XXX

BO_ 541 RADAR_0x21d: 32 FRONT_RADAR
 SG_ CHECKSUM : 0|16@1+ (1,0) [0|65535] "" XXX
 SG_ COUNTER : 16|8@1+ (1,0) [0|255] "" XXX

BO_ 542 RADAR_0x21e: 32 FRONT_RADAR
 SG_ CHECKSUM : 0|16@1+ (1,0) [0|65535] "" XXX
 SG_ COUNTER : 16|8@1+ (1,0) [0|255] "" XXX

BO_ 543 RADAR_0x21f: 32 FRONT_RADAR
 SG_ CHECKSUM : 0|16@1+ (1,0) [0|65535] "" XXX
 SG_ COUNTER : 16|8@1+ (1,0) [0|255] "" XXX

BO_ 544 ECS_01_100ms: 8 XXX
 SG_ ECS_Crc1Val : 0|16@1+ (1,0) [0|65535] "" XXX
 SG_ ECS_AlvCnt1Val : 16|8@1+ (1,0) [0|255] "" XXX
 SG_ ECS_WrngLmpSta : 24|2@1+ (1,0) [0|3] "" XXX
 SG_ ECS_DfctvSta : 26|2@1+ (1,0) [0|3] "" XXX
 SG_ PRV_SwVer1 : 28|4@1+ (1,0) [0|15] "" XXX
 SG_ ECS_DmpModSta : 32|3@1+ (1,0) [0|7] "" XXX
 SG_ ECS_DmpModReq : 35|5@1+ (1,0) [0|31] "" XXX
 SG_ PRV_SwVer2 : 40|8@1+ (1,0) [0|255] "" XXX
 SG_ PRV_Required_ADASMapMsg : 48|8@1+ (1,0) [0|255] "" XXX

BO_ 549 CLU_02_100ms: 8 XXX
 SG_ CLU_Crc2Val : 0|16@1+ (1,0) [0|65535] "" XXX
 SG_ CLU_AlvCnt2Val : 16|16@1+ (1,0) [0|65535] "" XXX
 SG_ CLU_DTEVal : 32|12@1+ (1,0) [0|4095] "" XXX
 SG_ CLU_TripUnitSta : 44|14@1+ (1,0) [0|16383] "" XXX
 SG_ CLU_LoFuelWrngSta : 58|2@1+ (1,0) [0|3] "" XXX
 SG_ CLU_RefuelDetSta : 60|2@1+ (1,0) [0|3] "" XXX
 SG_ CLU_TerrainMainSwSta : 62|2@1+ (1,0) [0|3] "" XXX
 SG_ CLU_LngSta : 64|5@1+ (1,0) [0|31] "" XXX
 SG_ CLU_SRSWrngLmpSta : 69|3@1+ (1,0) [0|7] "" XXX
 SG_ CLU_OdoVal : 72|32@1+ (1,0) [0|4294967295] "" XXX
 SG_ CLU_DrvngModSwSta : 104|4@1+ (1,0) [0|15] "" XXX
 SG_ CLU_FuelLvlSta : 108|15@1+ (1,0) [0|32767] "" XXX
 SG_ CLU_TerrainModSwSta : 123|5@1+ (1,0) [0|31] "" XXX

BO_ 565 BMS_01_100ms: 8 XXX
 SG_ BMS_Crc1Val : 0|16@1+ (1,0) [0|65535] "" XXX
 SG_ BMS_AlvCnt1Val : 16|8@1+ (1,0) [0|255] "" XXX
 SG_ xEV_OverChrgWrnSta : 24|2@1+ (1,0) [0|3] "" XXX
 SG_ xEV_RlyOffRcvSta : 26|2@1+ (1,0) [0|3] "" XXX
 SG_ xEV_PreChrgSta : 28|4@1+ (1,0) [0|15] "" XXX
 SG_ xEV_BattChrgLimVal : 32|16@1+ (1,0) [0|65535] "" XXX
 SG_ xEV_BattDischrgLimVal : 48|16@1+ (1,0) [0|65535] "" XXX
 SG_ xEV_BatCoolPwrPerm : 64|6@1+ (1,0) [0|63] "" XXX
 SG_ xEV_SysWrnSta : 70|2@1+ (1,0) [0|3] "" XXX
 SG_ xEV_SysCtrlablSta : 72|2@1+ (1,0) [0|3] "" XXX
 SG_ xEV_SysRdySta : 74|2@1+ (1,0) [0|3] "" XXX
 SG_ xEV_SocDecVal : 76|4@1+ (1,0) [0|15] "" XXX
 SG_ xEV_SocVal : 80|8@1+ (1,0) [0|255] "" XXX
 SG_ xEV_AAFOpReq : 88|3@1+ (1,0) [0|7] "" XXX
 SG_ xEV_BatEvtAlarm : 91|3@1+ (1,0) [0|7] "" XXX
 SG_ xEV_PwrderatingSta : 94|2@1+ (1,0) [0|3] "" XXX
 SG_ xEV_ChgStopFlagSta : 96|8@1+ (1,0) [0|255] "" XXX
 SG_ xEV_BattPckVoltVal : 104|40@1+ (1,0) [0|1099511627775] "" XXX
 SG_ xEV_BattRmndEnrgVal : 144|10@1+ (1,0) [0|1023] "" XXX
 SG_ xEV_MtrPwmOnReq : 154|2@1+ (1,0) [0|3] "" XXX
 SG_ xEV_HsgPwmOnReq : 156|4@1+ (1,0) [0|15] "" XXX
 SG_ xEV_IsolDetOpSta : 160|24@1+ (1,0) [0|16777215] "" XXX
 SG_ xEV_CrshActvRcvSta : 184|2@1+ (1,0) [0|3] "" XXX
 SG_ xEV_BmsHvIntlockReq : 186|2@1+ (1,0) [0|3] "" XXX
 SG_ xEV_RlyWeldingSta : 188|36@1+ (1,0) [0|68719476735] "" XXX
 SG_ xEV_BmsWakeUpModSta : 224|8@1+ (1,0) [0|255] "" XXX

BO_ 576 HU_DSW: 32 XXX
 SG_ HeadPoseYawStat : 0|5@1+ (1,0) [0|31] "" XXX
 SG_ SymSta : 5|3@1+ (1,0) [0|7] "" XXX
 SG_ LeftEyeOpenStat : 8|5@1+ (1,0) [0|31] "" XXX
 SG_ EyeOpenStat : 13|3@1+ (1,0) [0|7] "" XXX
 SG_ RightEyeOpenStat : 16|5@1+ (1,0) [0|31] "" XXX
 SG_ LatestNumBlink : 21|3@1+ (1,0) [0|7] "" XXX
 SG_ HeadPosePitchStat : 24|4@1+ (1,0) [0|15] "" XXX
 SG_ FaceDectStat : 28|2@1+ (1,0) [0|3] "" XXX
 SG_ CamBlckdSta : 30|2@1+ (1,0) [0|3] "" XXX
 SG_ EyeGazePitchStat : 32|4@1+ (1,0) [0|15] "" XXX
 SG_ FakeStat : 36|2@1+ (1,0) [0|3] "" XXX
 SG_ DistWrngTypSta : 38|2@1+ (1,0) [0|3] "" XXX
 SG_ PerclosStat : 40|2@1+ (1,0) [0|3] "" XXX
 SG_ LongBlinkStat : 42|2@1+ (1,0) [0|3] "" XXX
 SG_ TalkStat : 44|2@1+ (1,0) [0|3] "" XXX
 SG_ DistFtgWrngSta : 46|2@1+ (1,0) [0|3] "" XXX
 SG_ EyeGazeYawStat : 48|5@1+ (1,0) [0|31] "" XXX
 SG_ EyeStat : 53|9@1+ (1,0) [0|511] "" XXX
 SG_ LatestLongClosedStat : 62|2@1+ (1,0) [0|3] "" XXX

BO_ 577 HU_APSU_PE: 8 XXX
 SG_ C_AstBolsterInfSw_HU : 0|2@1+ (1,0) [0|3] "" XXX
 SG_ C_AstBolsterDefSw_HU : 2|2@1+ (1,0) [0|3] "" XXX
 SG_ C_AstFootrestFldSw_HU : 4|2@1+ (1,0) [0|3] "" XXX
 SG_ C_AstFootrestUnFldSw_HU : 6|8@1+ (1,0) [0|255] "" XXX
 SG_ C_RLHrestUpSw_HU : 14|2@1+ (1,0) [0|3] "" XXX
 SG_ C_RLHrestDnSw_HU : 16|2@1+ (1,0) [0|3] "" XXX
 SG_ C_RLHrestFwdSw_HU : 18|2@1+ (1,0) [0|3] "" XXX
 SG_ C_RLHrestBwdSw_HU : 20|2@1+ (1,0) [0|3] "" XXX
 SG_ C_RLLumbarUpSw_HU : 22|2@1+ (1,0) [0|3] "" XXX
 SG_ C_RLLumbarMidSw_HU : 24|2@1+ (1,0) [0|3] "" XXX
 SG_ C_RLLumbarLowSw_HU : 26|2@1+ (1,0) [0|3] "" XXX
 SG_ C_RLLumbarDefSw_HU : 28|2@1+ (1,0) [0|3] "" XXX
 SG_ C_RLBolsterInfSw_HU : 30|2@1+ (1,0) [0|3] "" XXX
 SG_ C_RLBolsterDefSw_HU : 32|4@1+ (1,0) [0|15] "" XXX
 SG_ C_AstHrestUpSw_HU : 36|2@1+ (1,0) [0|3] "" XXX
 SG_ C_AstHrestDnSw_HU : 38|8@1+ (1,0) [0|255] "" XXX
 SG_ C_AstHrestFwdSw_HU : 46|8@1+ (1,0) [0|255] "" XXX
 SG_ C_AstHrestBwdSw_HU : 54|2@1+ (1,0) [0|3] "" XXX

BO_ 578 HU_APSU_PE: 8 XXX
 SG_ C_RRLegSupFwdSw_HU : 0|2@1+ (1,0) [0|3] "" XXX
 SG_ C_RRLegSupBwdSw_HU : 2|2@1+ (1,0) [0|3] "" XXX
 SG_ C_RRLegSupUpSw_HU : 4|2@1+ (1,0) [0|3] "" XXX
 SG_ C_RRLegSupDnSw_HU : 6|2@1+ (1,0) [0|3] "" XXX
 SG_ C_RRHrestUpSw_HU : 8|2@1+ (1,0) [0|3] "" XXX
 SG_ C_RRHrestDnSw_HU : 10|2@1+ (1,0) [0|3] "" XXX
 SG_ C_RRHrestFwdSw_HU : 12|2@1+ (1,0) [0|3] "" XXX
 SG_ C_RRHrestBwdSw_HU : 14|2@1+ (1,0) [0|3] "" XXX
 SG_ C_RRLumbarUpSw_HU : 16|2@1+ (1,0) [0|3] "" XXX
 SG_ C_RRLumbarMidSw_HU : 18|2@1+ (1,0) [0|3] "" XXX
 SG_ C_RRLumbarLowSw_HU : 20|2@1+ (1,0) [0|3] "" XXX
 SG_ C_RRLumbarDefSw_HU : 22|2@1+ (1,0) [0|3] "" XXX
 SG_ C_RRBolsterInfSw_HU : 24|16@1+ (1,0) [0|65535] "" XXX
 SG_ C_RROneTchNValueSet : 40|3@1+ (1,0) [0|7] "" XXX
 SG_ C_RLOneTchNValueSet : 43|3@1+ (1,0) [0|7] "" XXX
 SG_ C_RRBolsterDefSw_HU : 46|4@1+ (1,0) [0|15] "" XXX
 SG_ C_AstRlxTiltUpSw_HU : 50|2@1+ (1,0) [0|3] "" XXX
 SG_ C_AstRlxTiltDnSw_HU : 52|2@1+ (1,0) [0|3] "" XXX
 SG_ C_RLRSEUpSw_HU : 54|2@1+ (1,0) [0|3] "" XXX
 SG_ C_RLRSEDnSw_HU : 56|2@1+ (1,0) [0|3] "" XXX
 SG_ C_RRRSEUpSw_HU : 58|2@1+ (1,0) [0|3] "" XXX
 SG_ C_RRRSEDnSw_HU : 60|4@1+ (1,0) [0|15] "" XXX

BO_ 592 MCU_03_100ms: 8 XXX
 SG_ MCU_Crc3Val : 0|16@1+ (1,0) [0|65535] "" XXX
 SG_ MCU_AlvCnt3Val : 16|8@1+ (1,0) [0|255] "" XXX
 SG_ MCU_Mg1Grp1FltCodVal : 24|8@1+ (1,0) [0|255] "" XXX
 SG_ MCU_Mg1Grp2FltCodVal : 32|8@1+ (1,0) [0|255] "" XXX
 SG_ MCU_Mg1Grp3FltCodVal : 40|8@1+ (1,0) [0|255] "" XXX
 SG_ MCU_Mg1Grp4FltCodVal : 48|8@1+ (1,0) [0|255] "" XXX
 SG_ MCU_Mg1Grp5FltCodVal : 56|8@1+ (1,0) [0|255] "" XXX
 SG_ MCU_Mg1Grp6FltCodVal : 64|8@1+ (1,0) [0|255] "" XXX
 SG_ MCU_Mg1GrpUFltCodVal : 72|8@1+ (1,0) [0|255] "" XXX
 SG_ MCU_Mg1Aaf1OpReq : 80|3@1+ (1,0) [0|7] "" XXX
 SG_ MCU_Mg1Aaf1ActSta : 83|3@1+ (1,0) [0|7] "" XXX
 SG_ MCU_Mg1Aaf1FltSta : 86|2@1+ (1,0) [0|3] "" XXX
 SG_ MCU_Mg1Aaf2OpReq : 88|3@1+ (1,0) [0|7] "" XXX
 SG_ MCU_Mg1Aaf2ActSta : 91|3@1+ (1,0) [0|7] "" XXX
 SG_ MCU_Mg1Aaf2FltSta : 94|2@1+ (1,0) [0|3] "" XXX
 SG_ MCU_Mg1Aaf3OpReq : 96|3@1+ (1,0) [0|7] "" XXX
 SG_ MCU_Mg1Aaf3ActSta : 99|3@1+ (1,0) [0|7] "" XXX
 SG_ MCU_Mg1Aaf3FltSta : 102|8@1+ (1,0) [0|255] "" XXX
 SG_ MCU_Mg1AafWrnLampReq : 110|2@1+ (1,0) [0|3] "" XXX
 SG_ MCU_Mg1Eop1ProtectModeLIN : 112|2@1+ (1,0) [0|3] "" XXX
 SG_ MCU_Mg1Eop1FltStatusLIN : 114|2@1+ (1,0) [0|3] "" XXX
 SG_ MCU_Mg1Eop1MalFuncStatus : 116|2@1+ (1,0) [0|3] "" XXX
 SG_ MCU_Mg1Eop1ForcedOpStatus : 118|2@1+ (1,0) [0|3] "" XXX
 SG_ MCU_Mg1Eop1ActSpdRpmLIN : 120|8@1+ (1,0) [0|255] "" XXX
 SG_ MCU_Mg1Eop1SpdRpmReqLIN : 128|8@1+ (1,0) [0|255] "" XXX
 SG_ MCU_Mg1EwpClntDiagEnblStatus : 136|2@1+ (1,0) [0|3] "" XXX
 SG_ MCU_Mg1EwpClntSuffDisp : 138|2@1+ (1,0) [0|3] "" XXX
 SG_ MCU_Mg1Ewp1MalFuncStatus : 140|2@1+ (1,0) [0|3] "" XXX
 SG_ MCU_Mg1Ewp1ForcedOpStatus : 142|2@1+ (1,0) [0|3] "" XXX
 SG_ MCU_Mg1Ewp1ProtectModeLIN : 144|2@1+ (1,0) [0|3] "" XXX
 SG_ MCU_Mg1Ewp1FltStatusLIN : 146|2@1+ (1,0) [0|3] "" XXX
 SG_ MCU_Mg1FatcLpChgInh : 148|4@1+ (1,0) [0|15] "" XXX
 SG_ MCU_Mg1Ewp1SpdRpmReqLIN : 152|8@1+ (1,0) [0|255] "" XXX
 SG_ MCU_Mg1Ewp1ActSpdRpmLIN : 160|8@1+ (1,0) [0|255] "" XXX
 SG_ MCU_Mg1PwrAvnKwVal : 168|10@1+ (1,0) [0|1023] "" XXX
 SG_ MCU_Mg1MotMaxPwrSpec : 178|6@1+ (1,0) [0|63] "" XXX
 SG_ MCU_Mg1OilTempVal : 184|8@1+ (1,0) [0|255] "" XXX

BO_ 593 RADAR_0x251: 16 FRONT_RADAR
 SG_ CHECKSUM : 0|16@1+ (1,0) [0|65535] "" XXX
 SG_ COUNTER : 16|8@1+ (1,0) [0|255] "" XXX

BO_ 597 LDC_01_100ms: 8 XXX
 SG_ LDC_Crc1Val : 0|16@1+ (1,0) [0|65535] "" XXX
 SG_ LDC_AlvCnt1Val : 16|8@1+ (1,0) [0|255] "" XXX
 SG_ LDC_CpuRdySta : 24|2@1+ (1,0) [0|3] "" XXX
 SG_ LDC_SysCtrlablSta : 26|2@1+ (1,0) [0|3] "" XXX
 SG_ LDC_SysOpSta : 28|2@1+ (1,0) [0|3] "" XXX
 SG_ LDC_PwrDeratingSta : 30|2@1+ (1,0) [0|3] "" XXX
 SG_ LDC_AuxBattWrnLmpReq : 32|2@1+ (1,0) [0|3] "" XXX
 SG_ LDC_AuxBattWrnAlrmReq : 34|2@1+ (1,0) [0|3] "" XXX
 SG_ LDC_AuxBattChrgReq : 36|2@1+ (1,0) [0|3] "" XXX
 SG_ LDC_AuxBattChrgRstReq : 38|2@1+ (1,0) [0|3] "" XXX
 SG_ LDC_SrvLmpReq : 40|2@1+ (1,0) [0|3] "" XXX
 SG_ LDC_SysFltSta : 42|10@1+ (1,0) [0|1023] "" XXX
 SG_ LDC_LSActCurrVal : 52|12@1+ (1,0) [0|4095] "" XXX
 SG_ LDC_RadFanRpmDutyVal : 64|8@1+ (1,0) [0|255] "" XXX
 SG_ LDC_LSActVoltVal : 72|8@1+ (1,0) [0|255] "" XXX
 SG_ LDC_EwpRpmCtrlVal : 80|8@1+ (1,0) [0|255] "" XXX
 SG_ LDC_PwrMonVal : 88|8@1+ (1,0) [0|255] "" XXX
 SG_ LDC_SysTempVal : 96|8@1+ (1,0) [0|255] "" XXX
 SG_ LDC_SysMainSta : 104|8@1+ (1,0) [0|255] "" XXX
 SG_ LDC_SysSubSta : 112|8@1+ (1,0) [0|255] "" XXX
 SG_ LDC_LSCmdVoltVal : 120|8@1+ (1,0) [0|255] "" XXX
 SG_ LDC_LoadPwrSumVal : 128|8@1+ (1,0) [0|255] "" XXX
 SG_ LDC_HSActVoltVal : 136|22@1+ (1,0) [0|4194303] "" XXX
 SG_ LDC_BmsMsgLstSta : 158|2@1+ (1,0) [0|3] "" XXX
 SG_ LDC_McuMsgLstSta : 160|2@1+ (1,0) [0|3] "" XXX
 SG_ LDC_VcuMsgLstSta : 162|2@1+ (1,0) [0|3] "" XXX
 SG_ LDC_SysAreaVal : 164|4@1+ (1,0) [0|15] "" XXX
 SG_ LDC_DevStepSta : 168|4@1+ (1,0) [0|15] "" XXX
 SG_ LDC_RelVerVal : 172|8@1+ (1,0) [0|255] "" XXX
 SG_ LDC_RomSta : 180|2@1+ (1,0) [0|3] "" XXX
 SG_ LDC_TestVerVal : 182|4@1+ (1,0) [0|15] "" XXX
 SG_ LDC_VrvState : 186|6@1+ (1,0) [0|63] "" XXX
 SG_ LDC_CtSnsrVoltVal : 192|16@1+ (1,0) [0|65535] "" XXX
 SG_ LDC_EAOutVoltVal : 208|8@1+ (1,0) [0|255] "" XXX
 SG_ LDC_SSFMVal : 216|2@1+ (1,0) [0|3] "" XXX
 SG_ LDC_CtSnsrFltCntVal : 218|4@1+ (1,0) [0|15] "" XXX
 SG_ LDC_OCHSCntVal : 222|4@1+ (1,0) [0|15] "" XXX
 SG_ LDC_VBVoltVal : 226|8@1+ (1,0) [0|255] "" XXX
 SG_ LDC_AAFOpReq : 234|3@1+ (1,0) [0|7] "" XXX
 SG_ LDC_VcrmReq : 237|3@1+ (1,0) [0|7] "" XXX

BO_ 599 RRPSM_02_00ms: 8 XXX
 SG_ RR_SHVU_SeatOptSta : 0|3@1+ (1,0) [0|7] "" XXX
 SG_ C_RH_Folding_SW : 2|2@1+ (1,0) [0|3] "" XXX
 SG_ RR_SHVU_SeatHtOperSta : 3|5@1+ (1,0) [0|31] "" XXX
 SG_ C_LH_Unfolding_SW : 4|2@1+ (1,0) [0|3] "" XXX
 SG_ C_LH_Folding_SW : 6|2@1+ (1,0) [0|3] "" XXX
 SG_ RRPSM_RearModeWngDis : 8|6@1+ (1,0) [0|63] "" XXX
 SG_ RRIMS_AMPBzrReq : 14|2@1+ (1,0) [0|3] "" XXX

BO_ 602 BMS_04_100ms: 8 XXX
 SG_ BMS_Crc4Val : 0|16@1+ (1,0) [0|65535] "" XXX
 SG_ BMS_AlvCnt4Val : 16|8@1+ (1,0) [0|255] "" XXX
 SG_ EV_LoTempSta : 24|2@1+ (1,0) [0|3] "" XXX
 SG_ EV_BattHtrSta : 26|2@1+ (1,0) [0|3] "" XXX
 SG_ EV_HiTempSta : 28|2@1+ (1,0) [0|3] "" XXX
 SG_ xEV_WinterModeSta : 30|2@1+ (1,0) [0|3] "" XXX
 SG_ EV_TrgtVoltVal : 32|16@1+ (1,0) [0|65535] "" XXX
 SG_ EV_TrgtCurrVal : 48|16@1+ (1,0) [0|65535] "" XXX
 SG_ EV_CombInltLkReq : 64|2@1+ (1,0) [0|3] "" XXX
 SG_ EV_EvseFltAlrmSta : 66|2@1+ (1,0) [0|3] "" XXX
 SG_ EV_FstChrgSta : 68|2@1+ (1,0) [0|3] "" XXX
 SG_ EV_CurrDmndRdySta : 70|2@1+ (1,0) [0|3] "" XXX
 SG_ EV_PlcChrgFltSubCodVal : 72|8@1+ (1,0) [0|255] "" XXX
 SG_ EV_QckChrgRmnTimeVal : 80|16@1+ (1,0) [0|65535] "" XXX
 SG_ EV_AvlblEnrgVal : 96|16@1+ (1,0) [0|65535] "" XXX
 SG_ EV_HtrTemp1Val : 112|16@1+ (1,0) [0|65535] "" XXX
 SG_ EV_ChrgRdySta : 128|2@1+ (1,0) [0|3] "" XXX
 SG_ EV_QckChrgCmpltSta : 130|2@1+ (1,0) [0|3] "" XXX
 SG_ EV_ChrgCmpltSta : 132|2@1+ (1,0) [0|3] "" XXX
 SG_ EV_PlcChrgRdySta : 134|2@1+ (1,0) [0|3] "" XXX
 SG_ EV_QuickTrgtSocVal : 136|8@1+ (1,0) [0|255] "" XXX
 SG_ xEV_BatHeatPwrMonCon_W : 144|8@1+ (1,0) [0|255] "" XXX
 SG_ xEV_BatHeatPwrSum_Wh : 152|8@1+ (1,0) [0|255] "" XXX
 SG_ EV_ChrgSubCodVal : 160|8@1+ (1,0) [0|255] "" XXX
 SG_ EV_NRlyOnSta : 168|2@1+ (1,0) [0|3] "" XXX
 SG_ EV_PRlyOnSta : 170|2@1+ (1,0) [0|3] "" XXX
 SG_ EV_ChrgFnshSta : 172|4@1+ (1,0) [0|15] "" XXX
 SG_ EV_BatteryConditioning_EV_HU : 174|2@1+ (1,0) [0|3] "" XXX
 SG_ EV_GBT_NumOfCellsVal : 176|8@1+ (1,0) [0|255] "" XXX
 SG_ EV_GBT_RatedCapacityVal : 184|8@1+ (1,0) [0|255] "" XXX
 SG_ EV_GBT_MaxCellVoltNumVal : 192|8@1+ (1,0) [0|255] "" XXX
 SG_ EV_GBT_MaxCellTempNumVal : 200|8@1+ (1,0) [0|255] "" XXX
 SG_ EV_GBT_MinCellTempNumVal : 208|8@1+ (1,0) [0|255] "" XXX
 SG_ EV_GBT_MaxCellModNum : 216|4@1+ (1,0) [0|15] "" XXX
 SG_ EV_GBT_BSM_CellVoltSts : 220|2@1+ (1,0) [0|3] "" XXX
 SG_ EV_GBT_BSM_SOCSts : 222|2@1+ (1,0) [0|3] "" XXX
 SG_ EV_GBT_BSM_OverCurrSts : 224|2@1+ (1,0) [0|3] "" XXX
 SG_ EV_GBT_BSM_BatHighTempSts : 226|2@1+ (1,0) [0|3] "" XXX
 SG_ EV_GBT_BSM_IsolSts : 228|2@1+ (1,0) [0|3] "" XXX
 SG_ EV_GBT_BSM_BMSChargingSts : 230|2@1+ (1,0) [0|3] "" XXX
 SG_ EV_GBT_BST_SOCEndSts : 232|2@1+ (1,0) [0|3] "" XXX
 SG_ EV_GBT_BST_OverPactVoltSts : 234|2@1+ (1,0) [0|3] "" XXX
 SG_ EV_GBT_BST_OverCellVoltSts : 236|2@1+ (1,0) [0|3] "" XXX
 SG_ EV_GBT_BST_OverTempSts : 238|2@1+ (1,0) [0|3] "" XXX
 SG_ xEV_BatPwrSum_Kwh : 240|8@1+ (1,0) [0|255] "" XXX

BO_ 608 EMS_05_100ms: 8 XXX
 SG_ EMS_Crc5Val : 0|16@1+ (1,0) [0|65535] "" XXX
 SG_ EMS_AlvCnt5Val : 16|8@1+ (1,0) [0|255] "" XXX
 SG_ ENG_ImmoLmpSta : 24|2@1+ (1,0) [0|3] "" XXX
 SG_ ENG_MilSta : 26|2@1+ (1,0) [0|3] "" XXX
 SG_ ENG_ImmoSta : 28|2@1+ (1,0) [0|3] "" XXX
 SG_ OBD_RbmInhbtSta : 30|2@1+ (1,0) [0|3] "" XXX
 SG_ ENG_AtmsphPrsrVal : 32|8@1+ (1,0) [0|255] "" XXX
 SG_ ENG_AltFdbckLoadVal : 40|8@1+ (1,0) [0|255] "" XXX
 SG_ ENG_BattVoltVal : 48|8@1+ (1,0) [0|255] "" XXX
 SG_ ENG_FuelTempVal : 56|8@1+ (1,0) [0|255] "" XXX
 SG_ SCC_DrvOvrRidSta : 64|2@1+ (1,0) [0|3] "" XXX
 SG_ SCC_SccFlrDetSta : 66|2@1+ (1,0) [0|3] "" XXX
 SG_ SCC_FuncFlrDetSta : 68|2@1+ (1,0) [0|3] "" XXX
 SG_ SCC_SccOffStaDetSta : 70|2@1+ (1,0) [0|3] "" XXX
 SG_ SCC_BrkLtSwFlrDetSta : 72|4@1+ (1,0) [0|15] "" XXX
 SG_ SCC_StrtLimFuncSta : 76|2@1+ (1,0) [0|3] "" XXX
 SG_ EMS_SafetyFunctSta : 78|2@1+ (1,0) [0|3] "" XXX
 SG_ InAirTempVal : 80|8@1+ (1,0) [0|255] "" XXX
 SG_ OBD_RbmSta : 88|7@1+ (1,0) [0|127] "" XXX
 SG_ AAF_WrnLamp : 95|1@1+ (1,0) [0|1] "" XXX
 SG_ OBD_IgnCycCntVal : 96|16@1+ (1,0) [0|65535] "" XXX
 SG_ OBD_DnmntrCalcVal : 112|64@1+ (1,0) [0|1.84467440737096e+19] "" XXX
 SG_ ENG_TransmsnTyp : 176|6@1+ (1,0) [0|63] "" XXX
 SG_ ENG_IsgEquipped : 182|2@1+ (1,0) [0|3] "" XXX
 SG_ ENG_EngDsplceTyp : 184|8@1+ (1,0) [0|255] "" XXX
 SG_ ENG_EngTyp4 : 192|2@1+ (1,0) [0|3] "" XXX
 SG_ ENG_EngTyp3 : 194|2@1+ (1,0) [0|3] "" XXX
 SG_ ENG_EngTyp2 : 196|4@1+ (1,0) [0|15] "" XXX
 SG_ ENG_EngTyp1 : 200|4@1+ (1,0) [0|15] "" XXX
 SG_ ENG_S_F : 204|2@1+ (1,0) [0|3] "" XXX
 SG_ ENG_S_F_GEN : 206|3@1+ (1,0) [0|7] "" XXX
 SG_ ENG_IsgDispDetail : 209|5@1+ (1,0) [0|31] "" XXX
 SG_ ENG_TqStndValExt : 214|14@1+ (1,0) [0|16383] "" XXX
 SG_ ENG_KNK_Warning : 228|1@1+ (1,0) [0|1] "" XXX
 SG_ ENG_OilLifeRatio : 229|7@1+ (1,0) [0|127] "" XXX
 SG_ ENG_OilLifeEna : 236|2@1+ (1,0) [0|3] "" XXX
 SG_ ENG_OilLifeWarn : 238|3@1+ (1,0) [0|7] "" XXX
 SG_ ENG_PETyp : 241|7@1+ (1,0) [0|127] "" XXX

BO_ 619 HU_WCCU_E: 8 XXX
 SG_ HU_WCCU_Selected_GA_SSID : 3|5@1+ (1,0) [0|31] "" XXX

BO_ 624 HU_GNSS_01_200ms: 8 XXX
 SG_ ccIC_HU_GNSS_fix_source : 48|6@1+ (1,0) [0|63] "" XXX
 SG_ ccIC_HU_GNSS_2D_fix_indicator : 54|1@1+ (1,0) [0|1] "" XXX
 SG_ ccIC_HU_GNSS_DGPS_status : 55|1@1+ (1,0) [0|1] "" XXX
 SG_ ccIC_HU_GNSS_Position_status : 56|1@1+ (1,0) [0|1] "" XXX
 SG_ ccIC_HU_GNSS_Altitude_status : 57|1@1+ (1,0) [0|1] "" XXX
 SG_ ccIC_HU_GNSS_Heading_status : 58|1@1+ (1,0) [0|1] "" XXX
 SG_ ccIC_HU_GNSS_Speed_status : 59|1@1+ (1,0) [0|1] "" XXX
 SG_ ccIC_HU_GNSS_Timesource : 60|4@1+ (1,0) [0|15] "" XXX
 SG_ ccIC_HU_GNSS_Latitude : 64|32@1+ (1,0) [0|4294967295] "" XXX
 SG_ ccIC_HU_GNSS_Longitude : 96|8@1+ (1,0) [0|255] "" XXX
 SG_ ccIC_HU_GNSS_Altitude : 128|32@1+ (1,0) [0|4294967295] "" XXX
 SG_ ccIC_HU_GNSS_Heading : 160|16@1+ (1,0) [0|65535] "" XXX
 SG_ ccIC_HU_GNSS_Speed : 176|8@1+ (1,0) [0|255] "" XXX
 SG_ ccIC_HU_GNSS_Position_accuracy : 192|16@1+ (1,0) [0|65535] "" XXX
 SG_ ccIC_HU_GNSS_Altitude_accuracy : 208|16@1+ (1,0) [0|65535] "" XXX
 SG_ ccIC_HU_GNSS_Heading_accuracy : 224|16@1+ (1,0) [0|65535] "" XXX
 SG_ ccIC_HU_GNSS_Speed_accuracy : 240|8@1+ (1,0) [0|255] "" XXX

BO_ 625 HU_GNSS_05_1000ms: 8 XXX
 SG_ ccIC_HU_GNSS_Validity : 32|8@1+ (1,0) [0|255] "" XXX
 SG_ ccIC_HU_GNSS_Latitude_error : 64|32@1+ (1,0) [0|4294967295] "" XXX
 SG_ ccIC_HU_GNSS_Longitude_error : 96|8@1+ (1,0) [0|255] "" XXX
 SG_ ccIC_HU_GNSS_Altitude_error : 128|64@1+ (1,0) [0|1.84467440737096e+19] "" XXX
 SG_ ccIC_HU_GNSS_Horizontal_speed_error : 160|64@1+ (1,0) [0|1.84467440737096e+19] "" XXX
 SG_ ccIC_HU_GNSS_Vertical_speed_error : 192|8@1+ (1,0) [0|255] "" XXX
 SG_ ccIC_HU_GNSS_Heading_error : 224|8@1+ (1,0) [0|255] "" XXX

BO_ 626 HU_GNSS_09_1000ms: 8 XXX
 SG_ ccIC_HU_GNSS_UTC_year : 32|16@1+ (1,0) [0|65535] "" XXX
 SG_ ccIC_HU_GNSS_UTC_month : 48|8@1+ (1,0) [0|255] "" XXX
 SG_ ccIC_HU_GNSS_UTC_day : 56|8@1+ (1,0) [0|255] "" XXX
 SG_ ccIC_HU_GNSS_UTC_hour : 64|8@1+ (1,0) [0|255] "" XXX
 SG_ ccIC_HU_GNSS_UTC_min : 72|8@1+ (1,0) [0|255] "" XXX
 SG_ ccIC_HU_GNSS_UTC_sec : 80|8@1+ (1,0) [0|255] "" XXX
 SG_ ccIC_HU_GNSS_UTC_offset : 88|8@1+ (1,0) [0|255] "" XXX
 SG_ ccIC_HU_GNSS_PDOP : 96|16@1+ (1,0) [0|65535] "" XXX
 SG_ ccIC_HU_GNSS_HDOP : 112|16@1+ (1,0) [0|65535] "" XXX
 SG_ ccIC_HU_GNSS_VDOP : 128|8@1+ (1,0) [0|255] "" XXX
 SG_ ccIC_HU_GNSS_DGPS_age : 144|8@1+ (1,0) [0|255] "" XXX
 SG_ ccIC_HU_GNSS_Fix_status : 152|4@1+ (1,0) [0|15] "" XXX
 SG_ ccIC_HU_GNSS_TimeSource : 156|4@1+ (1,0) [0|15] "" XXX
 SG_ ccIC_HU_GNSS_search : 160|4@1+ (1,0) [0|15] "" XXX
 SG_ ccIC_HU_GNSS_DST : 164|4@1+ (1,0) [0|15] "" XXX
 SG_ ccIC_HU_GNSS_SV_count : 168|8@1+ (1,0) [0|255] "" XXX
 SG_ ccIC_HU_GNSS_TimezoneOffset : 176|8@1+ (1,0) [0|255] "" XXX

BO_ 627 HU_GNSS_12_1000ms: 8 XXX
 SG_ ccIC_HU_MM_Latitude : 64|32@1+ (1,0) [0|4294967295] "" XXX
 SG_ ccIC_HU_MM_Longitude : 96|8@1+ (1,0) [0|255] "" XXX
 SG_ ccIC_HU_MM_Altitude : 128|32@1+ (1,0) [0|4294967295] "" XXX
 SG_ ccIC_HU_MM_Heading : 160|8@1+ (1,0) [0|255] "" XXX
 SG_ ccIC_GNSS_MM_type : 192|8@1+ (1,0) [0|255] "" XXX

BO_ 628 HU_GNSS_15_100ms: 8 XXX
 SG_ ccIC_HU_DR_Position_Status : 40|1@1+ (1,0) [0|1] "" XXX
 SG_ ccIC_HU_DR_Altitude_Status : 41|1@1+ (1,0) [0|1] "" XXX
 SG_ ccIC_HU_DR_Heading_Status : 42|1@1+ (1,0) [0|1] "" XXX
 SG_ ccIC_HU_DR_Speed_Status : 43|1@1+ (1,0) [0|1] "" XXX
 SG_ ccIC_HU_DR_DirectionSwitch_Sta : 44|5@1+ (1,0) [0|31] "" XXX
 SG_ ccIC_HU_DR_Direction : 49|1@1+ (1,0) [0|1] "" XXX
 SG_ ccIC_HU_DR_GyroCalib_Sta : 50|1@1+ (1,0) [0|1] "" XXX
 SG_ ccIC_HU_DR_TachoCalib_Sta : 51|4@1+ (1,0) [0|15] "" XXX
 SG_ ccIC_HU_DR_Solution_Sta : 55|1@1+ (1,0) [0|1] "" XXX
 SG_ ccIC_HU_DR_GNSS_Fix_Age : 56|64@1+ (1,0) [0|1.84467440737096e+19] "" XXX
 SG_ ccIC_HU_DR_Latitude : 64|32@1+ (1,0) [0|4294967295] "" XXX
 SG_ ccIC_HU_DR_Longitude : 96|8@1+ (1,0) [0|255] "" XXX
 SG_ ccIC_HU_DR_Altitude : 128|8@1+ (1,0) [0|255] "" XXX
 SG_ ccIC_HU_DR_Heading : 144|16@1+ (1,0) [0|65535] "" XXX
 SG_ ccIC_HU_DR_Speed : 160|8@1+ (1,0) [0|255] "" XXX
 SG_ ccIC_HU_DR_Position_Accuracy : 176|16@1+ (1,0) [0|65535] "" XXX
 SG_ ccIC_HU_DR_Altitude_Accuracy : 192|16@1+ (1,0) [0|65535] "" XXX
 SG_ ccIC_HU_DR_Heading_Accuracy : 208|16@1+ (1,0) [0|65535] "" XXX
 SG_ ccIC_HU_DR_Speed_Accuracy : 224|8@1+ (1,0) [0|255] "" XXX

BO_ 629 ICU_10_200ms_ICU: 8 XXX
 SG_ TCU_Crc10Val : 0|16@1+ (1,0) [0|65535] "" XXX
 SG_ TCU_AlvCnt10Val : 16|8@1+ (1,0) [0|255] "" XXX

BO_ 640 HU_FPM_E: 8 XXX
 SG_ AVN_Random : 16|8@1+ (1,0) [0|255] "" XXX

BO_ 641 HU_FPM_E: 8 XXX
 SG_ AVN_Encrypted_Result1 : 0|8@1+ (1,0) [0|255] "" XXX

BO_ 642 HU_FPM_E: 8 XXX
 SG_ AVN_Encrypted_Result2 : 0|8@1+ (1,0) [0|255] "" XXX

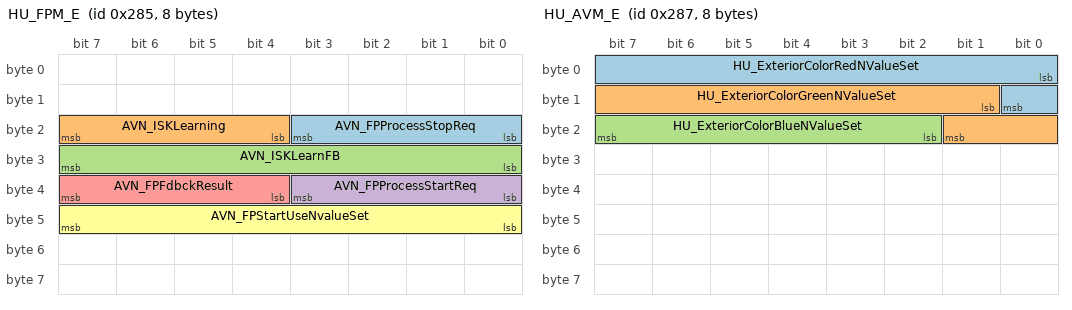
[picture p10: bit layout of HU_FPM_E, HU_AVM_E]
BO_ 645 HU_FPM_E: 8 XXX
 SG_ AVN_FPProcessStopReq : 16|4@1+ (1,0) [0|15] "" XXX
 SG_ AVN_ISKLearning : 20|4@1+ (1,0) [0|15] "" XXX
 SG_ AVN_ISKLearnFB : 24|8@1+ (1,0) [0|255] "" XXX
 SG_ AVN_FPProcessStartReq : 32|4@1+ (1,0) [0|15] "" XXX
 SG_ AVN_FPFdbckResult : 36|4@1+ (1,0) [0|15] "" XXX
 SG_ AVN_FPStartUseNvalueSet : 40|8@1+ (1,0) [0|255] "" XXX

BO_ 646 HU_FPM_PE: 8 XXX
 SG_ AVN_ReadyToSendData : 0|2@1+ (1,0) [0|3] "" XXX
 SG_ AVN_ISKLearnState : 2|6@1+ (1,0) [0|63] "" XXX

BO_ 647 HU_AVM_E: 8 XXX
 SG_ HU_ExteriorColorRedNValueSet : 0|9@1+ (1,0) [0|511] "" XXX
 SG_ HU_ExteriorColorGreenNValueSet : 9|9@1+ (1,0) [0|511] "" XXX
 SG_ HU_ExteriorColorBlueNValueSet : 18|6@1+ (1,0) [0|63] "" XXX

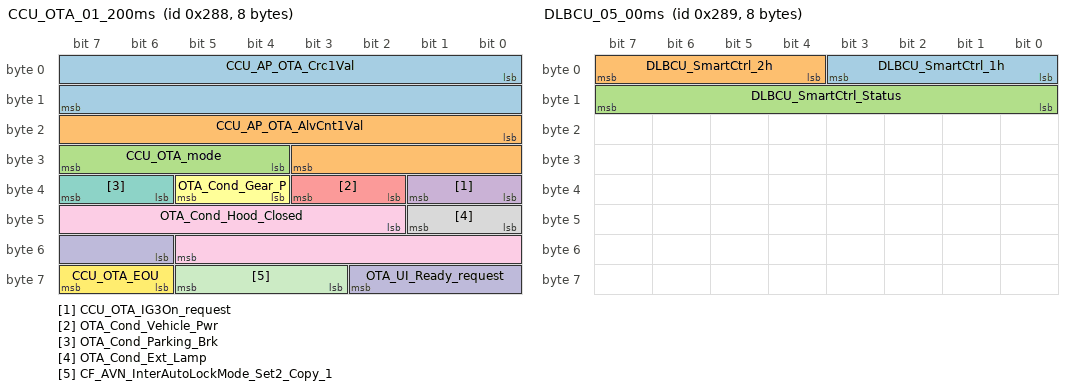
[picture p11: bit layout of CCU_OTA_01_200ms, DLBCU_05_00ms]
BO_ 648 CCU_OTA_01_200ms: 8 XXX
 SG_ CCU_AP_OTA_Crc1Val : 0|16@1+ (1,0) [0|65535] "" XXX
 SG_ CCU_AP_OTA_AlvCnt1Val : 16|12@1+ (1,0) [0|4095] "" XXX
 SG_ CCU_OTA_mode : 28|4@1+ (1,0) [0|15] "" XXX
 SG_ CCU_OTA_IG3On_request : 32|2@1+ (1,0) [0|3] "" XXX
 SG_ OTA_Cond_Vehicle_Pwr : 34|2@1+ (1,0) [0|3] "" XXX
 SG_ OTA_Cond_Gear_P : 36|2@1+ (1,0) [0|3] "" XXX
 SG_ OTA_Cond_Parking_Brk : 38|2@1+ (1,0) [0|3] "" XXX
 SG_ OTA_Cond_Ext_Lamp : 40|2@1+ (1,0) [0|3] "" XXX
 SG_ OTA_Cond_Hood_Closed : 42|12@1+ (1,0) [0|4095] "" XXX
 SG_ OTA_UI_Ready_request : 54|5@1+ (1,0) [0|31] "" XXX
 SG_ CF_AVN_InterAutoLockMode_Set2_Copy_1 : 59|3@1+ (1,0) [0|7] "" XXX
 SG_ CCU_OTA_EOU : 62|2@1+ (1,0) [0|3] "" XXX

BO_ 649 DLBCU_05_00ms: 8 XXX
 SG_ DLBCU_SmartCtrl_1h : 0|4@1+ (1,0) [0|15] "" XXX
 SG_ DLBCU_SmartCtrl_2h : 4|4@1+ (1,0) [0|15] "" XXX
 SG_ DLBCU_SmartCtrl_Status : 8|8@1+ (1,0) [0|255] "" XXX

BO_ 654 ADAS_PRK_CAM_02_600ms: 8 XXX
 SG_ ADAS_PRK_CAM_Crc2Val : 0|16@1+ (1,0) [0|65535] "" XXX
 SG_ ADAS_PRK_CAM_AlvCnt2Val : 16|8@1+ (1,0) [0|255] "" XXX
 SG_ SVM_CamIntID1 : 24|8@1+ (1,0) [0|255] "" XXX
 SG_ SVM_CamIntFx : 32|32@1+ (1,0) [0|4294967295] "" XXX
 SG_ SVM_CamIntFy : 64|32@1+ (1,0) [0|4294967295] "" XXX
 SG_ SVM_CamIntCx : 96|32@1+ (1,0) [0|4294967295] "" XXX
 SG_ SVM_CamIntCy : 128|32@1+ (1,0) [0|4294967295] "" XXX
 SG_ SVM_FrCamVFEventSta : 160|8@1+ (1,0) [0|255] "" XXX
 SG_ SVM_RrCamVFEventSta : 168|8@1+ (1,0) [0|255] "" XXX
 SG_ SVM_LtCamVFEventSta : 176|8@1+ (1,0) [0|255] "" XXX
 SG_ SVM_RtCamVFEventSta : 184|8@1+ (1,0) [0|255] "" XXX

BO_ 666 HU_GW_PE_02_ccIC: 8 XXX
 SG_ HU_DistanceUnit : 0|2@1+ (1,0) [0|3] "" XXX
 SG_ HU_Scheduled_Setting : 2|4@1+ (1,0) [0|15] "" XXX
 SG_ HU_AliveStatus : 6|4@1+ (1,0) [0|15] "" XXX
 SG_ HU_ThemeType : 10|7@1+ (1,0) [0|127] "" XXX
 SG_ HU_MicActivity : 17|3@1+ (1,0) [0|7] "" XXX
 SG_ AVN_RSPA_ModeSelect : 20|4@1+ (1,0) [0|15] "" XXX
 SG_ CF_HU_GPSFlt : 24|2@1+ (1,0) [0|3] "" XXX
 SG_ AVN_RSPA_CancelInput : 26|12@1+ (1,0) [0|4095] "" XXX
 SG_ HUD_PbackSta : 29|3@1+ (1,0) [0|7] "" XXX
 SG_ AVN_RSPA_Disp_Rdy : 38|2@1+ (1,0) [0|3] "" XXX
 SG_ CF_AVN_ProfileIDRValue : 40|4@1+ (1,0) [0|15] "" XXX
 SG_ HazardFromHUSVM : 44|2@1+ (1,0) [0|3] "" XXX
 SG_ OMUOSMirCtrl : 46|10@1+ (1,0) [0|1023] "" XXX
 SG_ OTAUIStatus : 56|2@1+ (1,0) [0|3] "" XXX
 SG_ C_TeleActiveStatus : 58|4@1+ (1,0) [0|15] "" XXX
 SG_ HU_RTCCheck : 62|2@1+ (1,0) [0|3] "" XXX

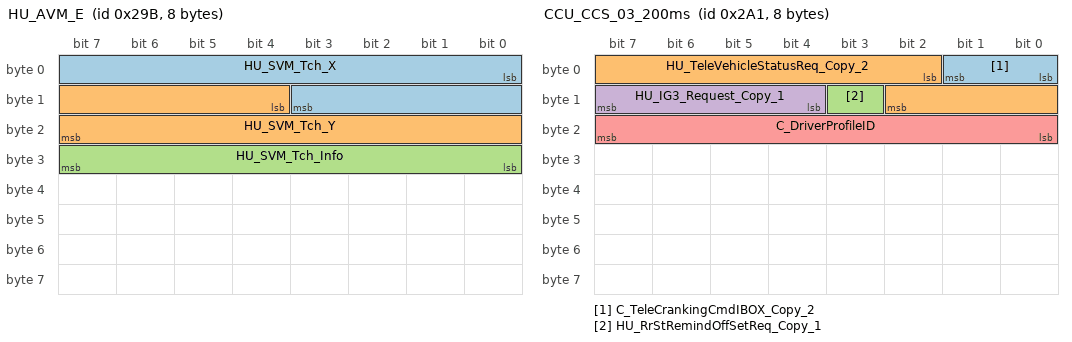
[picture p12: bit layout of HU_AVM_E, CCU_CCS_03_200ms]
BO_ 667 HU_AVM_E: 8 XXX
 SG_ HU_SVM_Tch_X : 0|12@1+ (1,0) [0|4095] "" XXX
 SG_ HU_SVM_Tch_Y : 12|12@1+ (1,0) [0|4095] "" XXX
 SG_ HU_SVM_Tch_Info : 24|8@1+ (1,0) [0|255] "" XXX

BO_ 670 ADAS_PRK_CAM_03_600ms: 8 XXX
 SG_ ADAS_PRK_CAM_Crc3Val : 0|16@1+ (1,0) [0|65535] "" XXX
 SG_ ADAS_PRK_CAM_AlvCnt3Val : 16|8@1+ (1,0) [0|255] "" XXX
 SG_ SVM_CamIntID2 : 24|8@1+ (1,0) [0|255] "" XXX
 SG_ SVM_CamIntK1 : 32|32@1+ (1,0) [0|4294967295] "" XXX
 SG_ SVM_CamIntK2 : 64|32@1+ (1,0) [0|4294967295] "" XXX
 SG_ SVM_CamIntK3 : 96|32@1+ (1,0) [0|4294967295] "" XXX
 SG_ SVM_CamIntK4 : 128|8@1+ (1,0) [0|255] "" XXX

BO_ 672 CCU_CCS_01_00ms: 8 XXX
 SG_ C_CtrlDrLockRlyCCS_Copy_2 : 0|2@1+ (1,0) [0|3] "" XXX
 SG_ C_CtrlDrUnlockRlyCCS_Copy_2 : 2|2@1+ (1,0) [0|3] "" XXX
 SG_ C_HazardFromCCS_Copy_2 : 4|2@1+ (1,0) [0|3] "" XXX
 SG_ C_PanicFromCCS_Copy_2 : 6|2@1+ (1,0) [0|3] "" XXX
 SG_ C_PreCrankReq_Copy : 8|4@1+ (1,0) [0|15] "" XXX
 SG_ C_TeleStrgWhlHeatingCmdIBOX_Copy_2 : 12|2@1+ (1,0) [0|3] "" XXX
 SG_ C_TeleDefoggerHeatingCmdIBOX_Copy_2 : 14|2@1+ (1,0) [0|3] "" XXX
 SG_ C_TeleDrvSeatOpCmdIBOX_Copy_2 : 16|4@1+ (1,0) [0|15] "" XXX
 SG_ C_TeleAstSeatOpCmdIBOX_Copy_2 : 20|4@1+ (1,0) [0|15] "" XXX
 SG_ C_TeleRRSeatOpCmdIBOX_Copy_2 : 24|4@1+ (1,0) [0|15] "" XXX
 SG_ C_TeleRLSeatOpCmdIBOX_Copy_1 : 28|10@1+ (1,0) [0|1023] "" XXX
 SG_ C_DrvWindowCmdAVN_Copy_2 : 38|4@1+ (1,0) [0|15] "" XXX
 SG_ C_AstWindowCmdAVN_Copy_2 : 42|4@1+ (1,0) [0|15] "" XXX
 SG_ C_RRWindowCmdAVN_Copy_2 : 46|4@1+ (1,0) [0|15] "" XXX
 SG_ C_RLWindowCmdAVN_Copy_2 : 50|4@1+ (1,0) [0|15] "" XXX
 SG_ TailCtrlReq_Copy : 54|2@1+ (1,0) [0|3] "" XXX
 SG_ HazardCtrlReq_Copy : 56|6@1+ (1,0) [0|63] "" XXX
 SG_ RAC_AirCleaningCtrlReq_Copy_1 : 62|2@1+ (1,0) [0|3] "" XXX
 SG_ HU_CDMOpenCmd_Copy_1 : 64|8@1+ (1,0) [0|255] "" XXX
 SG_ C_EsyAcsProfileID_CCU : 72|8@1+ (1,0) [0|255] "" XXX

BO_ 673 CCU_CCS_03_200ms: 8 XXX
 SG_ C_TeleCrankingCmdIBOX_Copy_2 : 0|2@1+ (1,0) [0|3] "" XXX
 SG_ HU_TeleVehicleStatusReq_Copy_2 : 2|9@1+ (1,0) [0|511] "" XXX
 SG_ HU_RrStRemindOffSetReq_Copy_1 : 11|1@1+ (1,0) [0|1] "" XXX
 SG_ HU_IG3_Request_Copy_1 : 12|4@1+ (1,0) [0|15] "" XXX
 SG_ C_DriverProfileID : 16|8@1+ (1,0) [0|255] "" XXX

BO_ 674 CAM_0x2a2: 32 CAMERA
 SG_ CHECKSUM : 0|16@1+ (1,0) [0|65535] "" XXX
 SG_ COUNTER : 16|8@1+ (1,0) [0|255] "" XXX

BO_ 675 HU_USM_E4: 32 XXX
 SG_ CF_Clu_ECoastCtrlNValueSet : 0|3@1+ (1,0) [0|7] "" XXX
 SG_ CF_Clu_ECoastingNValueSet : 3|2@1+ (1,0) [0|3] "" XXX
 SG_ VESS_VolLevel_NValueSet : 5|4@1+ (1,0) [0|15] "" XXX
 SG_ CF_AVN_PCA_RrEquipNvalueSet : 9|1@1+ (1,0) [0|1] "" XXX
 SG_ CF_Clu_ActivePddlNValueSet : 10|1@1+ (1,0) [0|1] "" XXX
 SG_ CF_AVN_HtBlcRLNValueSet : 11|1@1+ (1,0) [0|1] "" XXX
 SG_ CF_Clu_AuxBatChageNVauleSet : 12|2@1+ (1,0) [0|3] "" XXX
 SG_ CF_Clu_ECoastWarnNValueSet : 14|1@1+ (1,0) [0|1] "" XXX
 SG_ CF_AVN_BRAKE_PedalfeelNValueSet2 : 15|1@1+ (1,0) [0|1] "" XXX
 SG_ C_MoodLpBrightOnlyNValue : 16|3@1+ (1,0) [0|7] "" XXX
 SG_ CF_AVN_GreenZoneDrv_Status : 19|1@1+ (1,0) [0|1] "" XXX
 SG_ CF_AVN_HtBlcRRNValueSet : 20|1@1+ (1,0) [0|1] "" XXX
 SG_ CF_AVN_InterAutoLockMode_Set2 : 21|9@1+ (1,0) [0|511] "" XXX
 SG_ HCS_SOSNValueSet : 30|2@1+ (1,0) [0|3] "" XXX
 SG_ USM_TowWeight_Set : 32|2@1+ (1,0) [0|3] "" XXX
 SG_ CF_AVN_ChainSet : 34|2@1+ (1,0) [0|3] "" XXX
 SG_ USM_AVN_EngOilChaResetReq : 36|6@1+ (1,0) [0|63] "" XXX
 SG_ CF_AVN_RestModeNValueSet : 42|2@1+ (1,0) [0|3] "" XXX
 SG_ CF_AVN_NmodeFCAoff_NValueSet_NEW : 44|2@1+ (1,0) [0|3] "" XXX
 SG_ CF_AVN_BRAKE_PedalfeelNValueSet : 46|2@1+ (1,0) [0|3] "" XXX

BO_ 676 HU_APSU_E: 24 XXX
 SG_ C_DrAirSptNValueSet_EC : 0|2@1+ (1,0) [0|3] "" XXX
 SG_ C_DrAirSptModeNValueSet_EC : 2|3@1+ (1,0) [0|7] "" XXX
 SG_ C_DrAirSptStrNValueSet_EC : 5|3@1+ (1,0) [0|7] "" XXX
 SG_ C_DrAirSptTimeNValueSet_EC : 8|3@1+ (1,0) [0|7] "" XXX
 SG_ C_DrCushSoftNValueSet_EC : 11|3@1+ (1,0) [0|7] "" XXX
 SG_ C_AstAirSptNValueSet_EC : 14|2@1+ (1,0) [0|3] "" XXX
 SG_ C_DrBackSoftNValueSet_EC : 16|3@1+ (1,0) [0|7] "" XXX
 SG_ C_AstAirSptModeNValueSet_EC : 19|3@1+ (1,0) [0|7] "" XXX
 SG_ C_RLAirSptNValueSet_EC : 22|2@1+ (1,0) [0|3] "" XXX
 SG_ C_AstAirSptStrNValueSet_EC : 24|3@1+ (1,0) [0|7] "" XXX
 SG_ C_AstAirSptTimeNValueSet_EC : 27|3@1+ (1,0) [0|7] "" XXX
 SG_ C_RRAirSptNValueSet_EC : 30|2@1+ (1,0) [0|3] "" XXX
 SG_ C_AstCushSoftNValueSet_EC : 32|3@1+ (1,0) [0|7] "" XXX
 SG_ C_AstBackSoftNValueSet_EC : 35|3@1+ (1,0) [0|7] "" XXX
 SG_ C_RRFootAirSptNValueSet_EC_RRBackSoftNValueSet : 38|2@1+ (1,0) [0|3] "" XXX
 SG_ C_AstRlxNValueSet_EC : 40|3@1+ (1,0) [0|7] "" XXX
 SG_ C_RLAirSptModeNValueSet_EC : 43|5@1+ (1,0) [0|31] "" XXX
 SG_ C_RLSeatHtOperNValueSet_EC_RRBackSoftNValueSet : 48|4@1+ (1,0) [0|15] "" XXX
 SG_ C_RRSeatHtOperNValueSet_EC_RRBackSoftNValueSet : 52|4@1+ (1,0) [0|15] "" XXX
 SG_ C_RLAirSptStrNValueSet_EC : 56|2@1+ (1,0) [0|3] "" XXX
 SG_ SET_ME_0 : 58|1@1+ (1,0) [0|1] "" XXX
 SG_ C_RLAirSptTimeNValueSet_EC : 59|1@1+ (1,0) [0|1] "" XXX
 SG_ RIGHT_LANE_LINE : 60|2@1+ (1,0) [0|3] "" XXX
 SG_ SET_ME_0_2 : 62|2@1+ (1,0) [0|3] "" XXX
 SG_ BYTE8 : 64|8@1+ (1,0) [0|255] "" XXX
 SG_ BYTE9 : 72|8@1+ (1,0) [0|255] "" XXX
 SG_ BYTE10 : 80|8@1+ (1,0) [0|255] "" XXX
 SG_ BYTE11 : 88|8@1+ (1,0) [0|255] "" XXX
 SG_ BYTE12 : 96|8@1+ (1,0) [0|255] "" XXX
 SG_ BYTE13 : 104|8@1+ (1,0) [0|255] "" XXX
 SG_ BYTE14 : 112|8@1+ (1,0) [0|255] "" XXX
 SG_ BYTE15 : 120|8@1+ (1,0) [0|255] "" XXX
 SG_ BYTE16 : 128|8@1+ (1,0) [0|255] "" XXX
 SG_ BYTE17 : 136|8@1+ (1,0) [0|255] "" XXX
 SG_ BYTE18 : 144|8@1+ (1,0) [0|255] "" XXX
 SG_ BYTE19 : 152|8@1+ (1,0) [0|255] "" XXX
 SG_ BYTE20 : 160|8@1+ (1,0) [0|255] "" XXX
 SG_ BYTE21 : 168|8@1+ (1,0) [0|255] "" XXX
 SG_ BYTE22 : 176|8@1+ (1,0) [0|255] "" XXX
 SG_ BYTE23 : 184|8@1+ (1,0) [0|255] "" XXX

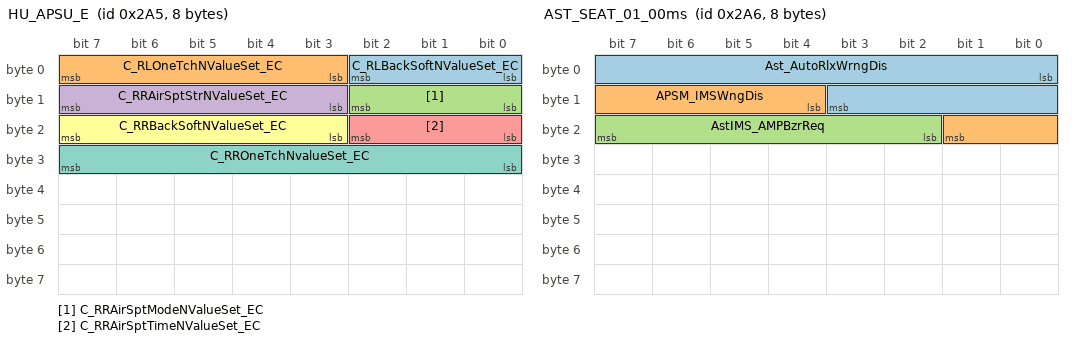
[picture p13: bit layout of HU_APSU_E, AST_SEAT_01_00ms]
BO_ 677 HU_APSU_E: 8 XXX
 SG_ C_RLBackSoftNValueSet_EC : 0|3@1+ (1,0) [0|7] "" XXX
 SG_ C_RLOneTchNValueSet_EC : 3|5@1+ (1,0) [0|31] "" XXX
 SG_ C_RRAirSptModeNValueSet_EC : 8|3@1+ (1,0) [0|7] "" XXX
 SG_ C_RRAirSptStrNValueSet_EC : 11|5@1+ (1,0) [0|31] "" XXX
 SG_ C_RRAirSptTimeNValueSet_EC : 16|3@1+ (1,0) [0|7] "" XXX
 SG_ C_RRBackSoftNValueSet_EC : 19|5@1+ (1,0) [0|31] "" XXX
 SG_ C_RROneTchNvalueSet_EC : 24|8@1+ (1,0) [0|255] "" XXX

BO_ 678 AST_SEAT_01_00ms: 8 XXX
 SG_ Ast_AutoRlxWrngDis : 0|12@1+ (1,0) [0|4095] "" XXX
 SG_ APSM_IMSWngDis : 12|6@1+ (1,0) [0|63] "" XXX
 SG_ AstIMS_AMPBzrReq : 18|6@1+ (1,0) [0|63] "" XXX

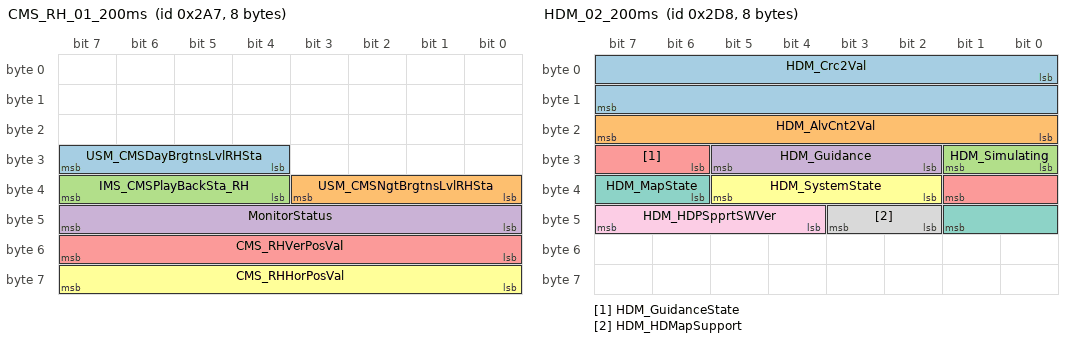
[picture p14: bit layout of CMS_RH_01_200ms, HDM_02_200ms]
BO_ 679 CMS_RH_01_200ms: 8 XXX
 SG_ USM_CMSDayBrgtnsLvlRHSta : 28|4@1+ (1,0) [0|15] "" XXX
 SG_ USM_CMSNgtBrgtnsLvlRHSta : 32|4@1+ (1,0) [0|15] "" XXX
 SG_ IMS_CMSPlayBackSta_RH : 36|4@1+ (1,0) [0|15] "" XXX
 SG_ MonitorStatus : 40|8@1+ (1,0) [0|255] "" XXX
 SG_ CMS_RHVerPosVal : 48|8@1+ (1,0) [0|255] "" XXX
 SG_ CMS_RHHorPosVal : 56|8@1+ (1,0) [0|255] "" XXX

BO_ 681 RLPSM_02_00ms: 8 XXX
 SG_ RLPSM_RearModeWngDis : 13|3@1+ (1,0) [0|7] "" XXX
 SG_ RLIMS_AMPBzrReq : 16|8@1+ (1,0) [0|255] "" XXX

BO_ 682 VCU_04_100ms: 8 XXX
 SG_ VCU_Crc4Val : 0|16@1+ (1,0) [0|65535] "" XXX
 SG_ VCU_AlvCnt4Val : 16|8@1+ (1,0) [0|255] "" XXX
 SG_ VCU_DepartSet1_HrVal : 24|5@1+ (1,0) [0|31] "" XXX
 SG_ VCU_DepartSet1_MinVal : 29|3@1+ (1,0) [0|7] "" XXX
 SG_ VCU_DepartSet2_HrVal : 32|5@1+ (1,0) [0|31] "" XXX
 SG_ VCU_DepartSet2_MinVal : 37|3@1+ (1,0) [0|7] "" XXX
 SG_ VCU_DepartSet1_Mon : 40|2@1+ (1,0) [0|3] "" XXX
 SG_ VCU_DepartSet1_Tue : 42|2@1+ (1,0) [0|3] "" XXX
 SG_ VCU_DepartSet1_Wed : 44|2@1+ (1,0) [0|3] "" XXX
 SG_ VCU_DepartSet1_Thu : 46|2@1+ (1,0) [0|3] "" XXX
 SG_ VCU_DepartSet1_EnSta : 48|2@1+ (1,0) [0|3] "" XXX
 SG_ VCU_DepartSet1_Fri : 50|2@1+ (1,0) [0|3] "" XXX
 SG_ VCU_DepartSet1_Sat : 52|2@1+ (1,0) [0|3] "" XXX
 SG_ VCU_DepartSet1_Sun : 54|2@1+ (1,0) [0|3] "" XXX
 SG_ VCU_DepartSet2_Mon : 56|2@1+ (1,0) [0|3] "" XXX
 SG_ VCU_DepartSet2_Tue : 58|2@1+ (1,0) [0|3] "" XXX
 SG_ VCU_DepartSet2_Wed : 60|2@1+ (1,0) [0|3] "" XXX
 SG_ VCU_DepartSet2_Thu : 62|2@1+ (1,0) [0|3] "" XXX
 SG_ VCU_DepartSet2_EnSta : 64|2@1+ (1,0) [0|3] "" XXX
 SG_ VCU_DepartSet2_Fri : 66|2@1+ (1,0) [0|3] "" XXX
 SG_ VCU_DepartSet2_Sat : 68|2@1+ (1,0) [0|3] "" XXX
 SG_ VCU_DepartSet2_Sun : 70|2@1+ (1,0) [0|3] "" XXX
 SG_ VCU_OffPeakTimeStHrVal : 72|5@1+ (1,0) [0|31] "" XXX
 SG_ VCU_OffPeakTimeStMinVal : 77|3@1+ (1,0) [0|7] "" XXX
 SG_ VCU_OffPeakTimeEndHrVal : 80|5@1+ (1,0) [0|31] "" XXX
 SG_ VCU_OffPeakTimeEndMinVal : 85|3@1+ (1,0) [0|7] "" XXX
 SG_ VCU_BattCondActStaDisp : 88|6@1+ (1,0) [0|63] "" XXX
 SG_ VCU_FatcTempSetUnit : 94|2@1+ (1,0) [0|3] "" XXX
 SG_ VCU_FatcTempSetVal : 96|8@1+ (1,0) [0|255] "" XXX
 SG_ VCU_SchedChgSet_OpModeSta : 104|2@1+ (1,0) [0|3] "" XXX
 SG_ VCU_SchedChg_EnIndSta : 106|2@1+ (1,0) [0|3] "" XXX
 SG_ VCU_SchedChg_WaitIndSta : 108|2@1+ (1,0) [0|3] "" XXX
 SG_ VCU_AcChgInhSta : 110|2@1+ (1,0) [0|3] "" XXX
 SG_ VCU_ChgCancelReq : 112|2@1+ (1,0) [0|3] "" XXX
 SG_ VCU_SchedRmtFcn_MainRlyOnReq : 114|2@1+ (1,0) [0|3] "" XXX
 SG_ VCU_SchedRmtFcn_OpSta : 116|4@1+ (1,0) [0|15] "" XXX
 SG_ VCU_SchedClimateSet_EnSta : 120|2@1+ (1,0) [0|3] "" XXX
 SG_ VCU_SchedClimateSet_TempVal : 122|6@1+ (1,0) [0|63] "" XXX
 SG_ VCU_SchedClimateSet_DefrostEnSta : 128|2@1+ (1,0) [0|3] "" XXX
 SG_ VCU_AirconCtrReq : 130|2@1+ (1,0) [0|3] "" XXX
 SG_ VCU_SchedRmtClimate_OpSta : 132|2@1+ (1,0) [0|3] "" XXX
 SG_ VCU_FatcDefrostCtrReq : 134|2@1+ (1,0) [0|3] "" XXX
 SG_ VCU_AuxBattChgVehCondi : 136|4@1+ (1,0) [0|15] "" XXX
 SG_ VCU_BattCondIndSta : 140|2@1+ (1,0) [0|3] "" XXX
 SG_ VCU_SchedClimate_EnIndSta : 142|2@1+ (1,0) [0|3] "" XXX
 SG_ VCU_GpsSched_OpSta : 144|2@1+ (1,0) [0|3] "" XXX
 SG_ VCU_GpsSched_ChgClimateEnSta : 146|2@1+ (1,0) [0|3] "" XXX
 SG_ VCU_GpsSched_UpdateReq : 148|2@1+ (1,0) [0|3] "" XXX
 SG_ VCU_ChgCycSta : 150|2@1+ (1,0) [0|3] "" XXX
 SG_ VCU_AvnWakeupReq : 152|2@1+ (1,0) [0|3] "" XXX
 SG_ VCU_SchedRmtFcn_FailCfmSta : 154|2@1+ (1,0) [0|3] "" XXX
 SG_ VCU_AirconFinishAlmSta : 156|2@1+ (1,0) [0|3] "" XXX
 SG_ VCU_SchedClimateSet_TempUnitTyp : 158|2@1+ (1,0) [0|3] "" XXX
 SG_ VCU_SchedChg_StDayDispSta : 160|3@1+ (1,0) [0|7] "" XXX
 SG_ VCU_SchedChg_StHrDispVal : 163|5@1+ (1,0) [0|31] "" XXX
 SG_ VCU_SchedChg_StMinDispVal : 168|6@1+ (1,0) [0|63] "" XXX
 SG_ VCU_SchedChg_EndDayDispSta : 174|3@1+ (1,0) [0|7] "" XXX
 SG_ VCU_SchedChg_EndHrDispVal : 177|5@1+ (1,0) [0|31] "" XXX
 SG_ VCU_SchedChg_EndMinDispVal : 182|6@1+ (1,0) [0|63] "" XXX
 SG_ VCU_AuxBattSavUsmSta : 188|2@1+ (1,0) [0|3] "" XXX
 SG_ VCU_AuxBattSavWakeupSta : 190|2@1+ (1,0) [0|3] "" XXX
 SG_ VCU_RsChgSeqSta : 192|8@1+ (1,0) [0|255] "" XXX
 SG_ VCU_RsAirconSeqSta : 200|4@1+ (1,0) [0|15] "" XXX
 SG_ VCU_ChargeInfo : 204|4@1+ (1,0) [0|15] "" XXX
 SG_ VCU_RsRtcSchedDayVal : 208|3@1+ (1,0) [0|7] "" XXX
 SG_ VCU_RsRtcSchedHrVal : 211|5@1+ (1,0) [0|31] "" XXX
 SG_ VCU_RsRtcSchedMinVal : 216|6@1+ (1,0) [0|63] "" XXX
 SG_ VCU_Ig3DrvSta : 222|2@1+ (1,0) [0|3] "" XXX
 SG_ VCU_UtilModeUsmSta : 224|2@1+ (1,0) [0|3] "" XXX
 SG_ VCU_UtilModeActSta : 226|2@1+ (1,0) [0|3] "" XXX
 SG_ VCU_UtilModeWarnMsgSta : 228|2@1+ (1,0) [0|3] "" XXX
 SG_ VCU_Ig3OnlySta : 230|2@1+ (1,0) [0|3] "" XXX

BO_ 688 DATC_17_200ms: 8 XXX
 SG_ DATC_Crc17Val : 0|16@1+ (1,0) [0|65535] "" XXX
 SG_ DATC_AlvCnt17Val : 16|8@1+ (1,0) [0|255] "" XXX
 SG_ DATC_FrontPwmIsVolt : 24|8@1+ (1,0) [0|255] "" XXX
 SG_ DATC_FrontBlwDuty : 32|8@1+ (1,0) [0|255] "" XXX
 SG_ DATC_FrontBlwDiagStat : 40|4@1+ (1,0) [0|15] "" XXX
 SG_ DATC_BlwrLvl_Ps : 44|4@1+ (1,0) [0|15] "" XXX
 SG_ DATC_BlwrLvl_Rr : 48|7@1+ (1,0) [0|127] "" XXX
 SG_ DATC_FnDstSnsrVal : 55|9@1+ (1,0) [0|511] "" XXX
 SG_ DATC_FnDstStp : 64|4@1+ (1,0) [0|15] "" XXX
 SG_ DATC_HDPDfg_Sta : 68|2@1+ (1,0) [0|3] "" XXX
 SG_ DATC_HDPHumidity_Sta : 70|2@1+ (1,0) [0|3] "" XXX
 SG_ DATC_FnDstStp_Detail : 72|32@1+ (1,0) [0|4294967295] "" XXX
 SG_ DATC_HDPSpprtSWVer : 104|8@1+ (1,0) [0|255] "" XXX

BO_ 689 ADAS_CMD_34_100ms: 8 XXX
 SG_ ADAS_CMD_Crc34Val : 0|16@1+ (1,0) [0|65535] "" XXX
 SG_ ADAS_CMD_AlvCnt34Val : 16|8@1+ (1,0) [0|255] "" XXX
 SG_ HDP_RDD_WarnSta : 24|3@1+ (1,0) [0|7] "" XXX
 SG_ HDP_RDD_LongAsstCtrlSta : 27|2@1+ (1,0) [0|3] "" XXX
 SG_ HDP_RDD_HzrdLmpReqSta : 29|3@1+ (1,0) [0|7] "" XXX
 SG_ HDP_RDD_ACIActvDispSta : 32|40@1+ (1,0) [0|1099511627775] "" XXX
 SG_ HDP_RDD_EMStbltActvReqSta : 72|8@1+ (1,0) [0|255] "" XXX

BO_ 693 VCU_05_100ms: 8 XXX
 SG_ VCU_Crc5Val : 0|16@1+ (1,0) [0|65535] "" XXX
 SG_ VCU_AlvCnt5Val : 16|8@1+ (1,0) [0|255] "" XXX
 SG_ VCU_EvDrvRdyCluDispSta : 24|2@1+ (1,0) [0|3] "" XXX
 SG_ VCU_PwrDnModeSta : 26|2@1+ (1,0) [0|3] "" XXX
 SG_ VCU_CluWarnMsgSta : 28|4@1+ (1,0) [0|15] "" XXX
 SG_ VCU_DteOffDispSta : 32|2@1+ (1,0) [0|3] "" XXX
 SG_ VCU_LowSocAlertSta : 34|4@1+ (1,0) [0|15] "" XXX
 SG_ VCU_VcrmReq : 38|2@1+ (1,0) [0|3] "" XXX
 SG_ VCU_PdlWarnMsgSta : 40|2@1+ (1,0) [0|3] "" XXX
 SG_ VCU_AwdDiagDispSta : 42|2@1+ (1,0) [0|3] "" XXX
 SG_ VCU_AwdLockDispSta : 44|2@1+ (1,0) [0|3] "" XXX
 SG_ VCU_VirtualApsActSta : 46|2@1+ (1,0) [0|3] "" XXX
 SG_ VCU_VirtualApsVal : 48|8@1+ (1,0) [0|255] "" XXX
 SG_ VCU_ServiceLampReq : 56|2@1+ (1,0) [0|3] "" XXX
 SG_ VCU_ServiceModeSta : 58|2@1+ (1,0) [0|3] "" XXX
 SG_ VCU_NPosWshModSta : 60|2@1+ (1,0) [0|3] "" XXX
 SG_ VCU_PowerTrainType : 62|2@1+ (1,0) [0|3] "" XXX
 SG_ VCU_DteBaseVal : 64|11@1+ (1,0) [0|2047] "" XXX
 SG_ VCU_AvnDteOnCalcSta : 75|2@1+ (1,0) [0|3] "" XXX
 SG_ VCU_SbwWarnMsgSta : 77|3@1+ (1,0) [0|7] "" XXX
 SG_ VCU_DteNaviRouteVal : 80|10@1+ (1,0) [0|1023] "" XXX
 SG_ VCU_DteAddVal : 90|8@1+ (1,0) [0|255] "" XXX
 SG_ VCU_PwrGaugeVal : 98|8@1+ (1,0) [0|255] "" XXX
 SG_ VCU_EnergyFlowSta : 106|4@1+ (1,0) [0|15] "" XXX
 SG_ VCU_SbwWarnSndSta : 110|2@1+ (1,0) [0|3] "" XXX
 SG_ VCU_EcoGuide_DispReq : 112|2@1+ (1,0) [0|3] "" XXX
 SG_ VCU_EcoGuide_ApsGaugeVal : 114|7@1+ (1,0) [0|127] "" XXX
 SG_ VCU_EcoGuide_EcoGaugeVal : 121|7@1+ (1,0) [0|127] "" XXX
 SG_ VCU_TgSocDteAcChgVal : 128|11@1+ (1,0) [0|2047] "" XXX
 SG_ VCU_TgSocDteDcChgVal : 139|13@1+ (1,0) [0|8191] "" XXX
 SG_ VCU_DistFromRegenDispReq : 152|2@1+ (1,0) [0|3] "" XXX
 SG_ VCU_DistFromRegenVal : 154|10@1+ (1,0) [0|1023] "" XXX
 SG_ VCU_DrvStyle_DispReq : 164|2@1+ (1,0) [0|3] "" XXX
 SG_ VCU_DrvStyle_HighLightSta : 166|2@1+ (1,0) [0|3] "" XXX
 SG_ VCU_DrvStyle_EcoVal : 168|8@1+ (1,0) [0|255] "" XXX
 SG_ VCU_DrvStyle_NonEcoVal : 176|8@1+ (1,0) [0|255] "" XXX
 SG_ VCU_DrvStyle_NorVal : 184|8@1+ (1,0) [0|255] "" XXX
 SG_ VCU_LowSocDispPcVal : 192|13@1+ (1,0) [0|8191] "" XXX
 SG_ VCU_DteSocBasedVal : 205|11@1+ (1,0) [0|2047] "" XXX
 SG_ VCU_InstFuelEcoVal_Per100km : 216|8@1+ (1,0) [0|255] "" XXX
 SG_ VCU_InstFuelEcoVal_PerkWh : 224|8@1+ (1,0) [0|255] "" XXX
 SG_ VCU_CO2RdcTripDistVal : 232|10@1+ (1,0) [0|1023] "" XXX
 SG_ VCU_CO2RdcVal : 242|6@1+ (1,0) [0|63] "" XXX

BO_ 699 CAM_0x2bb: 32 CAMERA
 SG_ CHECKSUM : 0|16@1+ (1,0) [0|65535] "" XXX
 SG_ COUNTER : 16|8@1+ (1,0) [0|255] "" XXX

BO_ 700 CAM_0x2bc: 32 CAMERA
 SG_ CHECKSUM : 0|16@1+ (1,0) [0|65535] "" XXX
 SG_ COUNTER : 16|8@1+ (1,0) [0|255] "" XXX

BO_ 701 CAM_0x2bd: 32 CAMERA
 SG_ CHECKSUM : 0|16@1+ (1,0) [0|65535] "" XXX
 SG_ COUNTER : 16|8@1+ (1,0) [0|255] "" XXX

BO_ 702 CAM_0x2be: 32 CAMERA
 SG_ CHECKSUM : 0|16@1+ (1,0) [0|65535] "" XXX
 SG_ COUNTER : 16|8@1+ (1,0) [0|255] "" XXX

BO_ 704 VCU_06_200ms: 8 XXX
 SG_ VCU_Crc6Val : 0|16@1+ (1,0) [0|65535] "" XXX
 SG_ VCU_AlvCnt6Val : 16|8@1+ (1,0) [0|255] "" XXX
 SG_ VCU_Required_ADASMapMsg : 24|16@1+ (1,0) [0|65535] "" XXX
 SG_ ENG_PwrAutoOffTimerReset : 29|10@1+ (1,0) [0|1023] "" XXX
 SG_ ENG_AutoShutOffTimerMin : 31|1@1+ (1,0) [0|1] "" XXX
 SG_ ENG_AutoShutOffTimerSec : 39|1@1+ (1,0) [0|1] "" XXX
 SG_ VCU_SwVer : 40|8@1+ (1,0) [0|255] "" XXX
 SG_ VCU_PwrAutoOffInfo : 48|2@1+ (1,0) [0|3] "" XXX
 SG_ VCU_PwrAutoOffTimerSta : 50|6@1+ (1,0) [0|63] "" XXX
 SG_ VCU_AutoShutOffTimerMin : 56|8@1+ (1,0) [0|255] "" XXX
 SG_ VCU_AutoShutOffTimerSec : 64|6@1+ (1,0) [0|63] "" XXX
 SG_ VCU_PwrAutoOffTimerReset : 70|2@1+ (1,0) [0|3] "" XXX
 SG_ VCU_AutoShutOffReq : 72|6@1+ (1,0) [0|63] "" XXX
 SG_ VCU_TireSizeWrnMsgSta : 78|2@1+ (1,0) [0|3] "" XXX
 SG_ VCU_FrntTqDispPcVal : 80|8@1+ (1,0) [0|255] "" XXX
 SG_ VCU_RearTqDispPcVal : 88|8@1+ (1,0) [0|255] "" XXX
 SG_ VCU_BstOpSta : 96|3@1+ (1,0) [0|7] "" XXX
 SG_ VCU_BstTimerVal : 99|6@1+ (1,0) [0|63] "" XXX
 SG_ VCU_BstWarnMsg : 105|2@1+ (1,0) [0|3] "" XXX
 SG_ VCU_BstAvailSta : 107|2@1+ (1,0) [0|3] "" XXX
 SG_ VCU_BstAplySta : 109|3@1+ (1,0) [0|7] "" XXX

BO_ 709 WCCU_01_100ms: 8 XXX
 SG_ WCCU_Crc1Val : 0|16@1+ (1,0) [0|65535] "" XXX
 SG_ WCCU_AlvCnt1Val : 16|32@1+ (1,0) [0|4294967295] "" XXX
 SG_ WCCU_Pairing : 48|8@1+ (1,0) [0|255] "" XXX
 SG_ WCCU_ChgFinished : 56|2@1+ (1,0) [0|3] "" XXX
 SG_ WCCU_PWMOnSta : 58|2@1+ (1,0) [0|3] "" XXX
 SG_ WCCU_FLT : 60|2@1+ (1,0) [0|3] "" XXX
 SG_ WCCU_ChgRdy : 62|2@1+ (1,0) [0|3] "" XXX
 SG_ WCCU_ChgRdyInfo : 64|4@1+ (1,0) [0|15] "" XXX
 SG_ WCCU_PD_Response : 68|2@1+ (1,0) [0|3] "" XXX
 SG_ WCCU_HvIntlockReq : 70|2@1+ (1,0) [0|3] "" XXX
 SG_ WCCU_VCRM_Req : 72|2@1+ (1,0) [0|3] "" XXX
 SG_ WCCU_ServiceLampReq : 74|2@1+ (1,0) [0|3] "" XXX
 SG_ WCCU_EWP_Rpm_Req : 76|8@1+ (1,0) [0|255] "" XXX
 SG_ WCCU_RadFanReq_Duty : 84|8@1+ (1,0) [0|255] "" XXX
 SG_ WCCU_SeqState : 92|4@1+ (1,0) [0|15] "" XXX
 SG_ WCCU_DiagInfoGrp : 96|4@1+ (1,0) [0|15] "" XXX
 SG_ WCCU_WPTChargingStat : 100|2@1+ (1,0) [0|3] "" XXX
 SG_ WCCU_WPT_ReadyforVCMS : 102|6@1+ (1,0) [0|63] "" XXX
 SG_ WCCU_Infocode : 108|20@1+ (1,0) [0|1048575] "" XXX
 SG_ WCCU_Rdy : 128|16@1+ (1,0) [0|65535] "" XXX
 SG_ WCCU_DCCurrVal : 144|16@1+ (1,0) [0|65535] "" XXX
 SG_ WCCU_DCVoltVal : 160|16@1+ (1,0) [0|65535] "" XXX
 SG_ WCCU_EstDCOutPwrValForVCMS : 176|16@1+ (1,0) [0|65535] "" XXX
 SG_ WCCU_AAFOpReq : 192|8@1+ (1,0) [0|255] "" XXX

BO_ 714 WCCU_02_200ms: 8 XXX
 SG_ WCCU_Crc2Val : 0|16@1+ (1,0) [0|65535] "" XXX
 SG_ WCCU_AlvCnt2Val : 16|8@1+ (1,0) [0|255] "" XXX
 SG_ WCCU_Paired_SSID : 24|32@1+ (1,0) [0|4294967295] "" XXX
 SG_ WCCU_GA_Type_1 : 56|2@1+ (1,0) [0|3] "" XXX
 SG_ WCCU_GA_Type_2 : 58|2@1+ (1,0) [0|3] "" XXX
 SG_ WCCU_GA_Type_3 : 60|2@1+ (1,0) [0|3] "" XXX
 SG_ WCCU_GA_Type_4 : 62|2@1+ (1,0) [0|3] "" XXX
 SG_ WCCU_GA_Type_5 : 64|2@1+ (1,0) [0|3] "" XXX
 SG_ WCCU_GA_Type_6 : 66|2@1+ (1,0) [0|3] "" XXX
 SG_ WCCU_GA_Type_7 : 68|2@1+ (1,0) [0|3] "" XXX
 SG_ WCCU_GA_Type_8 : 70|2@1+ (1,0) [0|3] "" XXX
 SG_ WCCU_GA_Type_9 : 72|2@1+ (1,0) [0|3] "" XXX
 SG_ WCCU_GA_Type_10 : 74|22@1+ (1,0) [0|4194303] "" XXX
 SG_ WCCU_TEMP_A : 96|8@1+ (1,0) [0|255] "" XXX
 SG_ WCCU_TEMP_B : 104|8@1+ (1,0) [0|255] "" XXX
 SG_ WCCU_TEMP_C : 112|8@1+ (1,0) [0|255] "" XXX
 SG_ WCCU_TEMP_D : 120|8@1+ (1,0) [0|255] "" XXX
 SG_ WCCU_GA_SSID_1 : 128|32@1+ (1,0) [0|4294967295] "" XXX
 SG_ WCCU_GA_SSID_2 : 160|32@1+ (1,0) [0|4294967295] "" XXX
 SG_ WCCU_GA_SSID_3 : 192|32@1+ (1,0) [0|4294967295] "" XXX
 SG_ WCCU_GA_SSID_4 : 224|8@1+ (1,0) [0|255] "" XXX

BO_ 720 CCM_05_200ms_4_CCM_ContCert: 8 XXX
 SG_ TCU_PS_Sta2 : 118|2@1+ (1,0) [0|3] "" XXX

BO_ 725 MCU_06_200ms: 8 XXX
 SG_ MCU_Crc6Val : 0|16@1+ (1,0) [0|65535] "" XXX
 SG_ MCU_AlvCnt6Val : 16|8@1+ (1,0) [0|255] "" XXX
 SG_ MCU_Mg2Grp1FltCodVal : 24|8@1+ (1,0) [0|255] "" XXX
 SG_ MCU_Mg2Grp2FltCodVal : 32|8@1+ (1,0) [0|255] "" XXX
 SG_ MCU_Mg2Grp3FltCodVal : 40|8@1+ (1,0) [0|255] "" XXX
 SG_ MCU_Mg2Grp4FltCodVal : 48|8@1+ (1,0) [0|255] "" XXX
 SG_ MCU_Mg2Grp5FltCodVal : 56|8@1+ (1,0) [0|255] "" XXX
 SG_ MCU_Mg2Grp6FltCodVal : 64|8@1+ (1,0) [0|255] "" XXX
 SG_ MCU_Mg2GrpUFltCodVal : 72|8@1+ (1,0) [0|255] "" XXX
 SG_ MCU_Mg2Aaf1OpReq : 80|3@1+ (1,0) [0|7] "" XXX
 SG_ MCU_Mg2Aaf1ActSta : 83|3@1+ (1,0) [0|7] "" XXX
 SG_ MCU_Mg2Aaf1FltSta : 86|2@1+ (1,0) [0|3] "" XXX
 SG_ MCU_Mg2Aaf2OpReq : 88|3@1+ (1,0) [0|7] "" XXX
 SG_ MCU_Mg2Aaf2ActSta : 91|3@1+ (1,0) [0|7] "" XXX
 SG_ MCU_Mg2Aaf2FltSta : 94|2@1+ (1,0) [0|3] "" XXX
 SG_ MCU_Mg2Aaf3OpReq : 96|3@1+ (1,0) [0|7] "" XXX
 SG_ MCU_Mg2Aaf3ActSta : 99|3@1+ (1,0) [0|7] "" XXX
 SG_ MCU_Mg2Aaf3FltSta : 102|8@1+ (1,0) [0|255] "" XXX
 SG_ MCU_Mg2AafWrnLampReq : 110|2@1+ (1,0) [0|3] "" XXX
 SG_ MCU_Mg2Eop1ProtectModeLIN : 112|2@1+ (1,0) [0|3] "" XXX
 SG_ MCU_Mg2Eop1FltStatusLIN : 114|2@1+ (1,0) [0|3] "" XXX
 SG_ MCU_Mg2Eop1MalFuncStatus : 116|2@1+ (1,0) [0|3] "" XXX
 SG_ MCU_Mg2Eop1ForcedOpStatus : 118|2@1+ (1,0) [0|3] "" XXX
 SG_ MCU_Mg2Eop1ActSpdRpmLIN : 120|8@1+ (1,0) [0|255] "" XXX
 SG_ MCU_Mg2Eop1SpdRpmReqLIN : 128|8@1+ (1,0) [0|255] "" XXX
 SG_ MCU_Mg2EwpClntDiagEnblStatus : 136|2@1+ (1,0) [0|3] "" XXX
 SG_ MCU_Mg2EwpClntSuffDisp : 138|2@1+ (1,0) [0|3] "" XXX
 SG_ MCU_Mg2Ewp1MalFuncStatus : 140|2@1+ (1,0) [0|3] "" XXX
 SG_ MCU_Mg2Ewp1ForcedOpStatus : 142|2@1+ (1,0) [0|3] "" XXX
 SG_ MCU_Mg2Ewp1ProtectModeLIN : 144|2@1+ (1,0) [0|3] "" XXX
 SG_ MCU_Mg2Ewp1FltStatusLIN : 146|6@1+ (1,0) [0|63] "" XXX
 SG_ MCU_Mg2Ewp1SpdRpmReqLIN : 152|8@1+ (1,0) [0|255] "" XXX
 SG_ MCU_Mg2Ewp1ActSpdRpmLIN : 160|8@1+ (1,0) [0|255] "" XXX
 SG_ MCU_Mg2PwrAvnKwVal : 168|10@1+ (1,0) [0|1023] "" XXX
 SG_ MCU_Mg2MotMaxPwrSpec : 178|6@1+ (1,0) [0|63] "" XXX
 SG_ MCU_Mg2OilTempVal : 184|8@1+ (1,0) [0|255] "" XXX

BO_ 726 ADAS_DRV_10_200ms: 8 XXX
 SG_ ADAS_DRV_Crc10Val : 0|16@1+ (1,0) [0|65535] "" XXX
 SG_ ADAS_DRV_AlvCnt10Val : 16|8@1+ (1,0) [0|255] "" XXX
 SG_ EVP_PosErrLongVal : 24|16@1+ (1,0) [0|65535] "" XXX
 SG_ EVP_PosErrLatVal : 40|16@1+ (1,0) [0|65535] "" XXX
 SG_ EVP_SysHDMapSta : 56|4@1+ (1,0) [0|15] "" XXX
 SG_ EVP_SysOpSta : 60|4@1+ (1,0) [0|15] "" XXX
 SG_ EVP_PosLongVal : 64|32@1+ (1,0) [0|4294967295] "" XXX
 SG_ EVP_PosLatVal : 96|32@1+ (1,0) [0|4294967295] "" XXX
 SG_ EVP_PosDirSta : 128|4@1+ (1,0) [0|15] "" XXX
 SG_ EVP_PosHeadingVal : 132|16@1+ (1,0) [0|65535] "" XXX
 SG_ EVP_LnDrvngVal : 148|8@1+ (1,0) [0|255] "" XXX
 SG_ EVP_LnTtlVal : 156|8@1+ (1,0) [0|255] "" XXX
 SG_ EVP_TimeMilliSecVal : 164|8@1+ (1,0) [0|255] "" XXX
 SG_ EVP_TimeSecVal : 172|8@1+ (1,0) [0|255] "" XXX
 SG_ EVP_TimeMinVal : 180|8@1+ (1,0) [0|255] "" XXX
 SG_ EVP_SysQualStaLat : 188|4@1+ (1,0) [0|15] "" XXX
 SG_ EVP_SysQualStaLong : 192|4@1+ (1,0) [0|15] "" XXX
 SG_ EVP_TimeHrVal : 196|8@1+ (1,0) [0|255] "" XXX
 SG_ EVP_TimeDayVal : 204|8@1+ (1,0) [0|255] "" XXX
 SG_ EVP_TimeMonVal : 212|8@1+ (1,0) [0|255] "" XXX
 SG_ EVP_TimeYrVal : 220|8@1+ (1,0) [0|255] "" XXX
 SG_ EVP_TimeCenturyVal : 228|8@1+ (1,0) [0|255] "" XXX
 SG_ EVP_MEELtRoadEdgeSta : 236|4@1+ (1,0) [0|15] "" XXX
 SG_ EVP_MEERtRoadEdgeSta : 240|4@1+ (1,0) [0|15] "" XXX
 SG_ EVP_MEERoadLnSta : 244|4@1+ (1,0) [0|15] "" XXX
 SG_ WD_CMR_LVDSPathResetReqSta : 248|8@1+ (1,0) [0|255] "" XXX

BO_ 727 HDM_01_200ms: 8 XXX
 SG_ HDM_Crc1Val : 0|16@1+ (1,0) [0|65535] "" XXX
 SG_ HDM_AlvCnt1Val : 16|16@1+ (1,0) [0|65535] "" XXX
 SG_ HDM_PathID : 32|32@1+ (1,0) [0|4294967295] "" XXX
 SG_ HDM_Offset : 64|40@1+ (1,0) [0|1099511627775] "" XXX
 SG_ HDM_LateralOffset : 104|16@1+ (1,0) [0|65535] "" XXX
 SG_ HDM_Speed : 120|8@1+ (1,0) [0|255] "" XXX
 SG_ HDM_RelativeHeading : 128|24@1+ (1,0) [0|16777215] "" XXX
 SG_ HDM_CurrentLane : 152|8@1+ (1,0) [0|255] "" XXX
 SG_ HDM_PreferredPath : 160|32@1+ (1,0) [0|4294967295] "" XXX
 SG_ HDM_TimeStamp : 192|32@1+ (1,0) [0|4294967295] "" XXX
 SG_ HDM_PositionAge : 224|8@1+ (1,0) [0|255] "" XXX

BO_ 728 HDM_02_200ms: 8 XXX
 SG_ HDM_Crc2Val : 0|16@1+ (1,0) [0|65535] "" XXX
 SG_ HDM_AlvCnt2Val : 16|8@1+ (1,0) [0|255] "" XXX
 SG_ HDM_Simulating : 24|2@1+ (1,0) [0|3] "" XXX
 SG_ HDM_Guidance : 26|4@1+ (1,0) [0|15] "" XXX
 SG_ HDM_GuidanceState : 30|4@1+ (1,0) [0|15] "" XXX
 SG_ HDM_SystemState : 34|4@1+ (1,0) [0|15] "" XXX
 SG_ HDM_MapState : 38|4@1+ (1,0) [0|15] "" XXX
 SG_ HDM_HDMapSupport : 42|2@1+ (1,0) [0|3] "" XXX
 SG_ HDM_HDPSpprtSWVer : 44|4@1+ (1,0) [0|15] "" XXX

BO_ 729 HDM_03_200ms: 8 XXX
 SG_ HDM_Crc3Val : 0|16@1+ (1,0) [0|65535] "" XXX
 SG_ HDM_AlvCnt3Val : 16|16@1+ (1,0) [0|65535] "" XXX
 SG_ HDM_SwVerMajor : 32|8@1+ (1,0) [0|255] "" XXX
 SG_ HDM_SwVerMinor1 : 40|8@1+ (1,0) [0|255] "" XXX
 SG_ HDM_SwVerMinor2 : 48|8@1+ (1,0) [0|255] "" XXX
 SG_ HDM_RespMode : 56|8@1+ (1,0) [0|255] "" XXX
 SG_ HDM_CensoringNo1 : 64|16@1+ (1,0) [0|65535] "" XXX
 SG_ HDM_CensoringNo2 : 80|48@1+ (1,0) [0|281474976710655] "" XXX
 SG_ HDM_CensoringNo3 : 128|56@1+ (1,0) [0|7.20575940379279e+16] "" XXX
 SG_ HDM_RespReserved : 184|8@1+ (1,0) [0|255] "" XXX

CM_ SG_ 512 SCCMode_OptUsmSta "I am not sure why this is here too (though all indicates this is should exist here), and why the val is diff from SCC_ML_OnOffEquiSta.";
CM_ SG_ 512 SCCML_LearningChar1Sta "SCCMLAccelerationLevel";
CM_ SG_ 512 SCCML_LearningChar2Sta "SCCMLVehicleDistanceLevel";
CM_ SG_ 512 SCCML_LearningChar3Sta "SCCMLResponseSpeedLevel";
CM_ SG_ 512 SCC_ML_OnOffEquipSta "AKA SCCMode_OptUsmSta ?";
VAL_ 512 SCCMode_OptUsmSta 1 "Driving Mode" 2 "SCC-ML" 3 "Invalid";
VAL_ 512 SCC_Char1Sta 0 "Default" 1 "Level 1" 2 "Level 2" 3 "Level 3" 4 "Level 4" 5 "Level 5";
VAL_ 512 SCCML_LearningChar1Sta 1 "Level 1" 2 "Level 2" 3 "Level 3" 4 "Level 4" 5 "Level 5";
VAL_ 512 SCCML_LearningChar2Sta 1 "Level 1" 2 "Level 2" 3 "Level 3" 4 "Level 4";
VAL_ 512 SCCML_LearningChar3Sta 1 "Level 1" 2 "Level 2" 3 "Level 3" 4 "Level 4" 5 "Level 5";
VAL_ 512 SCC_ML_OnOffEquipSta 1 "Driving Mode" 2 "SCC-ML" 3 "Invalid";
VAL_ 512 SCC_Char2Sta 0 "Default" 1 "Level 1" 2 "Level 2" 3 "Level 3" 4 "Level 4" 5 "Level 5";
VAL_ 512 SCC_Char3Sta 0 "Default" 1 "Level 1" 2 "Level 2" 3 "Level 3" 4 "Level 4" 5 "Level 5";
